VERSION ""

NS_ :

BS_:

BU_: SGW RFHM MPAD IPC GNMM EVCU2 ESL ECM DTCM DMSM BSM BCM AGSM ADCAM

BO_ 1470 BCM_FD_29: 32 BCM
 SG_ MessageCounter_BCM29 : 179|4@0+ (1,0) [0|15] "-"  MPAD
 SG_ DriverSeatRelativePosition : 95|8@0+ (1,-100) [-100|100] "%"  MPAD
 SG_ DriverSeatReclinerButton : 181|2@0+ (1,0) [0|2] "" MPAD
 SG_ DriverSeatHorizontalButton : 183|2@0+ (1,0) [0|2] "" MPAD
 SG_ DriverReclineRelativePosition : 103|8@0+ (1,-100) [-100|100] "%"  MPAD
 SG_ CRC_BCM29 : 191|8@0+ (1,0) [0|255] "-"  MPAD
 SG_ SeatPosHAS : 70|2@0+ (1,0) [0|3] "" MPAD

BO_ 1458 ADAS_FD_HMI_C2: 32 BCM
 SG_ MessageCounter_ADAS_HMI_C2 : 179|4@0+ (1,0) [0|15] "-"  BSM,IPC
 SG_ CRC_ADAS_HMI_C2 : 191|8@0+ (1,0) [0|255] "-"  BSM,IPC
 SG_ ACC_FailSts_C2 : 57|1@0+ (1,0) [0|1] "" BSM
 SG_ SVI_Request_C2_ext : 82|3@0+ (1,0) [0|7] "-"  IPC

BO_ 2564682036 DIAGNOSTIC_ROE_GNMM: 8 GNMM
 SG_ N_PDU : 7|64@0+ (1,0) [0|0] "" SGW

BO_ 2564682292 DIAGNOSTIC_ROE_FD_GNMM: 64 GNMM
 SG_ N_PDU : 7|64@0+ (1,0) [0|0] "" SGW

BO_ 2564682391 DIAGNOSTIC_ROE_FD_DMSM: 64 DMSM
 SG_ N_PDU : 7|64@0+ (1,0) [0|0] "" SGW

BO_ 2564682135 DIAGNOSTIC_ROE_DMSM: 8 DMSM
 SG_ N_PDU : 7|64@0+ (1,0) [0|0] "" SGW

BO_ 2564486416 DIAGNOSTIC_RESPONSE_FOTA_ECM: 64 ECM
 SG_ N_PDU : 7|64@0+ (1,0) [0|0] "" SGW

BO_ 2564486440 DIAGNOSTIC_RESPONSE_FOTA_BSM: 64 BSM
 SG_ N_PDU : 7|64@0+ (1,0) [0|0] "" SGW

BO_ 2564428021 DIAGNOSTIC_REQUEST_FOTA_ECM: 64 SGW
 SG_ N_PDU : 7|64@0+ (1,0) [0|0] "" ECM

BO_ 2564434165 DIAGNOSTIC_REQUEST_FOTA_BSM: 64 SGW
 SG_ N_PDU : 7|64@0+ (1,0) [0|0] "" BSM

BO_ 161 DBSM2_A1: 32 BCM
 SG_ undervoltage_detected : 5|1@0+ (1,0) [0|1] "" MPAD
 SG_ switch_status_OpenClose : 0|1@0+ (1,0) [0|1] "" MPAD
 SG_ RsErr_DBSM2 : 7|1@0+ (1,0) [0|1] "" MPAD
 SG_ overtemp_detected : 2|1@0+ (1,0) [0|1] "" MPAD
 SG_ overcurrent_detected : 4|1@0+ (1,0) [0|1] "" MPAD
 SG_ L2plus_ack : 6|1@0+ (1,0) [0|1] "" MPAD
 SG_ ESS_input_active : 1|1@0+ (1,0) [0|1] "" Vector__XXX
 SG_ DBSM2_internal_error : 3|1@0+ (1,0) [0|1] "" MPAD
 SG_ BATTERY2_voltage : 23|8@0+ (0.05,6) [6|18.7] "" Vector__XXX
 SG_ BATTERY_voltage : 15|8@0+ (0.05,6) [6|18.7] "" Vector__XXX
 SG_ MC_DBSM2_1 : 55|4@0+ (1,0) [0|15] "" MPAD
 SG_ CRC_DBSM2_1 : 63|8@0+ (1,0) [0|0] "" MPAD

BO_ 281 ADAS_FD_INFO_C2: 32 BCM
 SG_ MRM_STATUS_C2 : 52|3@0+ (1,0) [0|6] "" EVCU2,IPC
 SG_ MessageCounter_ADAS_INFO_C2 : 179|4@0+ (1,0) [0|15] "-"  BSM,IPC,EVCU2
 SG_ HAS_Status_C2 : 35|2@0+ (1,0) [0|3] "" BSM,IPC,DTCM
 SG_ CRC_ADAS_INFO_C2 : 191|8@0+ (1,0) [0|255] "-"  BSM,IPC,EVCU2
 SG_ AEB_Type_C2 : 39|4@0+ (1,0) [0|14] "" BSM
 SG_ Intervention_C2 : 3|12@0+ (0.01,-16) [-16|24.95] "m/s2"  BSM
 SG_ HIS_Req_C2 : 19|1@0+ (1,0) [0|1] "" BSM
 SG_ ACC_Systemsts_C2 : 23|4@0+ (1,0) [0|14] "" BSM
 SG_ CADM2_Mode : 33|1@0+ (1,0) [0|1] "" BSM

BO_ 280 ADAS_FD_INFO: 32 ADCAM
 SG_ Object_Dist : 127|8@0+ (1,0) [0|255] "m"  BCM,BSM
 SG_ MessageCounter_ADAS_FD_INFO : 179|4@0+ (1,0) [0|15] "-"  ADCAM,EVCU2,BCM,BSM,IPC
 SG_ CRC_ADAS_FD_INFO : 191|8@0+ (1,0) [0|255] "-"  ADCAM,EVCU2,BCM,BSM,IPC
 SG_ Intervention : 163|12@0+ (0.01,-16) [-16|24.95] "m/s2"  SGW,BCM,BSM
 SG_ HIS_Req : 89|1@0+ (1,0) [0|1] "-"  BCM,BSM
 SG_ GrMax_Rq_ACC : 150|4@0+ (1,0) [0|15] "-"  BCM,BSM
 SG_ CIPV_Fused : 101|1@0+ (1,0) [0|1] "-"  BCM,BSM
 SG_ Brake_Jerk_Req : 100|1@0+ (1,0) [0|1] "-"  BCM,BSM
 SG_ ACC_Engine_Torque_Enabled : 111|1@0+ (1,0) [0|1] "-"  BCM,BSM
 SG_ ACC_Drive_Cmd : 151|1@0+ (1,0) [0|1] "-"  BCM,BSM
 SG_ Prefill_Req : 91|1@0+ (1,0) [0|1] "-"  BCM,BSM
 SG_ PEB_SystemSts : 90|1@0+ (1,0) [0|1] "-"  BCM,BSM,IPC
 SG_ MRM_STATUS : 23|3@0+ (1,0) [0|6] "" EVCU2,SGW,BCM,BSM,IPC
 SG_ LANE_CHANGE_SIDE : 95|2@0+ (1,0) [0|2] "" BCM,BSM,IPC
 SG_ HAS_Status : 106|2@0+ (1,0) [0|3] "" BCM,BSM,IPC,DTCM
 SG_ HAS_OpStat_Prim : 4|3@0+ (1,0) [0|5] "" BCM,BSM
 SG_ HAS_LAT_CTRL_RequestSts : 110|2@0+ (1,0) [0|3] "-"  BCM,BSM
 SG_ ESCALATION_TYPE : 12|3@0+ (1,0) [0|4] "" BCM,BSM
 SG_ DDD_SystemSts : 103|1@0+ (1,0) [0|1] "-"  BCM,BSM
 SG_ DDD_Setting_Avail : 102|1@0+ (1,0) [0|1] "-"  BCM,BSM,IPC
 SG_ CADM_OpStat : 7|3@0+ (1,0) [0|5] "" BCM,BSM
 SG_ AEB_Type : 167|4@0+ (1,0) [0|14] "-"  BCM,BSM
 SG_ AEB_Systemsts : 99|2@0+ (1,0) [0|2] "-"  BCM,BSM,IPC
 SG_ AEB_Sensitivity_Setting : 1|2@0+ (1,0) [0|2] "" BCM,BSM,IPC
 SG_ ACC_Systemsts : 183|4@0+ (1,0) [0|14] "-"  BCM,BSM,IPC
 SG_ ACC_StopStart : 97|2@0+ (1,0) [0|2] "-"  BCM,BSM
 SG_ SteeringVibration_Type : 67|4@0+ (1,0) [0|14] "-"  BCM,BSM
 SG_ SteeringVibration_Rq : 135|1@0+ (1,0) [0|1] "-"  BCM,BSM
 SG_ LKA_LAT_CTRL_RequestSts : 108|2@0+ (1,0) [0|3] "-"  BCM,BSM
 SG_ LANE_CHANGE_STATUS : 71|4@0+ (1,0) [0|14] "" BCM,BSM,IPC
 SG_ SeatVib_Req : 15|3@0+ (1,0) [0|7] "" BCM,BSM
 SG_ LC_Jerk : 104|1@0+ (1,0) [0|1] "-"  BCM,BSM
 SG_ CADM2_EPSSEC_FAIL : 8|1@0+ (1,0) [0|1] "" BCM,BSM
 SG_ BlindSpot_TrailerSts : 20|3@0+ (1,0) [0|6] "-"  BCM,BSM,IPC
 SG_ TorqueOverlaySteeringReq : 130|11@0+ (0.0048828125,-5) [-5|4.995117188] "-"  BCM,BSM
 SG_ MAC_ADAS_FD_INFO : 215|48@0+ (1,0) [0|0] "-"  BCM,BSM
 SG_ Cntr_ADAS_FD_INFO : 199|16@0+ (1,0) [0|65535] "-"  BCM,BSM

BO_ 525 GLOB_NAV_FD: 64 GNMM
 SG_ VerticalAcceleration_GNMM : 35|12@0+ (0.02,-40.96) [-40.96|40.92] "m/s2"  MPAD,BCM
 SG_ RollRate_GNMM : 67|12@0+ (0.08,-163.84) [-163.84|163.68] "deg/s"  MPAD,BCM
 SG_ PitchRate_GNMM : 83|12@0+ (0.08,-163.84) [-163.84|163.68] "deg/s"  MPAD,BCM
 SG_ LongAcceleration_GNMM : 3|12@0+ (0.02,-40.96) [-40.96|40.92] "m/s2"  MPAD,BCM
 SG_ LatAcceleration_GNMM : 19|12@0+ (0.02,-40.96) [-40.96|40.92] "m/s2"  MPAD,BCM
 SG_ GNMM_Health : 7|4@0+ (1,0) [0|6] "" MPAD,BCM
 SG_ YawRate_RMSE : 119|8@0+ (2,0) [0|506] "deg"  MPAD,BCM
 SG_ Roll_RMSE : 151|8@0+ (2,0) [0|506] "deg"  MPAD,BCM
 SG_ Pitch_RMSE : 159|8@0+ (2,0) [0|506] "deg"  MPAD,BCM
 SG_ Longitude_RMSE : 111|8@0+ (2,0) [0|506] "cm"  MPAD,BCM
 SG_ Latitude_RMSE : 103|8@0+ (2,0) [0|506] "cm"  MPAD,BCM
 SG_ Heading_Angle : 127|16@0+ (0.01,0) [0|360] "deg"  MPAD,BCM
 SG_ Altitude_RMSE : 143|8@0+ (2,0) [0|506] "cm"  MPAD,BCM
 SG_ YawRate_GNMM : 166|15@0+ (0.01,-163.83) [-163.83|163.83] "deg/s"  MPAD,BCM
 SG_ VerticalVelocity_GNMM : 197|14@0+ (0.01,-81.92) [-81.92|81.9] "m/s"  MPAD,BCM
 SG_ MessageCounter_GLOB_NAV : 435|4@0+ (1,0) [0|15] "-"  MPAD,BCM
 SG_ LongitudinalVelocity_GNMM : 213|14@0+ (0.01,-81.92) [-81.92|81.9] "m/s"  MPAD,BCM
 SG_ LateralVelocity_GNMM : 181|14@0+ (0.01,-81.92) [-81.92|81.9] "m/s"  MPAD,BCM
 SG_ CRC_GLOB_NAV : 447|8@0+ (1,0) [0|255] "-"  MPAD,BCM
 SG_ Long_GNMM : 327|32@0+ (1E-07,-180) [-180|249.4967294] "deg"  MPAD,BCM
 SG_ Lat_GNMM : 407|32@0+ (5E-08,-90) [-90|124.7483647] "deg"  MPAD,BCM
 SG_ TimeStamp : 231|44@0+ (1,0) [0|17592186044415] "ms"  MPAD
 SG_ StbmTimestampSec_GNMM : 359|32@0+ (1,0) [0|4294967295] "sec"  MPAD
 SG_ StbmTimestampNSec_GNMM : 295|32@0+ (1,0) [0|4294967295] "nsec"  MPAD
 SG_ StbmSyncState_GNMM : 391|8@0+ (1,0) [0|255] "No_Unit"  MPAD
 SG_ StatusReceiver : 21|2@0+ (1,0) [0|3] "No_Unit"  MPAD
 SG_ NumOfSatellites : 267|4@0+ (1,0) [0|15] "No_Unit"  MPAD
 SG_ IMUTemperature : 59|8@0+ (1,-40) [-40|215] "Celsius"  MPAD
 SG_ HDOP : 55|12@0+ (0.01,0) [0|40.95] "No_Unit"  MPAD
 SG_ FixedStatusReceiver : 23|2@0+ (1,0) [0|3] "No_Unit"  MPAD
 SG_ CourseAngle : 279|16@0+ (0.01,0) [0|655.35] "deg"  MPAD
 SG_ Reserved_Func_Safety_GLOBNAV_2 : 439|4@0+ (1,0) [0|0] "" MPAD,BCM
 SG_ Reserved_for_Func_Safety_GLOBNAV : 399|8@0+ (1,0) [0|0] "" MPAD,BCM
 SG_ MAC_GLOB_NAV : 471|48@0+ (1,0) [0|0] "-"  MPAD,BCM
 SG_ Cntr_GLOB_NAV : 455|16@0+ (1,0) [0|0] "-"  MPAD,BCM

BO_ 2564682005 DIAGNOSTIC_ROE_MCPB: 8 EVCU2
 SG_ N_PDU : 7|64@0+ (1,0) [0|0] "" SGW

BO_ 2564682004 DIAGNOSTIC_ROE_MCPA: 8 EVCU2
 SG_ N_PDU : 7|64@0+ (1,0) [0|0] "" SGW

BO_ 2564682261 DIAGNOSTIC_ROE_FD_MCPB: 64 EVCU2
 SG_ N_PDU : 7|64@0+ (1,0) [0|0] "" SGW

BO_ 2564682260 DIAGNOSTIC_ROE_FD_MCPA: 64 EVCU2
 SG_ N_PDU : 7|64@0+ (1,0) [0|0] "" SGW

BO_ 2564485396 DIAGNOSTIC_RESPONSE_MCPA: 8 EVCU2
 SG_ N_PDU : 7|64@0+ (1,0) [0|0] "" SGW

BO_ 2564485653 DIAGNOSTIC_RESPONSE_FD_MCPB: 64 EVCU2
 SG_ N_PDU : 7|64@0+ (1,0) [0|0] "" SGW

BO_ 2564485652 DIAGNOSTIC_RESPONSE_FD_MCPA: 64 EVCU2
 SG_ N_PDU : 7|64@0+ (1,0) [0|0] "" SGW

BO_ 2564429297 DIAGNOSTIC_REQUEST_MCPB: 8 SGW
 SG_ N_PDU : 7|64@0+ (1,0) [0|0] "" EVCU2

BO_ 2564429041 DIAGNOSTIC_REQUEST_MCPA: 8 SGW
 SG_ N_PDU : 7|64@0+ (1,0) [0|0] "" EVCU2

BO_ 2564429298 DIAGNOSTIC_REQUEST_FD_MCPB: 64 SGW
 SG_ N_PDU : 7|64@0+ (1,0) [0|0] "" EVCU2

BO_ 2564429042 DIAGNOSTIC_REQUEST_FD_MCPA: 64 SGW
 SG_ N_PDU : 7|64@0+ (1,0) [0|0] "" EVCU2

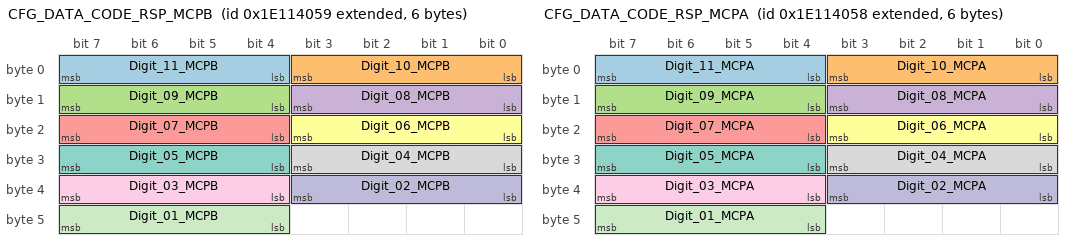
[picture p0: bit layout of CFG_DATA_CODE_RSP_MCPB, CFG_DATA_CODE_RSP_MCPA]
BO_ 2651930713 CFG_DATA_CODE_RSP_MCPB: 6 EVCU2
 SG_ Digit_11_MCPB : 7|4@0+ (1,0) [0|15] "-"  BCM
 SG_ Digit_10_MCPB : 3|4@0+ (1,0) [0|15] "-"  BCM
 SG_ Digit_09_MCPB : 15|4@0+ (1,0) [0|15] "-"  BCM
 SG_ Digit_08_MCPB : 11|4@0+ (1,0) [0|15] "-"  BCM
 SG_ Digit_07_MCPB : 23|4@0+ (1,0) [0|15] "-"  BCM
 SG_ Digit_06_MCPB : 19|4@0+ (1,0) [0|15] "-"  BCM
 SG_ Digit_05_MCPB : 31|4@0+ (1,0) [0|15] "-"  BCM
 SG_ Digit_04_MCPB : 27|4@0+ (1,0) [0|15] "-"  BCM
 SG_ Digit_03_MCPB : 39|4@0+ (1,0) [0|15] "-"  BCM
 SG_ Digit_02_MCPB : 35|4@0+ (1,0) [0|15] "-"  BCM
 SG_ Digit_01_MCPB : 47|4@0+ (1,0) [0|15] "-"  BCM

BO_ 2651930712 CFG_DATA_CODE_RSP_MCPA: 6 EVCU2
 SG_ Digit_11_MCPA : 7|4@0+ (1,0) [0|15] "-"  BCM
 SG_ Digit_10_MCPA : 3|4@0+ (1,0) [0|15] "-"  BCM
 SG_ Digit_09_MCPA : 15|4@0+ (1,0) [0|15] "-"  BCM
 SG_ Digit_08_MCPA : 11|4@0+ (1,0) [0|15] "-"  BCM
 SG_ Digit_07_MCPA : 23|4@0+ (1,0) [0|15] "-"  BCM
 SG_ Digit_06_MCPA : 19|4@0+ (1,0) [0|15] "-"  BCM
 SG_ Digit_05_MCPA : 31|4@0+ (1,0) [0|15] "-"  BCM
 SG_ Digit_04_MCPA : 27|4@0+ (1,0) [0|15] "-"  BCM
 SG_ Digit_03_MCPA : 39|4@0+ (1,0) [0|15] "-"  BCM
 SG_ Digit_02_MCPA : 35|4@0+ (1,0) [0|15] "-"  BCM
 SG_ Digit_01_MCPA : 47|4@0+ (1,0) [0|15] "-"  BCM

BO_ 2564485397 DIAGNOSTIC_RESPONSE_MCPB: 8 EVCU2
 SG_ N_PDU : 7|64@0+ (1,0) [0|0] "" SGW

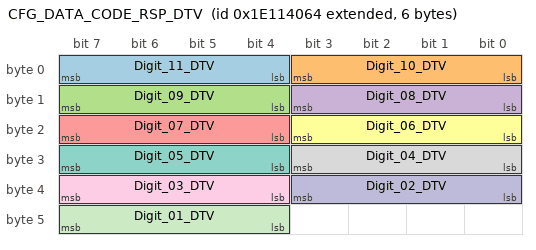
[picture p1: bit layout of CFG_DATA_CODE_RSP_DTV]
BO_ 2651930724 CFG_DATA_CODE_RSP_DTV: 6 SGW
 SG_ Digit_11_DTV : 7|4@0+ (1,0) [0|15] "-"  BCM
 SG_ Digit_10_DTV : 3|4@0+ (1,0) [0|15] "-"  BCM
 SG_ Digit_09_DTV : 15|4@0+ (1,0) [0|15] "-"  BCM
 SG_ Digit_08_DTV : 11|4@0+ (1,0) [0|15] "-"  BCM
 SG_ Digit_07_DTV : 23|4@0+ (1,0) [0|15] "-"  BCM
 SG_ Digit_06_DTV : 19|4@0+ (1,0) [0|15] "-"  BCM
 SG_ Digit_05_DTV : 31|4@0+ (1,0) [0|15] "-"  BCM
 SG_ Digit_04_DTV : 27|4@0+ (1,0) [0|15] "-"  BCM
 SG_ Digit_03_DTV : 39|4@0+ (1,0) [0|15] "-"  BCM
 SG_ Digit_02_DTV : 35|4@0+ (1,0) [0|15] "-"  BCM
 SG_ Digit_01_DTV : 47|4@0+ (1,0) [0|15] "-"  BCM

BO_ 728 VL_Object: 64 ADCAM
 SG_ Road_Illumination : 127|4@0+ (1,0) [0|15] "-"  BCM
 SG_ Obj04_Type : 111|4@0+ (1,0) [0|15] "-"  BCM
 SG_ Obj04_HorDist : 247|8@0+ (2,0) [0|510] "m"  BCM
 SG_ Obj03_Type : 71|4@0+ (1,0) [0|15] "-"  BCM
 SG_ Obj03_HorDist : 175|8@0+ (2,0) [0|510] "m"  BCM
 SG_ Obj02_Type : 55|4@0+ (1,0) [0|15] "-"  BCM
 SG_ Obj02_HorDist : 103|8@0+ (2,0) [0|510] "m"  BCM
 SG_ Obj01_Type : 39|4@0+ (1,0) [0|15] "-"  BCM
 SG_ Obj01_HorDist : 31|8@0+ (2,0) [0|510] "m"  BCM
 SG_ Cam_TrafficStyle : 19|4@0+ (1,0) [0|15] "-"  BCM
 SG_ Cam_Status : 23|4@0+ (1,0) [0|15] "-"  BCM
 SG_ Cam_SelfGlaring : 11|4@0+ (1,0) [0|15] "-"  BCM
 SG_ Cam_ObjNum : 15|4@0+ (1,0) [0|15] "-"  BCM
 SG_ Cam_Env : 3|4@0+ (1,0) [0|15] "-"  BCM
 SG_ Cam_AmbientLight : 7|4@0+ (1,0) [0|15] "-"  BCM
 SG_ Obj04_VerPos : 311|8@0+ (0.1,-12) [-12|13.5] "°"  BCM
 SG_ Obj04_ID : 303|8@0+ (1,0) [0|255] "-"  BCM
 SG_ Obj04_HorSpeed : 283|12@0+ (0.05,-40) [-40|164.75] "°/s"  BCM
 SG_ Obj04_HorPosRight : 267|12@0+ (0.05,-40) [-40|164.75] "°"  BCM
 SG_ Obj04_HorPosLeft : 251|12@0+ (0.05,-40) [-40|164.75] "°"  BCM
 SG_ Obj03_VerPos : 239|8@0+ (0.1,-12) [-12|13.5] "°"  BCM
 SG_ Obj03_ID : 231|8@0+ (1,0) [0|255] "-"  BCM
 SG_ Obj03_HorSpeed : 211|12@0+ (0.05,-40) [-40|164.75] "°/s"  BCM
 SG_ Obj03_HorPosRight : 195|12@0+ (0.05,-40) [-40|164.75] "°"  BCM
 SG_ Obj03_HorPosLeft : 179|12@0+ (0.05,-40) [-40|164.75] "°"  BCM
 SG_ Obj02_VerPos : 167|8@0+ (0.1,-12) [-12|13.5] "°"  BCM
 SG_ Obj02_ID : 159|8@0+ (1,0) [0|255] "-"  BCM
 SG_ Obj02_HorSpeed : 139|12@0+ (0.05,-40) [-40|164.75] "°/s"  BCM
 SG_ Obj02_HorPosRight : 123|12@0+ (0.05,-40) [-40|164.75] "°"  BCM
 SG_ Obj02_HorPosLeft : 107|12@0+ (0.05,-40) [-40|164.75] "°"  BCM
 SG_ Obj01_VerPos : 95|8@0+ (0.1,-12) [-12|13.5] "°"  BCM
 SG_ Obj01_ID : 87|8@0+ (1,0) [0|255] "-"  BCM
 SG_ Obj01_HorSpeed : 67|12@0+ (0.05,-40) [-40|164.75] "°/s"  BCM
 SG_ Obj01_HorPosRight : 51|12@0+ (0.05,-40) [-40|164.75] "°"  BCM
 SG_ Obj01_HorPosLeft : 35|12@0+ (0.05,-40) [-40|164.75] "°"  BCM

BO_TX_BU_ 280 : ADCAM,MPAD;
CM_ SG_ 1470 SeatPosHAS "SeatPosHAS";
CM_ SG_ 1470 MessageCounter_BCM29 "This signal is a counter used for safety checks strategies. This counter is incremented of 1 (one) unit at each frame transmission.";
CM_ SG_ 1470 DriverSeatRelativePosition "Relative position of the driver seat since highway assist was engaged";
CM_ SG_ 1470 DriverSeatReclinerButton "Driver seat recliner button press";
CM_ SG_ 1470 DriverSeatHorizontalButton "Driver seat horizontal button press";
CM_ SG_ 1470 DriverReclineRelativePosition "Relative position of the driver recliner since highway assist was engaged";
CM_ SG_ 1470 CRC_BCM29 "CRC according to SAE J1850 standard at each frame transmission.";
CM_ SG_ 1458 MessageCounter_ADAS_HMI_C2 "This signal is a counter used for safety checks strategies. This counter is incremented of 1 (one) unit at each frame transmission.";
CM_ SG_ 1458 SVI_Request_C2_ext "Cluster Glow";
CM_ SG_ 1458 CRC_ADAS_HMI_C2 "CRC according to SAE J1850 standard at each frame transmission.";
CM_ SG_ 1458 ACC_FailSts_C2 "ACC_FailSts_C2";
CM_ SG_ 2564682036 N_PDU "This signal is used for diagnostic purposes";
CM_ SG_ 2564682292 N_PDU "This signal is used for diagnostic purposes";
CM_ SG_ 2564682391 N_PDU "This signal is used for diagnostic purposes";
CM_ SG_ 2564682135 N_PDU "This signal is used for diagnostic purposes";
CM_ SG_ 2564486416 N_PDU "This signal is used for diagnostic purposes";
CM_ SG_ 2564486440 N_PDU "This signal is used for diagnostic purposes";
CM_ SG_ 2564428021 N_PDU "This signal is used for diagnostic purposes";
CM_ SG_ 2564434165 N_PDU "This signal is used for diagnostic purposes";
CM_ SG_ 161 BATTERY_voltage "input voltage 1 measured by DBSM2";
CM_ SG_ 161 BATTERY2_voltage "input voltage 2 measured by DBSM2";
CM_ SG_ 161 CRC_DBSM2_1 "CRC-checksum byte 1 to 7 according to SAE J1850";
CM_ SG_ 161 DBSM2_internal_error "memory/CPU/sensors (fault flag)";
CM_ SG_ 161 ESS_input_active "ESS input was active (low) during the last 10 seconds";
CM_ SG_ 161 L2plus_ack "DBSM2 confirms L2plus mode";
CM_ SG_ 161 MC_DBSM2_1 "Message counter";
CM_ SG_ 161 overcurrent_detected "over current detected (fault flag)";
CM_ SG_ 161 overtemp_detected "over temperature detected (fault flag)";
CM_ SG_ 161 RsErr_DBSM2 "Response error DBSM2; Error=[1]";
CM_ SG_ 161 switch_status_OpenClose "The switch was activated (open) at least one time during the last 10 seconds";
CM_ SG_ 161 undervoltage_detected "under voltage detected (fault flag)";
CM_ SG_ 281 Intervention_C2 "Intervention_C2";
CM_ SG_ 281 MessageCounter_ADAS_INFO_C2 "This signal is a counter used for safety checks strategies. This counter is incremented of 1 (one) unit at each frame transmission.";
CM_ SG_ 281 MRM_STATUS_C2 "Status of the minimum risk maneuver to handle system faults or driver abuse as understood by secondary controller";
CM_ SG_ 281 HAS_Status_C2 "Highway Assist System Status as reported by the failover controller";
CM_ SG_ 281 HIS_Req_C2 "HIS_Req_C2";
CM_ SG_ 281 CADM2_Mode "Mode CADM2 is currently functioning";
CM_ SG_ 281 CRC_ADAS_INFO_C2 "CRC according to SAE J1850 standard at each frame transmission.";
CM_ SG_ 281 ACC_Systemsts_C2 "ACC_Systemsts_C2";
CM_ SG_ 281 AEB_Type_C2 "AEB_Type_C2";
CM_ SG_ 280 ACC_StopStart "Allows StopStart when ACC is engaged";
CM_ SG_ 280 ACC_Drive_Cmd "ACC Drive Command";
CM_ SG_ 280 ACC_Engine_Torque_Enabled "An enable bit that Torque commands should be followed";
CM_ SG_ 280 ACC_Systemsts "ACC System Status";
CM_ SG_ 280 AEB_Sensitivity_Setting "AEB sensitivity status";
CM_ SG_ 280 AEB_Systemsts "AEB System Status";
CM_ SG_ 280 BlindSpot_TrailerSts "BlindSpot_TrailerSts";
CM_ SG_ 280 AEB_Type "AEB Type";
CM_ SG_ 280 Cntr_ADAS_FD_INFO "Cntr";
CM_ SG_ 280 Brake_Jerk_Req "Request from DASM to perform Jerk Warning";
CM_ SG_ 280 CADM_OpStat "Capability of primary controller to sense and compute a valid trajectory path based on external data dependencies and internal failures";
CM_ SG_ 280 CADM2_EPSSEC_FAIL "CADM2 detection of failure to communicate to EPS";
CM_ SG_ 280 CIPV_Fused "Closest in-path vehicle is fused True = 1";
CM_ SG_ 280 CRC_ADAS_FD_INFO "CRC according to SAE J1850 standard at each frame transmission.";
CM_ SG_ 280 HAS_OpStat_Prim "Capability of the primary controller to perform sensing, computing, and actuation";
CM_ SG_ 280 DDD_Setting_Avail "DDD_Setting Av Status";
CM_ SG_ 280 DDD_SystemSts "DDD System Status";
CM_ SG_ 280 ESCALATION_TYPE "Type of HMI escalation to be provided to driver from primary controller";
CM_ SG_ 280 GrMax_Rq_ACC "Used to request Max Gear from TCM";
CM_ SG_ 280 HAS_LAT_CTRL_RequestSts "HAS_LAT_CTRL_RequestSts";
CM_ SG_ 280 LC_Jerk "Lane Centering request for brake jerk";
CM_ SG_ 280 LKA_LAT_CTRL_RequestSts "LKA_LAT_CTRL_RequestSts";
CM_ SG_ 280 MessageCounter_ADAS_FD_INFO "This signal is a counter used for safety checks strategies. This counter is incremented of 1 (one) unit at each frame transmission.";
CM_ SG_ 280 Object_Dist "It indicates the distance to the recognized object";
CM_ SG_ 280 MRM_STATUS "Status of the minimum risk maneuver to handle system faults or driver abuse as understood by primary controller";
CM_ SG_ 280 HAS_Status "Highway Assist System Status as reported by the main controller";
CM_ SG_ 280 HIS_Req "Used to command Stop during Stop and Go ACC and FSFCW+";
CM_ SG_ 280 Intervention "Request to set target acceleration/deceleration for any feature";
CM_ SG_ 280 LANE_CHANGE_STATUS "Status of assisted lane change maneuver";
CM_ SG_ 280 LANE_CHANGE_SIDE "Direction of the currently in-progress lane change from a vehicle perspective";
CM_ SG_ 280 MAC_ADAS_FD_INFO "MAC";
CM_ SG_ 280 PEB_SystemSts "PEB System Status";
CM_ SG_ 280 Prefill_Req "Prefill command of Brake System by DASM";
CM_ SG_ 280 SeatVib_Req "Seat vibration request";
CM_ SG_ 280 SteeringVibration_Rq "Request to activate Steering Wheel Vibration";
CM_ SG_ 280 SteeringVibration_Type "Type of Steering Wheel Vibration Request";
CM_ SG_ 280 TorqueOverlaySteeringReq "TorqueOverlaySteeringReq";
CM_ SG_ 525 Altitude_RMSE "Altitude_RMSE";
CM_ SG_ 525 Cntr_GLOB_NAV "-";
CM_ SG_ 525 CourseAngle "Actual direction of motion over ground with respect to True North.";
CM_ SG_ 525 CRC_GLOB_NAV "CRC according to SAE J1850 standard at each frame transmission.";
CM_ SG_ 525 FixedStatusReceiver "This signal indicates the FIX status of the GNSS receiver.2D fix = 2-dimensional position can be calculated (horizontal plane)3D fix = 3-dimensional position can be calculated (including altitude)";
CM_ SG_ 525 GNMM_Health "Reported capability of GNMM to provide positioning and acceleration data";
CM_ SG_ 525 HDOP "Relative accuracy of horizontal position (Horizontal Dilution of Precision).";
CM_ SG_ 525 Heading_Angle "Heading Angle";
CM_ SG_ 525 IMUTemperature "Temperature of Yaw Rate secondary IMU sensor.";
CM_ SG_ 525 Lat_GNMM "Latitude decimal degrees, positive North of the equator";
CM_ SG_ 525 LatAcceleration_GNMM "Lateral Acceleration Value from the GNMM";
CM_ SG_ 525 LateralVelocity_GNMM "Lateral Velocity";
CM_ SG_ 525 Latitude_RMSE "RMS error for Latitude";
CM_ SG_ 525 Long_GNMM "Longitude decimal degrees, positive East of the prime meridian";
CM_ SG_ 525 LongAcceleration_GNMM "Longitudinal Acceleration Value from the GNMM";
CM_ SG_ 525 Longitude_RMSE "RMS error for Longitude";
CM_ SG_ 525 LongitudinalVelocity_GNMM "Longitudinal Velocity";
CM_ SG_ 525 MAC_GLOB_NAV "-";
CM_ SG_ 525 MessageCounter_GLOB_NAV "This signal is a counter used for safety checks strategies. This counter is incremented of 1 (one) unit at each frame transmission.";
CM_ SG_ 525 NumOfSatellites "Number of satellites available, if signal >=14 keep value=14.";
CM_ SG_ 525 Pitch_RMSE "Pitch_RMSE";
CM_ SG_ 525 PitchRate_GNMM "Pitch Rate Value from the GNMM";
CM_ SG_ 525 Roll_RMSE "Roll_RMSE";
CM_ SG_ 525 RollRate_GNMM "Roll Rate Value from the GNMM";
CM_ SG_ 525 StatusReceiver "This signal indicates the status of the GNSS receiver.";
CM_ SG_ 525 StbmSyncState_GNMM "Sync status of the GNMM Stbm";
CM_ SG_ 525 StbmTimestampNSec_GNMM "Timestamp in nanoseconds from the GNMM Stbm, [0 - 999999999].";
CM_ SG_ 525 StbmTimestampSec_GNMM "Timestamp in nanoseconds from the GNMM Stbm,  [0 - 4294967294].";
CM_ SG_ 525 TimeStamp "EPOCH UNIX time - time since 00:00:00 UTC, January 1, 1970 (Unix timestamp) in milliseconds.";
CM_ SG_ 525 VerticalAcceleration_GNMM "Vertical Acceleration Value from the GNMM";
CM_ SG_ 525 VerticalVelocity_GNMM "Vertical Velocity";
CM_ SG_ 525 YawRate_GNMM "Yaw Rate Value from the GNMM";
CM_ SG_ 525 YawRate_RMSE "RMS error for YawRate";
CM_ SG_ 2564682005 N_PDU "This signal is used for diagnostic purposes";
CM_ SG_ 2564682004 N_PDU "This signal is used for diagnostic purposes";
CM_ SG_ 2564682261 N_PDU "This signal is used for diagnostic purposes";
CM_ SG_ 2564682260 N_PDU "This signal is used for diagnostic purposes";
CM_ SG_ 2564485396 N_PDU "This signal is used for diagnostic purposes";
CM_ SG_ 2564485653 N_PDU "This signal is used for diagnostic purposes";
CM_ SG_ 2564485652 N_PDU "This signal is used for diagnostic purposes";
CM_ SG_ 2564429297 N_PDU "This signal is used for diagnostic purposes";
CM_ SG_ 2564429041 N_PDU "This signal is used for diagnostic purposes";
CM_ SG_ 2564429298 N_PDU "This signal is used for diagnostic purposes";
CM_ SG_ 2564429042 N_PDU "This signal is used for diagnostic purposes";
CM_ SG_ 2564485397 N_PDU "This signal is used for diagnostic purposes";
CM_ SG_ 728 Obj04_HorPosLeft "Left horizontal angle of each detected GFHB object representing the most left light source in relation to camera center.Camera shall measure the horizontal angle between the center of the camera (FOE) and the left edge of the most left light s(...)";
CM_ SG_ 728 Obj04_HorPosRight "Right horizontal angle of each detected GFHB object representing the most right light source in relation to camera center.Camera shall measure the horizontal angle between the center of the camera (FOE) and the right edge of the most right lig(...)";
CM_ SG_ 728 Obj04_HorDist "Longitudinal distance of each detected GFHB object.This signal is defining the longitudinal distance in meters between the ego vehicle and the releated GFHB object.";
CM_ SG_ 728 Cam_AmbientLight "Cam_AmbientLight";
CM_ SG_ 728 Cam_Env "CAN_Env";
CM_ SG_ 728 Cam_ObjNum "Cam_ObjNum";
CM_ SG_ 728 Cam_SelfGlaring "Cam_SelfGlaring";
CM_ SG_ 728 Cam_Status "Cam_Status";
CM_ SG_ 728 Cam_TrafficStyle "Cam_TrafficStyle";
CM_ SG_ 728 Obj01_HorDist "Longitudinal distance of each detected GFHB object.This signal is defining the longitudinal distance in meters between the ego vehicle and the releated GFHB object.";
CM_ SG_ 728 Obj01_HorPosLeft "Left horizontal angle of each detected GFHB object representing the most left light source in relation to camera center.Camera shall measure the horizontal angle between the center of the camera (FOE) and the left edge of the most left light s(...)";
CM_ SG_ 728 Obj01_HorPosRight "Right horizontal angle of each detected GFHB object representing the most right light source in relation to camera center.Camera shall measure the horizontal angle between the center of the camera (FOE) and the right edge of the most right lig(...)";
CM_ SG_ 728 Obj01_HorSpeed "Horizontal Speed of the center of each detected GFHB object.";
CM_ SG_ 728 Obj01_ID "Unique ID of each detected GFHB object which will stay the same over lifetime of each object even if it changes the message ID due to the sorting by distanceThe ID of a cluster will be always the ID of the closest (=strongest) vehicle in the c(...)";
CM_ SG_ 728 Obj01_Type "This signal is a counter used for safety checks strategies. This counter is incremented of 1 (one) unit at each frame transmission.";
CM_ SG_ 728 Obj01_VerPos "Vertical angle of each detected GFHB object representing the lowest edge of the lowest light source in relation to camera center";
CM_ SG_ 728 Obj02_HorDist "Longitudinal distance of each detected GFHB object.This signal is defining the longitudinal distance in meters between the ego vehicle and the releated GFHB object.";
CM_ SG_ 728 Obj02_HorPosLeft "Left horizontal angle of each detected GFHB object representing the most left light source in relation to camera center.Camera shall measure the horizontal angle between the center of the camera (FOE) and the left edge of the most left light s(...)";
CM_ SG_ 728 Obj02_HorPosRight "Right horizontal angle of each detected GFHB object representing the most right light source in relation to camera center.Camera shall measure the horizontal angle between the center of the camera (FOE) and the right edge of the most right lig(...)";
CM_ SG_ 728 Obj04_VerPos "Vertical angle of each detected GFHB object representing the lowest edge of the lowest light source in relation to camera center";
CM_ SG_ 728 Obj04_Type "This signal is a counter used for safety checks strategies. This counter is incremented of 1 (one) unit at each frame transmission.";
CM_ SG_ 728 Obj04_ID "Unique ID of each detected GFHB object which will stay the same over lifetime of each object even if it changes the message ID due to the sorting by distanceThe ID of a cluster will be always the ID of the closest (=strongest) vehicle in the c(...)";
CM_ SG_ 728 Obj03_ID "Unique ID of each detected GFHB object which will stay the same over lifetime of each object even if it changes the message ID due to the sorting by distanceThe ID of a cluster will be always the ID of the closest (=strongest) vehicle in the c(...)";
CM_ SG_ 728 Obj03_Type "This signal is a counter used for safety checks strategies. This counter is incremented of 1 (one) unit at each frame transmission.";
CM_ SG_ 728 Obj03_VerPos "Vertical angle of each detected GFHB object representing the lowest edge of the lowest light source in relation to camera center";
CM_ SG_ 728 Obj04_HorSpeed "Horizontal Speed of the center of each detected GFHB object.";
CM_ SG_ 728 Obj02_HorSpeed "Horizontal Speed of the center of each detected GFHB object.";
CM_ SG_ 728 Obj02_ID "Unique ID of each detected GFHB object which will stay the same over lifetime of each object even if it changes the message ID due to the sorting by distanceThe ID of a cluster will be always the ID of the closest (=strongest) vehicle in the c(...)";
CM_ SG_ 728 Obj02_Type "This signal is a counter used for safety checks strategies. This counter is incremented of 1 (one) unit at each frame transmission.";
CM_ SG_ 728 Obj02_VerPos "Vertical angle of each detected GFHB object representing the lowest edge of the lowest light source in relation to camera center";
CM_ SG_ 728 Obj03_HorDist "Longitudinal distance of each detected GFHB object.This signal is defining the longitudinal distance in meters between the ego vehicle and the releated GFHB object.";
CM_ SG_ 728 Obj03_HorPosLeft "Left horizontal angle of each detected GFHB object representing the most left light source in relation to camera center.Camera shall measure the horizontal angle between the center of the camera (FOE) and the left edge of the most left light s(...)";
CM_ SG_ 728 Obj03_HorPosRight "Right horizontal angle of each detected GFHB object representing the most right light source in relation to camera center.Camera shall measure the horizontal angle between the center of the camera (FOE) and the right edge of the most right lig(...)";
CM_ SG_ 728 Obj03_HorSpeed "Horizontal Speed of the center of each detected GFHB object.";
CM_ SG_ 728 Road_Illumination "Road_Illumination";
BA_DEF_ BO_ "CANFD_BRS" ENUM "0","1";
BA_DEF_ BO_ "VFrameFormat" ENUM "StandardCAN","ExtendedCAN","reserved","reserved","reserved","reserved","reserved","reserved","reserved","reserved","reserved","reserved","reserved","reserved","StandardCAN_FD","ExtendedCAN_FD";
BA_DEF_ BO_ "DiagConnection" HEX 0 65535;
BA_DEF_ BO_ "DiagState" ENUM "No","Yes";
BA_DEF_ BO_ "NmAsrMessage" ENUM "No","Yes";
BA_DEF_ BO_ "GenMsgDelayTime" INT 0 65535;
BA_DEF_ BO_ "GenMsgCycleTime" INT 0 65535;
BA_DEF_ BO_ "GenMsgCycleTimeFast" INT 0 65535;
BA_DEF_ BO_ "GenMsgStartDelayTime" INT 0 65535;
BA_DEF_ BO_ "GenMsgILSupport" ENUM "No","Yes";
BA_DEF_ BO_ "GenMsgNrOfRepetition" INT 0 255;
BA_DEF_ BO_ "GenMsgSendType" ENUM "Cyclic","NotUsed","NotUsed","NotUsed","NotUsed","NotUsed","NotUsed","NotUsed","NoMsgSendType";
BA_DEF_ BO_ "NmMessage" ENUM "No","Yes";
BA_DEF_ BO_ "DiagResponse" ENUM "No","Yes";
BA_DEF_ BO_ "Type" ENUM "P","C","PE","COC","PE_Cntrl","E","E_Cntrl","OC","S","BAF","DC","EM","MM","ISO-TP","-";
BA_DEF_ BO_ "DiagRequest" ENUM "No","Yes";
BA_DEF_ SG_ "GenSigTimeoutTime_SGW" INT 0 65535;
BA_DEF_ SG_ "GenSigTimeoutTime_RFHM" INT 0 65535;
BA_DEF_ SG_ "GenSigTimeoutTime_MPAD" INT 0 65535;
BA_DEF_ SG_ "GenSigTimeoutTime_IPC" INT 0 65535;
BA_DEF_ SG_ "GenSigTimeoutTime_GNMM" INT 0 65535;
BA_DEF_ SG_ "GenSigTimeoutTime_EVCU2" INT 0 65535;
BA_DEF_ SG_ "GenSigTimeoutTime_ESL" INT 0 65535;
BA_DEF_ SG_ "GenSigTimeoutTime_ECM" INT 0 65535;
BA_DEF_ SG_ "GenSigTimeoutTime_DTCM" INT 0 65535;
BA_DEF_ SG_ "GenSigTimeoutTime_DMSM" INT 0 65535;
BA_DEF_ SG_ "GenSigTimeoutTime_BSM" INT 0 65535;
BA_DEF_ SG_ "GenSigTimeoutTime_BCM" INT 0 65535;
BA_DEF_ SG_ "GenSigTimeoutTime_AGSM" INT 0 65535;
BA_DEF_ SG_ "GenSigTimeoutTime_ADCAM" INT 0 65535;
BA_DEF_ SG_ "SystemSignalLongSymbol" STRING ;
BA_DEF_ SG_ "GenSigSendType" ENUM "NotUsed","OnWrite","OnWriteWithRepetition","OnChange","OnChangeWithRepetition","IfActive","IfActiveWithRepetition","NoSigSendType";
BA_DEF_ SG_ "GenSigInactiveValue" INT 0 2147483647;
BA_DEF_ SG_ "GenSigStartValue" INT 0 2147483647;
BA_DEF_DEF_ "CANFD_BRS" "0";
BA_DEF_DEF_ "VFrameFormat" "StandardCAN_FD";
BA_DEF_DEF_ "DiagConnection" 0;
BA_DEF_DEF_ "DiagState" "No";
BA_DEF_DEF_ "NmAsrMessage" "No";
BA_DEF_DEF_ "GenMsgDelayTime" 0;
BA_DEF_DEF_ "GenMsgCycleTime" 0;
BA_DEF_DEF_ "GenMsgCycleTimeFast" 0;
BA_DEF_DEF_ "GenMsgStartDelayTime" 0;
BA_DEF_DEF_ "GenMsgILSupport" "No";
BA_DEF_DEF_ "GenMsgNrOfRepetition" 0;
BA_DEF_DEF_ "GenMsgSendType" "NoMsgSendType";
BA_DEF_DEF_ "NmMessage" "No";
BA_DEF_DEF_ "DiagResponse" "No";
BA_DEF_DEF_ "Type" "-";
BA_DEF_DEF_ "DiagRequest" "No";
BA_DEF_DEF_ "GenSigTimeoutTime_SGW" 2500;
BA_DEF_DEF_ "GenSigTimeoutTime_RFHM" 2500;
BA_DEF_DEF_ "GenSigTimeoutTime_MPAD" 2500;
BA_DEF_DEF_ "GenSigTimeoutTime_IPC" 2500;
BA_DEF_DEF_ "GenSigTimeoutTime_GNMM" 2500;
BA_DEF_DEF_ "GenSigTimeoutTime_EVCU2" 2500;
BA_DEF_DEF_ "GenSigTimeoutTime_ESL" 2500;
BA_DEF_DEF_ "GenSigTimeoutTime_ECM" 2500;
BA_DEF_DEF_ "GenSigTimeoutTime_DTCM" 2500;
BA_DEF_DEF_ "GenSigTimeoutTime_DMSM" 2500;
BA_DEF_DEF_ "GenSigTimeoutTime_BSM" 2500;
BA_DEF_DEF_ "GenSigTimeoutTime_BCM" 2500;
BA_DEF_DEF_ "GenSigTimeoutTime_AGSM" 2500;
BA_DEF_DEF_ "GenSigTimeoutTime_ADCAM" 2500;
BA_DEF_DEF_ "SystemSignalLongSymbol" "";
BA_DEF_DEF_ "GenSigSendType" "NoSigSendType";
BA_DEF_DEF_ "GenSigInactiveValue" 0;
BA_DEF_DEF_ "GenSigStartValue" 0;
BA_ "CANFD_BRS" BO_ 1470 1;
BA_ "GenMsgCycleTime" BO_ 1470 1000;
BA_ "GenMsgStartDelayTime" BO_ 1470 405;
BA_ "GenMsgILSupport" BO_ 1470 1;
BA_ "GenMsgSendType" BO_ 1470 0;
BA_ "Type" BO_ 1470 3;
BA_ "CANFD_BRS" BO_ 1458 1;
BA_ "GenMsgDelayTime" BO_ 1458 20;
BA_ "GenMsgCycleTime" BO_ 1458 100;
BA_ "GenMsgStartDelayTime" BO_ 1458 45;
BA_ "GenMsgILSupport" BO_ 1458 1;
BA_ "GenMsgSendType" BO_ 1458 0;
BA_ "Type" BO_ 1458 3;
BA_ "VFrameFormat" BO_ 2564682036 1;
BA_ "DiagConnection" BO_ 2564682036 61748;
BA_ "DiagResponse" BO_ 2564682036 1;
BA_ "Type" BO_ 2564682036 8;
BA_ "CANFD_BRS" BO_ 2564682292 1;
BA_ "VFrameFormat" BO_ 2564682292 15;
BA_ "DiagConnection" BO_ 2564682292 62004;
BA_ "DiagResponse" BO_ 2564682292 1;
BA_ "Type" BO_ 2564682292 8;
BA_ "CANFD_BRS" BO_ 2564682391 1;
BA_ "VFrameFormat" BO_ 2564682391 15;
BA_ "DiagConnection" BO_ 2564682391 62103;
BA_ "DiagResponse" BO_ 2564682391 1;
BA_ "Type" BO_ 2564682391 8;
BA_ "VFrameFormat" BO_ 2564682135 1;
BA_ "DiagConnection" BO_ 2564682135 61847;
BA_ "DiagResponse" BO_ 2564682135 1;
BA_ "Type" BO_ 2564682135 8;
BA_ "CANFD_BRS" BO_ 2564486416 1;
BA_ "VFrameFormat" BO_ 2564486416 15;
BA_ "DiagConnection" BO_ 2564486416 62736;
BA_ "DiagResponse" BO_ 2564486416 1;
BA_ "Type" BO_ 2564486416 8;
BA_ "CANFD_BRS" BO_ 2564486440 1;
BA_ "VFrameFormat" BO_ 2564486440 15;
BA_ "DiagConnection" BO_ 2564486440 62760;
BA_ "DiagResponse" BO_ 2564486440 1;
BA_ "Type" BO_ 2564486440 8;
BA_ "CANFD_BRS" BO_ 2564428021 1;
BA_ "VFrameFormat" BO_ 2564428021 15;
BA_ "DiagConnection" BO_ 2564428021 62736;
BA_ "Type" BO_ 2564428021 8;
BA_ "DiagRequest" BO_ 2564428021 1;
BA_ "CANFD_BRS" BO_ 2564434165 1;
BA_ "VFrameFormat" BO_ 2564434165 15;
BA_ "DiagConnection" BO_ 2564434165 62760;
BA_ "Type" BO_ 2564434165 8;
BA_ "DiagRequest" BO_ 2564434165 1;
BA_ "CANFD_BRS" BO_ 161 1;
BA_ "GenMsgILSupport" BO_ 161 1;
BA_ "Type" BO_ 161 8;
BA_ "GenMsgILSupport" BO_ 281 1;
BA_ "GenMsgSendType" BO_ 281 0;
BA_ "Type" BO_ 281 1;
BA_ "CANFD_BRS" BO_ 281 1;
BA_ "GenMsgCycleTime" BO_ 281 10;
BA_ "CANFD_BRS" BO_ 280 1;
BA_ "GenMsgCycleTime" BO_ 280 10;
BA_ "GenMsgILSupport" BO_ 280 1;
BA_ "GenMsgSendType" BO_ 280 0;
BA_ "Type" BO_ 280 1;
BA_ "CANFD_BRS" BO_ 525 1;
BA_ "GenMsgDelayTime" BO_ 525 20;
BA_ "GenMsgCycleTime" BO_ 525 20;
BA_ "GenMsgCycleTimeFast" BO_ 525 20;
BA_ "GenMsgILSupport" BO_ 525 1;
BA_ "GenMsgNrOfRepetition" BO_ 525 2;
BA_ "GenMsgSendType" BO_ 525 0;
BA_ "Type" BO_ 525 1;
BA_ "VFrameFormat" BO_ 2564682005 1;
BA_ "DiagConnection" BO_ 2564682005 61717;
BA_ "DiagResponse" BO_ 2564682005 1;
BA_ "Type" BO_ 2564682005 8;
BA_ "VFrameFormat" BO_ 2564682004 1;
BA_ "DiagConnection" BO_ 2564682004 61716;
BA_ "DiagResponse" BO_ 2564682004 1;
BA_ "Type" BO_ 2564682004 8;
BA_ "CANFD_BRS" BO_ 2564682261 1;
BA_ "VFrameFormat" BO_ 2564682261 15;
BA_ "DiagConnection" BO_ 2564682261 61973;
BA_ "DiagResponse" BO_ 2564682261 1;
BA_ "Type" BO_ 2564682261 8;
BA_ "DiagConnection" BO_ 2564682260 61972;
BA_ "DiagResponse" BO_ 2564682260 1;
BA_ "Type" BO_ 2564682260 8;
BA_ "CANFD_BRS" BO_ 2564682260 1;
BA_ "VFrameFormat" BO_ 2564682260 15;
BA_ "VFrameFormat" BO_ 2564485396 1;
BA_ "DiagConnection" BO_ 2564485396 61716;
BA_ "DiagResponse" BO_ 2564485396 1;
BA_ "Type" BO_ 2564485396 8;
BA_ "CANFD_BRS" BO_ 2564485653 1;
BA_ "VFrameFormat" BO_ 2564485653 15;
BA_ "DiagConnection" BO_ 2564485653 61973;
BA_ "DiagResponse" BO_ 2564485653 1;
BA_ "Type" BO_ 2564485653 8;
BA_ "CANFD_BRS" BO_ 2564485652 1;
BA_ "VFrameFormat" BO_ 2564485652 15;
BA_ "DiagConnection" BO_ 2564485652 61972;
BA_ "DiagResponse" BO_ 2564485652 1;
BA_ "Type" BO_ 2564485652 8;
BA_ "VFrameFormat" BO_ 2564429297 1;
BA_ "DiagConnection" BO_ 2564429297 61717;
BA_ "Type" BO_ 2564429297 8;
BA_ "DiagRequest" BO_ 2564429297 1;
BA_ "VFrameFormat" BO_ 2564429041 1;
BA_ "DiagConnection" BO_ 2564429041 61716;
BA_ "Type" BO_ 2564429041 8;
BA_ "DiagRequest" BO_ 2564429041 1;
BA_ "CANFD_BRS" BO_ 2564429298 1;
BA_ "VFrameFormat" BO_ 2564429298 15;
BA_ "DiagConnection" BO_ 2564429298 61973;
BA_ "Type" BO_ 2564429298 8;
BA_ "DiagRequest" BO_ 2564429298 1;
BA_ "CANFD_BRS" BO_ 2564429042 1;
BA_ "VFrameFormat" BO_ 2564429042 15;
BA_ "DiagConnection" BO_ 2564429042 61972;
BA_ "Type" BO_ 2564429042 8;
BA_ "DiagRequest" BO_ 2564429042 1;
BA_ "CANFD_BRS" BO_ 2651930713 1;
BA_ "VFrameFormat" BO_ 2651930713 15;
BA_ "GenMsgILSupport" BO_ 2651930713 1;
BA_ "Type" BO_ 2651930713 11;
BA_ "CANFD_BRS" BO_ 2651930712 1;
BA_ "VFrameFormat" BO_ 2651930712 15;
BA_ "GenMsgILSupport" BO_ 2651930712 1;
BA_ "Type" BO_ 2651930712 11;
BA_ "VFrameFormat" BO_ 2564485397 1;
BA_ "DiagConnection" BO_ 2564485397 61717;
BA_ "DiagResponse" BO_ 2564485397 1;
BA_ "Type" BO_ 2564485397 8;
BA_ "Type" BO_ 2651930724 11;
BA_ "CANFD_BRS" BO_ 2651930724 1;
BA_ "VFrameFormat" BO_ 2651930724 15;
BA_ "GenMsgILSupport" BO_ 2651930724 1;
BA_ "CANFD_BRS" BO_ 728 1;
BA_ "GenMsgCycleTime" BO_ 728 40;
BA_ "GenMsgILSupport" BO_ 728 1;
BA_ "GenMsgSendType" BO_ 728 0;
BA_ "Type" BO_ 728 1;
BA_ "GenSigTimeoutTime_SGW" SG_ 2564682005 N_PDU 0;
BA_ "GenSigTimeoutTime_RFHM" SG_ 2564682005 N_PDU 0;
BA_ "GenSigTimeoutTime_MPAD" SG_ 2564682005 N_PDU 0;
BA_ "GenSigTimeoutTime_IPC" SG_ 2564682005 N_PDU 0;
BA_ "GenSigTimeoutTime_GNMM" SG_ 2564682005 N_PDU 0;
BA_ "GenSigTimeoutTime_EVCU2" SG_ 2564682005 N_PDU 0;
BA_ "GenSigTimeoutTime_ESL" SG_ 2564682005 N_PDU 0;
BA_ "GenSigTimeoutTime_ECM" SG_ 2564682005 N_PDU 0;
BA_ "GenSigTimeoutTime_DTCM" SG_ 2564682005 N_PDU 0;
BA_ "GenSigTimeoutTime_DMSM" SG_ 2564682005 N_PDU 0;
BA_ "GenSigTimeoutTime_BSM" SG_ 2564682005 N_PDU 0;
BA_ "GenSigTimeoutTime_BCM" SG_ 2564682005 N_PDU 0;
BA_ "GenSigTimeoutTime_AGSM" SG_ 2564682005 N_PDU 0;
BA_ "GenSigTimeoutTime_ADCAM" SG_ 2564682005 N_PDU 0;
BA_ "GenSigTimeoutTime_SGW" SG_ 2564682004 N_PDU 0;
BA_ "GenSigTimeoutTime_RFHM" SG_ 2564682004 N_PDU 0;
BA_ "GenSigTimeoutTime_MPAD" SG_ 2564682004 N_PDU 0;
BA_ "GenSigTimeoutTime_IPC" SG_ 2564682004 N_PDU 0;
BA_ "GenSigTimeoutTime_GNMM" SG_ 2564682004 N_PDU 0;
BA_ "GenSigTimeoutTime_EVCU2" SG_ 2564682004 N_PDU 0;
BA_ "GenSigTimeoutTime_ESL" SG_ 2564682004 N_PDU 0;
BA_ "GenSigTimeoutTime_ECM" SG_ 2564682004 N_PDU 0;
BA_ "GenSigTimeoutTime_DTCM" SG_ 2564682004 N_PDU 0;
BA_ "GenSigTimeoutTime_DMSM" SG_ 2564682004 N_PDU 0;
BA_ "GenSigTimeoutTime_BSM" SG_ 2564682004 N_PDU 0;
BA_ "GenSigTimeoutTime_BCM" SG_ 2564682004 N_PDU 0;
BA_ "GenSigTimeoutTime_AGSM" SG_ 2564682004 N_PDU 0;
BA_ "GenSigTimeoutTime_ADCAM" SG_ 2564682004 N_PDU 0;
BA_ "GenSigTimeoutTime_SGW" SG_ 2564682036 N_PDU 0;
BA_ "GenSigTimeoutTime_RFHM" SG_ 2564682036 N_PDU 0;
BA_ "GenSigTimeoutTime_MPAD" SG_ 2564682036 N_PDU 0;
BA_ "GenSigTimeoutTime_IPC" SG_ 2564682036 N_PDU 0;
BA_ "GenSigTimeoutTime_GNMM" SG_ 2564682036 N_PDU 0;
BA_ "GenSigTimeoutTime_EVCU2" SG_ 2564682036 N_PDU 0;
BA_ "GenSigTimeoutTime_ESL" SG_ 2564682036 N_PDU 0;
BA_ "GenSigTimeoutTime_ECM" SG_ 2564682036 N_PDU 0;
BA_ "GenSigTimeoutTime_DTCM" SG_ 2564682036 N_PDU 0;
BA_ "GenSigTimeoutTime_DMSM" SG_ 2564682036 N_PDU 0;
BA_ "GenSigTimeoutTime_BSM" SG_ 2564682036 N_PDU 0;
BA_ "GenSigTimeoutTime_BCM" SG_ 2564682036 N_PDU 0;
BA_ "GenSigTimeoutTime_AGSM" SG_ 2564682036 N_PDU 0;
BA_ "GenSigTimeoutTime_ADCAM" SG_ 2564682036 N_PDU 0;
BA_ "GenSigTimeoutTime_SGW" SG_ 2564682261 N_PDU 0;
BA_ "GenSigTimeoutTime_RFHM" SG_ 2564682261 N_PDU 0;
BA_ "GenSigTimeoutTime_MPAD" SG_ 2564682261 N_PDU 0;
BA_ "GenSigTimeoutTime_IPC" SG_ 2564682261 N_PDU 0;
BA_ "GenSigTimeoutTime_GNMM" SG_ 2564682261 N_PDU 0;
BA_ "GenSigTimeoutTime_EVCU2" SG_ 2564682261 N_PDU 0;
BA_ "GenSigTimeoutTime_ESL" SG_ 2564682261 N_PDU 0;
BA_ "GenSigTimeoutTime_ECM" SG_ 2564682261 N_PDU 0;
BA_ "GenSigTimeoutTime_DTCM" SG_ 2564682261 N_PDU 0;
BA_ "GenSigTimeoutTime_DMSM" SG_ 2564682261 N_PDU 0;
BA_ "GenSigTimeoutTime_BSM" SG_ 2564682261 N_PDU 0;
BA_ "GenSigTimeoutTime_BCM" SG_ 2564682261 N_PDU 0;
BA_ "GenSigTimeoutTime_AGSM" SG_ 2564682261 N_PDU 0;
BA_ "GenSigTimeoutTime_ADCAM" SG_ 2564682261 N_PDU 0;
BA_ "GenSigTimeoutTime_SGW" SG_ 2564682260 N_PDU 0;
BA_ "GenSigTimeoutTime_RFHM" SG_ 2564682260 N_PDU 0;
BA_ "GenSigTimeoutTime_MPAD" SG_ 2564682260 N_PDU 0;
BA_ "GenSigTimeoutTime_IPC" SG_ 2564682260 N_PDU 0;
BA_ "GenSigTimeoutTime_GNMM" SG_ 2564682260 N_PDU 0;
BA_ "GenSigTimeoutTime_EVCU2" SG_ 2564682260 N_PDU 0;
BA_ "GenSigTimeoutTime_ESL" SG_ 2564682260 N_PDU 0;
BA_ "GenSigTimeoutTime_ECM" SG_ 2564682260 N_PDU 0;
BA_ "GenSigTimeoutTime_DTCM" SG_ 2564682260 N_PDU 0;
BA_ "GenSigTimeoutTime_DMSM" SG_ 2564682260 N_PDU 0;
BA_ "GenSigTimeoutTime_BSM" SG_ 2564682260 N_PDU 0;
BA_ "GenSigTimeoutTime_BCM" SG_ 2564682260 N_PDU 0;
BA_ "GenSigTimeoutTime_AGSM" SG_ 2564682260 N_PDU 0;
BA_ "GenSigTimeoutTime_ADCAM" SG_ 2564682260 N_PDU 0;
BA_ "GenSigTimeoutTime_RFHM" SG_ 2564682292 N_PDU 0;
BA_ "GenSigTimeoutTime_MPAD" SG_ 2564682292 N_PDU 0;
BA_ "GenSigTimeoutTime_IPC" SG_ 2564682292 N_PDU 0;
BA_ "GenSigTimeoutTime_GNMM" SG_ 2564682292 N_PDU 0;
BA_ "GenSigTimeoutTime_EVCU2" SG_ 2564682292 N_PDU 0;
BA_ "GenSigTimeoutTime_ESL" SG_ 2564682292 N_PDU 0;
BA_ "GenSigTimeoutTime_ECM" SG_ 2564682292 N_PDU 0;
BA_ "GenSigTimeoutTime_DTCM" SG_ 2564682292 N_PDU 0;
BA_ "GenSigTimeoutTime_DMSM" SG_ 2564682292 N_PDU 0;
BA_ "GenSigTimeoutTime_BSM" SG_ 2564682292 N_PDU 0;
BA_ "GenSigTimeoutTime_BCM" SG_ 2564682292 N_PDU 0;
BA_ "GenSigTimeoutTime_AGSM" SG_ 2564682292 N_PDU 0;
BA_ "GenSigTimeoutTime_ADCAM" SG_ 2564682292 N_PDU 0;
BA_ "GenSigTimeoutTime_SGW" SG_ 2564682292 N_PDU 0;
BA_ "GenSigTimeoutTime_SGW" SG_ 2564682391 N_PDU 0;
BA_ "GenSigTimeoutTime_RFHM" SG_ 2564682391 N_PDU 0;
BA_ "GenSigTimeoutTime_MPAD" SG_ 2564682391 N_PDU 0;
BA_ "GenSigTimeoutTime_IPC" SG_ 2564682391 N_PDU 0;
BA_ "GenSigTimeoutTime_GNMM" SG_ 2564682391 N_PDU 0;
BA_ "GenSigTimeoutTime_EVCU2" SG_ 2564682391 N_PDU 0;
BA_ "GenSigTimeoutTime_ESL" SG_ 2564682391 N_PDU 0;
BA_ "GenSigTimeoutTime_ECM" SG_ 2564682391 N_PDU 0;
BA_ "GenSigTimeoutTime_DTCM" SG_ 2564682391 N_PDU 0;
BA_ "GenSigTimeoutTime_DMSM" SG_ 2564682391 N_PDU 0;
BA_ "GenSigTimeoutTime_BSM" SG_ 2564682391 N_PDU 0;
BA_ "GenSigTimeoutTime_BCM" SG_ 2564682391 N_PDU 0;
BA_ "GenSigTimeoutTime_AGSM" SG_ 2564682391 N_PDU 0;
BA_ "GenSigTimeoutTime_ADCAM" SG_ 2564682391 N_PDU 0;
BA_ "GenSigTimeoutTime_SGW" SG_ 2564682135 N_PDU 0;
BA_ "GenSigTimeoutTime_RFHM" SG_ 2564682135 N_PDU 0;
BA_ "GenSigTimeoutTime_MPAD" SG_ 2564682135 N_PDU 0;
BA_ "GenSigTimeoutTime_IPC" SG_ 2564682135 N_PDU 0;
BA_ "GenSigTimeoutTime_GNMM" SG_ 2564682135 N_PDU 0;
BA_ "GenSigTimeoutTime_EVCU2" SG_ 2564682135 N_PDU 0;
BA_ "GenSigTimeoutTime_ESL" SG_ 2564682135 N_PDU 0;
BA_ "GenSigTimeoutTime_ECM" SG_ 2564682135 N_PDU 0;
BA_ "GenSigTimeoutTime_DTCM" SG_ 2564682135 N_PDU 0;
BA_ "GenSigTimeoutTime_DMSM" SG_ 2564682135 N_PDU 0;
BA_ "GenSigTimeoutTime_BSM" SG_ 2564682135 N_PDU 0;
BA_ "GenSigTimeoutTime_BCM" SG_ 2564682135 N_PDU 0;
BA_ "GenSigTimeoutTime_AGSM" SG_ 2564682135 N_PDU 0;
BA_ "GenSigTimeoutTime_ADCAM" SG_ 2564682135 N_PDU 0;
BA_ "GenSigTimeoutTime_SGW" SG_ 2564486416 N_PDU 0;
BA_ "GenSigTimeoutTime_RFHM" SG_ 2564486416 N_PDU 0;
BA_ "GenSigTimeoutTime_MPAD" SG_ 2564486416 N_PDU 0;
BA_ "GenSigTimeoutTime_IPC" SG_ 2564486416 N_PDU 0;
BA_ "GenSigTimeoutTime_GNMM" SG_ 2564486416 N_PDU 0;
BA_ "GenSigTimeoutTime_EVCU2" SG_ 2564486416 N_PDU 0;
BA_ "GenSigTimeoutTime_ESL" SG_ 2564486416 N_PDU 0;
BA_ "GenSigTimeoutTime_ECM" SG_ 2564486416 N_PDU 0;
BA_ "GenSigTimeoutTime_DTCM" SG_ 2564486416 N_PDU 0;
BA_ "GenSigTimeoutTime_DMSM" SG_ 2564486416 N_PDU 0;
BA_ "GenSigTimeoutTime_BSM" SG_ 2564486416 N_PDU 0;
BA_ "GenSigTimeoutTime_BCM" SG_ 2564486416 N_PDU 0;
BA_ "GenSigTimeoutTime_AGSM" SG_ 2564486416 N_PDU 0;
BA_ "GenSigTimeoutTime_ADCAM" SG_ 2564486416 N_PDU 0;
BA_ "GenSigTimeoutTime_SGW" SG_ 2564486440 N_PDU 0;
BA_ "GenSigTimeoutTime_RFHM" SG_ 2564486440 N_PDU 0;
BA_ "GenSigTimeoutTime_MPAD" SG_ 2564486440 N_PDU 0;
BA_ "GenSigTimeoutTime_IPC" SG_ 2564486440 N_PDU 0;
BA_ "GenSigTimeoutTime_GNMM" SG_ 2564486440 N_PDU 0;
BA_ "GenSigTimeoutTime_EVCU2" SG_ 2564486440 N_PDU 0;
BA_ "GenSigTimeoutTime_ESL" SG_ 2564486440 N_PDU 0;
BA_ "GenSigTimeoutTime_ECM" SG_ 2564486440 N_PDU 0;
BA_ "GenSigTimeoutTime_DTCM" SG_ 2564486440 N_PDU 0;
BA_ "GenSigTimeoutTime_DMSM" SG_ 2564486440 N_PDU 0;
BA_ "GenSigTimeoutTime_BSM" SG_ 2564486440 N_PDU 0;
BA_ "GenSigTimeoutTime_BCM" SG_ 2564486440 N_PDU 0;
BA_ "GenSigTimeoutTime_AGSM" SG_ 2564486440 N_PDU 0;
BA_ "GenSigTimeoutTime_ADCAM" SG_ 2564486440 N_PDU 0;
BA_ "GenSigTimeoutTime_SGW" SG_ 2564485397 N_PDU 0;
BA_ "GenSigTimeoutTime_RFHM" SG_ 2564485397 N_PDU 0;
BA_ "GenSigTimeoutTime_MPAD" SG_ 2564485397 N_PDU 0;
BA_ "GenSigTimeoutTime_IPC" SG_ 2564485397 N_PDU 0;
BA_ "GenSigTimeoutTime_GNMM" SG_ 2564485397 N_PDU 0;
BA_ "GenSigTimeoutTime_EVCU2" SG_ 2564485397 N_PDU 0;
BA_ "GenSigTimeoutTime_ESL" SG_ 2564485397 N_PDU 0;
BA_ "GenSigTimeoutTime_ECM" SG_ 2564485397 N_PDU 0;
BA_ "GenSigTimeoutTime_DTCM" SG_ 2564485397 N_PDU 0;
BA_ "GenSigTimeoutTime_DMSM" SG_ 2564485397 N_PDU 0;
BA_ "GenSigTimeoutTime_BSM" SG_ 2564485397 N_PDU 0;
BA_ "GenSigTimeoutTime_BCM" SG_ 2564485397 N_PDU 0;
BA_ "GenSigTimeoutTime_AGSM" SG_ 2564485397 N_PDU 0;
BA_ "GenSigTimeoutTime_ADCAM" SG_ 2564485397 N_PDU 0;
BA_ "GenSigTimeoutTime_SGW" SG_ 2564485396 N_PDU 0;
BA_ "GenSigTimeoutTime_RFHM" SG_ 2564485396 N_PDU 0;
BA_ "GenSigTimeoutTime_MPAD" SG_ 2564485396 N_PDU 0;
BA_ "GenSigTimeoutTime_IPC" SG_ 2564485396 N_PDU 0;
BA_ "GenSigTimeoutTime_GNMM" SG_ 2564485396 N_PDU 0;
BA_ "GenSigTimeoutTime_EVCU2" SG_ 2564485396 N_PDU 0;
BA_ "GenSigTimeoutTime_ESL" SG_ 2564485396 N_PDU 0;
BA_ "GenSigTimeoutTime_ECM" SG_ 2564485396 N_PDU 0;
BA_ "GenSigTimeoutTime_DTCM" SG_ 2564485396 N_PDU 0;
BA_ "GenSigTimeoutTime_DMSM" SG_ 2564485396 N_PDU 0;
BA_ "GenSigTimeoutTime_BSM" SG_ 2564485396 N_PDU 0;
BA_ "GenSigTimeoutTime_BCM" SG_ 2564485396 N_PDU 0;
BA_ "GenSigTimeoutTime_AGSM" SG_ 2564485396 N_PDU 0;
BA_ "GenSigTimeoutTime_ADCAM" SG_ 2564485396 N_PDU 0;
BA_ "GenSigTimeoutTime_SGW" SG_ 2564429297 N_PDU 0;
BA_ "GenSigTimeoutTime_RFHM" SG_ 2564429297 N_PDU 0;
BA_ "GenSigTimeoutTime_MPAD" SG_ 2564429297 N_PDU 0;
BA_ "GenSigTimeoutTime_IPC" SG_ 2564429297 N_PDU 0;
BA_ "GenSigTimeoutTime_GNMM" SG_ 2564429297 N_PDU 0;
BA_ "GenSigTimeoutTime_EVCU2" SG_ 2564429297 N_PDU 0;
BA_ "GenSigTimeoutTime_ESL" SG_ 2564429297 N_PDU 0;
BA_ "GenSigTimeoutTime_ECM" SG_ 2564429297 N_PDU 0;
BA_ "GenSigTimeoutTime_DTCM" SG_ 2564429297 N_PDU 0;
BA_ "GenSigTimeoutTime_DMSM" SG_ 2564429297 N_PDU 0;
BA_ "GenSigTimeoutTime_BSM" SG_ 2564429297 N_PDU 0;
BA_ "GenSigTimeoutTime_BCM" SG_ 2564429297 N_PDU 0;
BA_ "GenSigTimeoutTime_AGSM" SG_ 2564429297 N_PDU 0;
BA_ "GenSigTimeoutTime_ADCAM" SG_ 2564429297 N_PDU 0;
BA_ "GenSigTimeoutTime_SGW" SG_ 2564429041 N_PDU 0;
BA_ "GenSigTimeoutTime_RFHM" SG_ 2564429041 N_PDU 0;
BA_ "GenSigTimeoutTime_MPAD" SG_ 2564429041 N_PDU 0;
BA_ "GenSigTimeoutTime_IPC" SG_ 2564429041 N_PDU 0;
BA_ "GenSigTimeoutTime_GNMM" SG_ 2564429041 N_PDU 0;
BA_ "GenSigTimeoutTime_EVCU2" SG_ 2564429041 N_PDU 0;
BA_ "GenSigTimeoutTime_ESL" SG_ 2564429041 N_PDU 0;
BA_ "GenSigTimeoutTime_ECM" SG_ 2564429041 N_PDU 0;
BA_ "GenSigTimeoutTime_DTCM" SG_ 2564429041 N_PDU 0;
BA_ "GenSigTimeoutTime_DMSM" SG_ 2564429041 N_PDU 0;
BA_ "GenSigTimeoutTime_BSM" SG_ 2564429041 N_PDU 0;
BA_ "GenSigTimeoutTime_BCM" SG_ 2564429041 N_PDU 0;
BA_ "GenSigTimeoutTime_AGSM" SG_ 2564429041 N_PDU 0;
BA_ "GenSigTimeoutTime_ADCAM" SG_ 2564429041 N_PDU 0;
BA_ "GenSigTimeoutTime_SGW" SG_ 2564429298 N_PDU 0;
BA_ "GenSigTimeoutTime_RFHM" SG_ 2564429298 N_PDU 0;
BA_ "GenSigTimeoutTime_MPAD" SG_ 2564429298 N_PDU 0;
BA_ "GenSigTimeoutTime_IPC" SG_ 2564429298 N_PDU 0;
BA_ "GenSigTimeoutTime_GNMM" SG_ 2564429298 N_PDU 0;
BA_ "GenSigTimeoutTime_EVCU2" SG_ 2564429298 N_PDU 0;
BA_ "GenSigTimeoutTime_ESL" SG_ 2564429298 N_PDU 0;
BA_ "GenSigTimeoutTime_ECM" SG_ 2564429298 N_PDU 0;
BA_ "GenSigTimeoutTime_DTCM" SG_ 2564429298 N_PDU 0;
BA_ "GenSigTimeoutTime_DMSM" SG_ 2564429298 N_PDU 0;
BA_ "GenSigTimeoutTime_BSM" SG_ 2564429298 N_PDU 0;
BA_ "GenSigTimeoutTime_BCM" SG_ 2564429298 N_PDU 0;
BA_ "GenSigTimeoutTime_AGSM" SG_ 2564429298 N_PDU 0;
BA_ "GenSigTimeoutTime_ADCAM" SG_ 2564429298 N_PDU 0;
BA_ "GenSigTimeoutTime_SGW" SG_ 2564429042 N_PDU 0;
BA_ "GenSigTimeoutTime_RFHM" SG_ 2564429042 N_PDU 0;
BA_ "GenSigTimeoutTime_MPAD" SG_ 2564429042 N_PDU 0;
BA_ "GenSigTimeoutTime_IPC" SG_ 2564429042 N_PDU 0;
BA_ "GenSigTimeoutTime_GNMM" SG_ 2564429042 N_PDU 0;
BA_ "GenSigTimeoutTime_EVCU2" SG_ 2564429042 N_PDU 0;
BA_ "GenSigTimeoutTime_ESL" SG_ 2564429042 N_PDU 0;
BA_ "GenSigTimeoutTime_ECM" SG_ 2564429042 N_PDU 0;
BA_ "GenSigTimeoutTime_DTCM" SG_ 2564429042 N_PDU 0;
BA_ "GenSigTimeoutTime_DMSM" SG_ 2564429042 N_PDU 0;
BA_ "GenSigTimeoutTime_BSM" SG_ 2564429042 N_PDU 0;
BA_ "GenSigTimeoutTime_BCM" SG_ 2564429042 N_PDU 0;
BA_ "GenSigTimeoutTime_AGSM" SG_ 2564429042 N_PDU 0;
BA_ "GenSigTimeoutTime_ADCAM" SG_ 2564429042 N_PDU 0;
BA_ "GenSigTimeoutTime_SGW" SG_ 2564428021 N_PDU 0;
BA_ "GenSigTimeoutTime_RFHM" SG_ 2564428021 N_PDU 0;
BA_ "GenSigTimeoutTime_MPAD" SG_ 2564428021 N_PDU 0;
BA_ "GenSigTimeoutTime_IPC" SG_ 2564428021 N_PDU 0;
BA_ "GenSigTimeoutTime_GNMM" SG_ 2564428021 N_PDU 0;
BA_ "GenSigTimeoutTime_EVCU2" SG_ 2564428021 N_PDU 0;
BA_ "GenSigTimeoutTime_ESL" SG_ 2564428021 N_PDU 0;
BA_ "GenSigTimeoutTime_ECM" SG_ 2564428021 N_PDU 0;
BA_ "GenSigTimeoutTime_DTCM" SG_ 2564428021 N_PDU 0;
BA_ "GenSigTimeoutTime_DMSM" SG_ 2564428021 N_PDU 0;
BA_ "GenSigTimeoutTime_BSM" SG_ 2564428021 N_PDU 0;
BA_ "GenSigTimeoutTime_BCM" SG_ 2564428021 N_PDU 0;
BA_ "GenSigTimeoutTime_AGSM" SG_ 2564428021 N_PDU 0;
BA_ "GenSigTimeoutTime_ADCAM" SG_ 2564428021 N_PDU 0;
BA_ "GenSigTimeoutTime_SGW" SG_ 2564434165 N_PDU 0;
BA_ "GenSigTimeoutTime_RFHM" SG_ 2564434165 N_PDU 0;
BA_ "GenSigTimeoutTime_MPAD" SG_ 2564434165 N_PDU 0;
BA_ "GenSigTimeoutTime_IPC" SG_ 2564434165 N_PDU 0;
BA_ "GenSigTimeoutTime_GNMM" SG_ 2564434165 N_PDU 0;
BA_ "GenSigTimeoutTime_EVCU2" SG_ 2564434165 N_PDU 0;
BA_ "GenSigTimeoutTime_ESL" SG_ 2564434165 N_PDU 0;
BA_ "GenSigTimeoutTime_ECM" SG_ 2564434165 N_PDU 0;
BA_ "GenSigTimeoutTime_DTCM" SG_ 2564434165 N_PDU 0;
BA_ "GenSigTimeoutTime_DMSM" SG_ 2564434165 N_PDU 0;
BA_ "GenSigTimeoutTime_BSM" SG_ 2564434165 N_PDU 0;
BA_ "GenSigTimeoutTime_BCM" SG_ 2564434165 N_PDU 0;
BA_ "GenSigTimeoutTime_AGSM" SG_ 2564434165 N_PDU 0;
BA_ "GenSigTimeoutTime_ADCAM" SG_ 2564434165 N_PDU 0;
BA_ "GenSigTimeoutTime_ECM" SG_ 281 CRC_ADAS_INFO_C2 0;
BA_ "GenSigTimeoutTime_DTCM" SG_ 281 CRC_ADAS_INFO_C2 0;
BA_ "GenSigTimeoutTime_DMSM" SG_ 281 CRC_ADAS_INFO_C2 0;
BA_ "GenSigTimeoutTime_BCM" SG_ 281 CRC_ADAS_INFO_C2 0;
BA_ "GenSigTimeoutTime_AGSM" SG_ 281 CRC_ADAS_INFO_C2 0;
BA_ "GenSigTimeoutTime_ADCAM" SG_ 281 CRC_ADAS_INFO_C2 0;
BA_ "GenSigTimeoutTime_SGW" SG_ 281 AEB_Type_C2 0;
BA_ "GenSigTimeoutTime_RFHM" SG_ 281 AEB_Type_C2 0;
BA_ "GenSigTimeoutTime_MPAD" SG_ 281 AEB_Type_C2 0;
BA_ "GenSigTimeoutTime_IPC" SG_ 281 AEB_Type_C2 0;
BA_ "GenSigTimeoutTime_GNMM" SG_ 281 AEB_Type_C2 0;
BA_ "GenSigTimeoutTime_EVCU2" SG_ 281 AEB_Type_C2 0;
BA_ "GenSigTimeoutTime_ESL" SG_ 281 AEB_Type_C2 0;
BA_ "GenSigTimeoutTime_ECM" SG_ 281 AEB_Type_C2 0;
BA_ "GenSigTimeoutTime_DTCM" SG_ 281 AEB_Type_C2 0;
BA_ "GenSigTimeoutTime_DMSM" SG_ 281 AEB_Type_C2 0;
BA_ "GenSigTimeoutTime_BCM" SG_ 281 AEB_Type_C2 0;
BA_ "GenSigTimeoutTime_AGSM" SG_ 281 AEB_Type_C2 0;
BA_ "GenSigTimeoutTime_ADCAM" SG_ 281 AEB_Type_C2 0;
BA_ "GenSigTimeoutTime_SGW" SG_ 280 Prefill_Req 0;
BA_ "GenSigTimeoutTime_RFHM" SG_ 280 Prefill_Req 0;
BA_ "GenSigTimeoutTime_MPAD" SG_ 280 Prefill_Req 0;
BA_ "GenSigTimeoutTime_IPC" SG_ 280 Prefill_Req 0;
BA_ "GenSigTimeoutTime_GNMM" SG_ 280 Prefill_Req 0;
BA_ "GenSigTimeoutTime_EVCU2" SG_ 280 Prefill_Req 0;
BA_ "GenSigTimeoutTime_ESL" SG_ 280 Prefill_Req 0;
BA_ "GenSigTimeoutTime_ECM" SG_ 280 Prefill_Req 0;
BA_ "GenSigTimeoutTime_DTCM" SG_ 280 Prefill_Req 0;
BA_ "GenSigTimeoutTime_DMSM" SG_ 280 Prefill_Req 0;
BA_ "GenSigTimeoutTime_AGSM" SG_ 280 Prefill_Req 0;
BA_ "GenSigTimeoutTime_ADCAM" SG_ 280 Prefill_Req 0;
BA_ "GenSigTimeoutTime_SGW" SG_ 281 HAS_Status_C2 0;
BA_ "GenSigTimeoutTime_RFHM" SG_ 281 HAS_Status_C2 0;
BA_ "GenSigTimeoutTime_MPAD" SG_ 281 HAS_Status_C2 0;
BA_ "GenSigTimeoutTime_GNMM" SG_ 281 HAS_Status_C2 0;
BA_ "GenSigTimeoutTime_EVCU2" SG_ 281 HAS_Status_C2 0;
BA_ "GenSigTimeoutTime_ESL" SG_ 281 HAS_Status_C2 0;
BA_ "GenSigTimeoutTime_ECM" SG_ 281 HAS_Status_C2 0;
BA_ "GenSigTimeoutTime_DMSM" SG_ 281 HAS_Status_C2 0;
BA_ "GenSigTimeoutTime_BCM" SG_ 281 HAS_Status_C2 0;
BA_ "GenSigTimeoutTime_AGSM" SG_ 281 HAS_Status_C2 0;
BA_ "GenSigTimeoutTime_ADCAM" SG_ 281 HAS_Status_C2 0;
BA_ "GenSigTimeoutTime_ECM" SG_ 280 PEB_SystemSts 0;
BA_ "GenSigTimeoutTime_DTCM" SG_ 280 PEB_SystemSts 0;
BA_ "GenSigTimeoutTime_DMSM" SG_ 280 PEB_SystemSts 0;
BA_ "GenSigTimeoutTime_AGSM" SG_ 280 PEB_SystemSts 0;
BA_ "GenSigTimeoutTime_ADCAM" SG_ 280 PEB_SystemSts 0;
BA_ "GenSigTimeoutTime_SGW" SG_ 280 PEB_SystemSts 0;
BA_ "GenSigTimeoutTime_RFHM" SG_ 280 PEB_SystemSts 0;
BA_ "GenSigTimeoutTime_MPAD" SG_ 280 PEB_SystemSts 0;
BA_ "GenSigTimeoutTime_GNMM" SG_ 280 PEB_SystemSts 0;
BA_ "GenSigTimeoutTime_EVCU2" SG_ 280 PEB_SystemSts 0;
BA_ "GenSigTimeoutTime_ESL" SG_ 280 PEB_SystemSts 0;
BA_ "GenSigTimeoutTime_RFHM" SG_ 280 MRM_STATUS 0;
BA_ "GenSigTimeoutTime_MPAD" SG_ 280 MRM_STATUS 0;
BA_ "GenSigTimeoutTime_GNMM" SG_ 280 MRM_STATUS 0;
BA_ "GenSigTimeoutTime_ESL" SG_ 280 MRM_STATUS 0;
BA_ "GenSigTimeoutTime_ECM" SG_ 280 MRM_STATUS 0;
BA_ "GenSigTimeoutTime_DTCM" SG_ 280 MRM_STATUS 0;
BA_ "GenSigTimeoutTime_DMSM" SG_ 280 MRM_STATUS 0;
BA_ "GenSigTimeoutTime_AGSM" SG_ 280 MRM_STATUS 0;
BA_ "GenSigTimeoutTime_ADCAM" SG_ 280 MRM_STATUS 0;
BA_ "GenSigTimeoutTime_SGW" SG_ 280 SteeringVibration_Type 0;
BA_ "GenSigTimeoutTime_RFHM" SG_ 280 SteeringVibration_Type 0;
BA_ "GenSigTimeoutTime_MPAD" SG_ 280 SteeringVibration_Type 0;
BA_ "GenSigTimeoutTime_IPC" SG_ 280 SteeringVibration_Type 0;
BA_ "GenSigTimeoutTime_GNMM" SG_ 280 SteeringVibration_Type 0;
BA_ "GenSigTimeoutTime_EVCU2" SG_ 280 SteeringVibration_Type 0;
BA_ "GenSigTimeoutTime_ESL" SG_ 280 SteeringVibration_Type 0;
BA_ "GenSigTimeoutTime_ECM" SG_ 280 SteeringVibration_Type 0;
BA_ "GenSigTimeoutTime_DTCM" SG_ 280 SteeringVibration_Type 0;
BA_ "GenSigTimeoutTime_DMSM" SG_ 280 SteeringVibration_Type 0;
BA_ "GenSigTimeoutTime_AGSM" SG_ 280 SteeringVibration_Type 0;
BA_ "GenSigTimeoutTime_ADCAM" SG_ 280 SteeringVibration_Type 0;
BA_ "GenSigTimeoutTime_SGW" SG_ 280 SteeringVibration_Rq 0;
BA_ "GenSigTimeoutTime_RFHM" SG_ 280 SteeringVibration_Rq 0;
BA_ "GenSigTimeoutTime_MPAD" SG_ 280 SteeringVibration_Rq 0;
BA_ "GenSigTimeoutTime_IPC" SG_ 280 SteeringVibration_Rq 0;
BA_ "GenSigTimeoutTime_GNMM" SG_ 280 SteeringVibration_Rq 0;
BA_ "GenSigTimeoutTime_EVCU2" SG_ 280 SteeringVibration_Rq 0;
BA_ "GenSigTimeoutTime_ESL" SG_ 280 SteeringVibration_Rq 0;
BA_ "GenSigTimeoutTime_ECM" SG_ 280 SteeringVibration_Rq 0;
BA_ "GenSigTimeoutTime_DTCM" SG_ 280 SteeringVibration_Rq 0;
BA_ "GenSigTimeoutTime_DMSM" SG_ 280 SteeringVibration_Rq 0;
BA_ "GenSigTimeoutTime_AGSM" SG_ 280 SteeringVibration_Rq 0;
BA_ "GenSigTimeoutTime_ADCAM" SG_ 280 SteeringVibration_Rq 0;
BA_ "GenSigTimeoutTime_SGW" SG_ 280 TorqueOverlaySteeringReq 0;
BA_ "GenSigTimeoutTime_RFHM" SG_ 280 TorqueOverlaySteeringReq 0;
BA_ "GenSigTimeoutTime_MPAD" SG_ 280 TorqueOverlaySteeringReq 0;
BA_ "GenSigTimeoutTime_IPC" SG_ 280 TorqueOverlaySteeringReq 0;
BA_ "GenSigTimeoutTime_GNMM" SG_ 280 TorqueOverlaySteeringReq 0;
BA_ "GenSigTimeoutTime_EVCU2" SG_ 280 TorqueOverlaySteeringReq 0;
BA_ "GenSigTimeoutTime_ESL" SG_ 280 TorqueOverlaySteeringReq 0;
BA_ "GenSigTimeoutTime_ECM" SG_ 280 TorqueOverlaySteeringReq 0;
BA_ "GenSigTimeoutTime_DTCM" SG_ 280 TorqueOverlaySteeringReq 0;
BA_ "GenSigTimeoutTime_DMSM" SG_ 280 TorqueOverlaySteeringReq 0;
BA_ "GenSigTimeoutTime_AGSM" SG_ 280 TorqueOverlaySteeringReq 0;
BA_ "GenSigTimeoutTime_ADCAM" SG_ 280 TorqueOverlaySteeringReq 0;
BA_ "GenSigStartValue" SG_ 280 TorqueOverlaySteeringReq 1024;
BA_ "GenSigTimeoutTime_SGW" SG_ 281 CADM2_Mode 0;
BA_ "GenSigTimeoutTime_RFHM" SG_ 281 CADM2_Mode 0;
BA_ "GenSigTimeoutTime_MPAD" SG_ 281 CADM2_Mode 0;
BA_ "GenSigTimeoutTime_IPC" SG_ 281 CADM2_Mode 0;
BA_ "GenSigTimeoutTime_GNMM" SG_ 281 CADM2_Mode 0;
BA_ "GenSigTimeoutTime_EVCU2" SG_ 281 CADM2_Mode 0;
BA_ "GenSigTimeoutTime_ESL" SG_ 281 CADM2_Mode 0;
BA_ "GenSigTimeoutTime_ECM" SG_ 281 CADM2_Mode 0;
BA_ "GenSigTimeoutTime_DTCM" SG_ 281 CADM2_Mode 0;
BA_ "GenSigTimeoutTime_DMSM" SG_ 281 CADM2_Mode 0;
BA_ "GenSigTimeoutTime_BCM" SG_ 281 CADM2_Mode 0;
BA_ "GenSigTimeoutTime_AGSM" SG_ 281 CADM2_Mode 0;
BA_ "GenSigTimeoutTime_ADCAM" SG_ 281 CADM2_Mode 0;
BA_ "GenSigTimeoutTime_SGW" SG_ 281 Intervention_C2 0;
BA_ "GenSigTimeoutTime_RFHM" SG_ 281 Intervention_C2 0;
BA_ "GenSigTimeoutTime_MPAD" SG_ 281 Intervention_C2 0;
BA_ "GenSigTimeoutTime_IPC" SG_ 281 Intervention_C2 0;
BA_ "GenSigTimeoutTime_GNMM" SG_ 281 Intervention_C2 0;
BA_ "GenSigTimeoutTime_EVCU2" SG_ 281 Intervention_C2 0;
BA_ "GenSigTimeoutTime_ESL" SG_ 281 Intervention_C2 0;
BA_ "GenSigTimeoutTime_ECM" SG_ 281 Intervention_C2 0;
BA_ "GenSigTimeoutTime_DTCM" SG_ 281 Intervention_C2 0;
BA_ "GenSigTimeoutTime_DMSM" SG_ 281 Intervention_C2 0;
BA_ "GenSigTimeoutTime_BCM" SG_ 281 Intervention_C2 0;
BA_ "GenSigTimeoutTime_AGSM" SG_ 281 Intervention_C2 0;
BA_ "GenSigTimeoutTime_ADCAM" SG_ 281 Intervention_C2 0;
BA_ "GenSigStartValue" SG_ 281 Intervention_C2 4095;
BA_ "GenSigTimeoutTime_SGW" SG_ 281 HIS_Req_C2 0;
BA_ "GenSigTimeoutTime_RFHM" SG_ 281 HIS_Req_C2 0;
BA_ "GenSigTimeoutTime_MPAD" SG_ 281 HIS_Req_C2 0;
BA_ "GenSigTimeoutTime_IPC" SG_ 281 HIS_Req_C2 0;
BA_ "GenSigTimeoutTime_GNMM" SG_ 281 HIS_Req_C2 0;
BA_ "GenSigTimeoutTime_EVCU2" SG_ 281 HIS_Req_C2 0;
BA_ "GenSigTimeoutTime_ESL" SG_ 281 HIS_Req_C2 0;
BA_ "GenSigTimeoutTime_ECM" SG_ 281 HIS_Req_C2 0;
BA_ "GenSigTimeoutTime_DTCM" SG_ 281 HIS_Req_C2 0;
BA_ "GenSigTimeoutTime_DMSM" SG_ 281 HIS_Req_C2 0;
BA_ "GenSigTimeoutTime_BCM" SG_ 281 HIS_Req_C2 0;
BA_ "GenSigTimeoutTime_AGSM" SG_ 281 HIS_Req_C2 0;
BA_ "GenSigTimeoutTime_ADCAM" SG_ 281 HIS_Req_C2 0;
BA_ "GenSigTimeoutTime_SGW" SG_ 281 ACC_Systemsts_C2 0;
BA_ "GenSigTimeoutTime_RFHM" SG_ 281 ACC_Systemsts_C2 0;
BA_ "GenSigTimeoutTime_MPAD" SG_ 281 ACC_Systemsts_C2 0;
BA_ "GenSigTimeoutTime_IPC" SG_ 281 ACC_Systemsts_C2 0;
BA_ "GenSigTimeoutTime_GNMM" SG_ 281 ACC_Systemsts_C2 0;
BA_ "GenSigTimeoutTime_EVCU2" SG_ 281 ACC_Systemsts_C2 0;
BA_ "GenSigTimeoutTime_ESL" SG_ 281 ACC_Systemsts_C2 0;
BA_ "GenSigTimeoutTime_ECM" SG_ 281 ACC_Systemsts_C2 0;
BA_ "GenSigTimeoutTime_DTCM" SG_ 281 ACC_Systemsts_C2 0;
BA_ "GenSigTimeoutTime_DMSM" SG_ 281 ACC_Systemsts_C2 0;
BA_ "GenSigTimeoutTime_BCM" SG_ 281 ACC_Systemsts_C2 0;
BA_ "GenSigTimeoutTime_AGSM" SG_ 281 ACC_Systemsts_C2 0;
BA_ "GenSigTimeoutTime_ADCAM" SG_ 281 ACC_Systemsts_C2 0;
BA_ "GenSigTimeoutTime_SGW" SG_ 280 SeatVib_Req 0;
BA_ "GenSigTimeoutTime_RFHM" SG_ 280 SeatVib_Req 0;
BA_ "GenSigTimeoutTime_MPAD" SG_ 280 SeatVib_Req 0;
BA_ "GenSigTimeoutTime_IPC" SG_ 280 SeatVib_Req 0;
BA_ "GenSigTimeoutTime_GNMM" SG_ 280 SeatVib_Req 0;
BA_ "GenSigTimeoutTime_EVCU2" SG_ 280 SeatVib_Req 0;
BA_ "GenSigTimeoutTime_ESL" SG_ 280 SeatVib_Req 0;
BA_ "GenSigTimeoutTime_ECM" SG_ 280 SeatVib_Req 0;
BA_ "GenSigTimeoutTime_DTCM" SG_ 280 SeatVib_Req 0;
BA_ "GenSigTimeoutTime_DMSM" SG_ 280 SeatVib_Req 0;
BA_ "GenSigTimeoutTime_AGSM" SG_ 280 SeatVib_Req 0;
BA_ "GenSigTimeoutTime_ADCAM" SG_ 280 SeatVib_Req 0;
BA_ "GenSigTimeoutTime_SGW" SG_ 280 LC_Jerk 0;
BA_ "GenSigTimeoutTime_RFHM" SG_ 280 LC_Jerk 0;
BA_ "GenSigTimeoutTime_MPAD" SG_ 280 LC_Jerk 0;
BA_ "GenSigTimeoutTime_IPC" SG_ 280 LC_Jerk 0;
BA_ "GenSigTimeoutTime_GNMM" SG_ 280 LC_Jerk 0;
BA_ "GenSigTimeoutTime_EVCU2" SG_ 280 LC_Jerk 0;
BA_ "GenSigTimeoutTime_ESL" SG_ 280 LC_Jerk 0;
BA_ "GenSigTimeoutTime_ECM" SG_ 280 LC_Jerk 0;
BA_ "GenSigTimeoutTime_DTCM" SG_ 280 LC_Jerk 0;
BA_ "GenSigTimeoutTime_DMSM" SG_ 280 LC_Jerk 0;
BA_ "GenSigTimeoutTime_AGSM" SG_ 280 LC_Jerk 0;
BA_ "GenSigTimeoutTime_ADCAM" SG_ 280 LC_Jerk 0;
BA_ "GenSigTimeoutTime_IPC" SG_ 280 CADM2_EPSSEC_FAIL 0;
BA_ "GenSigTimeoutTime_GNMM" SG_ 280 CADM2_EPSSEC_FAIL 0;
BA_ "GenSigTimeoutTime_EVCU2" SG_ 280 CADM2_EPSSEC_FAIL 0;
BA_ "GenSigTimeoutTime_ESL" SG_ 280 CADM2_EPSSEC_FAIL 0;
BA_ "GenSigTimeoutTime_ECM" SG_ 280 CADM2_EPSSEC_FAIL 0;
BA_ "GenSigTimeoutTime_DTCM" SG_ 280 CADM2_EPSSEC_FAIL 0;
BA_ "GenSigTimeoutTime_DMSM" SG_ 280 CADM2_EPSSEC_FAIL 0;
BA_ "GenSigTimeoutTime_AGSM" SG_ 280 CADM2_EPSSEC_FAIL 0;
BA_ "GenSigTimeoutTime_ADCAM" SG_ 280 CADM2_EPSSEC_FAIL 0;
BA_ "GenSigTimeoutTime_SGW" SG_ 280 CADM2_EPSSEC_FAIL 0;
BA_ "GenSigTimeoutTime_RFHM" SG_ 280 CADM2_EPSSEC_FAIL 0;
BA_ "GenSigTimeoutTime_MPAD" SG_ 280 CADM2_EPSSEC_FAIL 0;
BA_ "GenSigTimeoutTime_SGW" SG_ 280 LKA_LAT_CTRL_RequestSts 0;
BA_ "GenSigTimeoutTime_RFHM" SG_ 280 LKA_LAT_CTRL_RequestSts 0;
BA_ "GenSigTimeoutTime_MPAD" SG_ 280 LKA_LAT_CTRL_RequestSts 0;
BA_ "GenSigTimeoutTime_IPC" SG_ 280 LKA_LAT_CTRL_RequestSts 0;
BA_ "GenSigTimeoutTime_GNMM" SG_ 280 LKA_LAT_CTRL_RequestSts 0;
BA_ "GenSigTimeoutTime_EVCU2" SG_ 280 LKA_LAT_CTRL_RequestSts 0;
BA_ "GenSigTimeoutTime_ESL" SG_ 280 LKA_LAT_CTRL_RequestSts 0;
BA_ "GenSigTimeoutTime_ECM" SG_ 280 LKA_LAT_CTRL_RequestSts 0;
BA_ "GenSigTimeoutTime_DTCM" SG_ 280 LKA_LAT_CTRL_RequestSts 0;
BA_ "GenSigTimeoutTime_DMSM" SG_ 280 LKA_LAT_CTRL_RequestSts 0;
BA_ "GenSigTimeoutTime_AGSM" SG_ 280 LKA_LAT_CTRL_RequestSts 0;
BA_ "GenSigTimeoutTime_ADCAM" SG_ 280 LKA_LAT_CTRL_RequestSts 0;
BA_ "GenSigTimeoutTime_SGW" SG_ 280 LANE_CHANGE_STATUS 0;
BA_ "GenSigTimeoutTime_RFHM" SG_ 280 LANE_CHANGE_STATUS 0;
BA_ "GenSigTimeoutTime_MPAD" SG_ 280 LANE_CHANGE_STATUS 0;
BA_ "GenSigTimeoutTime_GNMM" SG_ 280 LANE_CHANGE_STATUS 0;
BA_ "GenSigTimeoutTime_EVCU2" SG_ 280 LANE_CHANGE_STATUS 0;
BA_ "GenSigTimeoutTime_ESL" SG_ 280 LANE_CHANGE_STATUS 0;
BA_ "GenSigTimeoutTime_ECM" SG_ 280 LANE_CHANGE_STATUS 0;
BA_ "GenSigTimeoutTime_DTCM" SG_ 280 LANE_CHANGE_STATUS 0;
BA_ "GenSigTimeoutTime_DMSM" SG_ 280 LANE_CHANGE_STATUS 0;
BA_ "GenSigTimeoutTime_AGSM" SG_ 280 LANE_CHANGE_STATUS 0;
BA_ "GenSigTimeoutTime_ADCAM" SG_ 280 LANE_CHANGE_STATUS 0;
BA_ "GenSigTimeoutTime_SGW" SG_ 280 LANE_CHANGE_SIDE 0;
BA_ "GenSigTimeoutTime_RFHM" SG_ 280 LANE_CHANGE_SIDE 0;
BA_ "GenSigTimeoutTime_MPAD" SG_ 280 LANE_CHANGE_SIDE 0;
BA_ "GenSigTimeoutTime_GNMM" SG_ 280 LANE_CHANGE_SIDE 0;
BA_ "GenSigTimeoutTime_EVCU2" SG_ 280 LANE_CHANGE_SIDE 0;
BA_ "GenSigTimeoutTime_ESL" SG_ 280 LANE_CHANGE_SIDE 0;
BA_ "GenSigTimeoutTime_ECM" SG_ 280 LANE_CHANGE_SIDE 0;
BA_ "GenSigTimeoutTime_DTCM" SG_ 280 LANE_CHANGE_SIDE 0;
BA_ "GenSigTimeoutTime_DMSM" SG_ 280 LANE_CHANGE_SIDE 0;
BA_ "GenSigTimeoutTime_AGSM" SG_ 280 LANE_CHANGE_SIDE 0;
BA_ "GenSigTimeoutTime_ADCAM" SG_ 280 LANE_CHANGE_SIDE 0;
BA_ "GenSigTimeoutTime_SGW" SG_ 280 HAS_OpStat_Prim 0;
BA_ "GenSigTimeoutTime_RFHM" SG_ 280 HAS_OpStat_Prim 0;
BA_ "GenSigTimeoutTime_MPAD" SG_ 280 HAS_OpStat_Prim 0;
BA_ "GenSigTimeoutTime_IPC" SG_ 280 HAS_OpStat_Prim 0;
BA_ "GenSigTimeoutTime_GNMM" SG_ 280 HAS_OpStat_Prim 0;
BA_ "GenSigTimeoutTime_EVCU2" SG_ 280 HAS_OpStat_Prim 0;
BA_ "GenSigTimeoutTime_ESL" SG_ 280 HAS_OpStat_Prim 0;
BA_ "GenSigTimeoutTime_ECM" SG_ 280 HAS_OpStat_Prim 0;
BA_ "GenSigTimeoutTime_DTCM" SG_ 280 HAS_OpStat_Prim 0;
BA_ "GenSigTimeoutTime_DMSM" SG_ 280 HAS_OpStat_Prim 0;
BA_ "GenSigTimeoutTime_AGSM" SG_ 280 HAS_OpStat_Prim 0;
BA_ "GenSigTimeoutTime_ADCAM" SG_ 280 HAS_OpStat_Prim 0;
BA_ "GenSigTimeoutTime_SGW" SG_ 280 HAS_LAT_CTRL_RequestSts 0;
BA_ "GenSigTimeoutTime_RFHM" SG_ 280 HAS_LAT_CTRL_RequestSts 0;
BA_ "GenSigTimeoutTime_MPAD" SG_ 280 HAS_LAT_CTRL_RequestSts 0;
BA_ "GenSigTimeoutTime_IPC" SG_ 280 HAS_LAT_CTRL_RequestSts 0;
BA_ "GenSigTimeoutTime_GNMM" SG_ 280 HAS_LAT_CTRL_RequestSts 0;
BA_ "GenSigTimeoutTime_EVCU2" SG_ 280 HAS_LAT_CTRL_RequestSts 0;
BA_ "GenSigTimeoutTime_ESL" SG_ 280 HAS_LAT_CTRL_RequestSts 0;
BA_ "GenSigTimeoutTime_ECM" SG_ 280 HAS_LAT_CTRL_RequestSts 0;
BA_ "GenSigTimeoutTime_DTCM" SG_ 280 HAS_LAT_CTRL_RequestSts 0;
BA_ "GenSigTimeoutTime_DMSM" SG_ 280 HAS_LAT_CTRL_RequestSts 0;
BA_ "GenSigTimeoutTime_AGSM" SG_ 280 HAS_LAT_CTRL_RequestSts 0;
BA_ "GenSigTimeoutTime_ADCAM" SG_ 280 HAS_LAT_CTRL_RequestSts 0;
BA_ "GenSigTimeoutTime_SGW" SG_ 280 ESCALATION_TYPE 0;
BA_ "GenSigTimeoutTime_RFHM" SG_ 280 ESCALATION_TYPE 0;
BA_ "GenSigTimeoutTime_MPAD" SG_ 280 ESCALATION_TYPE 0;
BA_ "GenSigTimeoutTime_IPC" SG_ 280 ESCALATION_TYPE 0;
BA_ "GenSigTimeoutTime_GNMM" SG_ 280 ESCALATION_TYPE 0;
BA_ "GenSigTimeoutTime_EVCU2" SG_ 280 ESCALATION_TYPE 0;
BA_ "GenSigTimeoutTime_ESL" SG_ 280 ESCALATION_TYPE 0;
BA_ "GenSigTimeoutTime_ECM" SG_ 280 ESCALATION_TYPE 0;
BA_ "GenSigTimeoutTime_DTCM" SG_ 280 ESCALATION_TYPE 0;
BA_ "GenSigTimeoutTime_DMSM" SG_ 280 ESCALATION_TYPE 0;
BA_ "GenSigTimeoutTime_AGSM" SG_ 280 ESCALATION_TYPE 0;
BA_ "GenSigTimeoutTime_ADCAM" SG_ 280 ESCALATION_TYPE 0;
BA_ "GenSigTimeoutTime_SGW" SG_ 280 DDD_SystemSts 0;
BA_ "GenSigTimeoutTime_RFHM" SG_ 280 DDD_SystemSts 0;
BA_ "GenSigTimeoutTime_MPAD" SG_ 280 DDD_SystemSts 0;
BA_ "GenSigTimeoutTime_IPC" SG_ 280 DDD_SystemSts 0;
BA_ "GenSigTimeoutTime_GNMM" SG_ 280 DDD_SystemSts 0;
BA_ "GenSigTimeoutTime_EVCU2" SG_ 280 DDD_SystemSts 0;
BA_ "GenSigTimeoutTime_ESL" SG_ 280 DDD_SystemSts 0;
BA_ "GenSigTimeoutTime_ECM" SG_ 280 DDD_SystemSts 0;
BA_ "GenSigTimeoutTime_DTCM" SG_ 280 DDD_SystemSts 0;
BA_ "GenSigTimeoutTime_DMSM" SG_ 280 DDD_SystemSts 0;
BA_ "GenSigTimeoutTime_AGSM" SG_ 280 DDD_SystemSts 0;
BA_ "GenSigTimeoutTime_ADCAM" SG_ 280 DDD_SystemSts 0;
BA_ "GenSigTimeoutTime_SGW" SG_ 280 HAS_Status 0;
BA_ "GenSigTimeoutTime_RFHM" SG_ 280 HAS_Status 0;
BA_ "GenSigTimeoutTime_MPAD" SG_ 280 HAS_Status 0;
BA_ "GenSigTimeoutTime_GNMM" SG_ 280 HAS_Status 0;
BA_ "GenSigTimeoutTime_EVCU2" SG_ 280 HAS_Status 0;
BA_ "GenSigTimeoutTime_ESL" SG_ 280 HAS_Status 0;
BA_ "GenSigTimeoutTime_ECM" SG_ 280 HAS_Status 0;
BA_ "GenSigTimeoutTime_DMSM" SG_ 280 HAS_Status 0;
BA_ "GenSigTimeoutTime_AGSM" SG_ 280 HAS_Status 0;
BA_ "GenSigTimeoutTime_ADCAM" SG_ 280 HAS_Status 0;
BA_ "GenSigTimeoutTime_SGW" SG_ 280 DDD_Setting_Avail 0;
BA_ "GenSigTimeoutTime_RFHM" SG_ 280 DDD_Setting_Avail 0;
BA_ "GenSigTimeoutTime_MPAD" SG_ 280 DDD_Setting_Avail 0;
BA_ "GenSigTimeoutTime_GNMM" SG_ 280 DDD_Setting_Avail 0;
BA_ "GenSigTimeoutTime_EVCU2" SG_ 280 DDD_Setting_Avail 0;
BA_ "GenSigTimeoutTime_ESL" SG_ 280 DDD_Setting_Avail 0;
BA_ "GenSigTimeoutTime_ECM" SG_ 280 DDD_Setting_Avail 0;
BA_ "GenSigTimeoutTime_DTCM" SG_ 280 DDD_Setting_Avail 0;
BA_ "GenSigTimeoutTime_DMSM" SG_ 280 DDD_Setting_Avail 0;
BA_ "GenSigTimeoutTime_AGSM" SG_ 280 DDD_Setting_Avail 0;
BA_ "GenSigTimeoutTime_ADCAM" SG_ 280 DDD_Setting_Avail 0;
BA_ "GenSigTimeoutTime_SGW" SG_ 280 CADM_OpStat 0;
BA_ "GenSigTimeoutTime_RFHM" SG_ 280 CADM_OpStat 0;
BA_ "GenSigTimeoutTime_MPAD" SG_ 280 CADM_OpStat 0;
BA_ "GenSigTimeoutTime_IPC" SG_ 280 CADM_OpStat 0;
BA_ "GenSigTimeoutTime_GNMM" SG_ 280 CADM_OpStat 0;
BA_ "GenSigTimeoutTime_EVCU2" SG_ 280 CADM_OpStat 0;
BA_ "GenSigTimeoutTime_ESL" SG_ 280 CADM_OpStat 0;
BA_ "GenSigTimeoutTime_ECM" SG_ 280 CADM_OpStat 0;
BA_ "GenSigTimeoutTime_DTCM" SG_ 280 CADM_OpStat 0;
BA_ "GenSigTimeoutTime_DMSM" SG_ 280 CADM_OpStat 0;
BA_ "GenSigTimeoutTime_AGSM" SG_ 280 CADM_OpStat 0;
BA_ "GenSigTimeoutTime_ADCAM" SG_ 280 CADM_OpStat 0;
BA_ "GenSigTimeoutTime_RFHM" SG_ 280 Intervention 0;
BA_ "GenSigTimeoutTime_MPAD" SG_ 280 Intervention 0;
BA_ "GenSigTimeoutTime_IPC" SG_ 280 Intervention 0;
BA_ "GenSigTimeoutTime_GNMM" SG_ 280 Intervention 0;
BA_ "GenSigTimeoutTime_EVCU2" SG_ 280 Intervention 0;
BA_ "GenSigTimeoutTime_ESL" SG_ 280 Intervention 0;
BA_ "GenSigTimeoutTime_ECM" SG_ 280 Intervention 0;
BA_ "GenSigTimeoutTime_DTCM" SG_ 280 Intervention 0;
BA_ "GenSigTimeoutTime_DMSM" SG_ 280 Intervention 0;
BA_ "GenSigTimeoutTime_AGSM" SG_ 280 Intervention 0;
BA_ "GenSigTimeoutTime_ADCAM" SG_ 280 Intervention 0;
BA_ "GenSigStartValue" SG_ 280 Intervention 4095;
BA_ "GenSigTimeoutTime_SGW" SG_ 280 HIS_Req 0;
BA_ "GenSigTimeoutTime_RFHM" SG_ 280 HIS_Req 0;
BA_ "GenSigTimeoutTime_MPAD" SG_ 280 HIS_Req 0;
BA_ "GenSigTimeoutTime_IPC" SG_ 280 HIS_Req 0;
BA_ "GenSigTimeoutTime_GNMM" SG_ 280 HIS_Req 0;
BA_ "GenSigTimeoutTime_EVCU2" SG_ 280 HIS_Req 0;
BA_ "GenSigTimeoutTime_ESL" SG_ 280 HIS_Req 0;
BA_ "GenSigTimeoutTime_ECM" SG_ 280 HIS_Req 0;
BA_ "GenSigTimeoutTime_DTCM" SG_ 280 HIS_Req 0;
BA_ "GenSigTimeoutTime_DMSM" SG_ 280 HIS_Req 0;
BA_ "GenSigTimeoutTime_AGSM" SG_ 280 HIS_Req 0;
BA_ "GenSigTimeoutTime_ADCAM" SG_ 280 HIS_Req 0;
BA_ "GenSigTimeoutTime_SGW" SG_ 280 GrMax_Rq_ACC 0;
BA_ "GenSigTimeoutTime_RFHM" SG_ 280 GrMax_Rq_ACC 0;
BA_ "GenSigTimeoutTime_MPAD" SG_ 280 GrMax_Rq_ACC 0;
BA_ "GenSigTimeoutTime_IPC" SG_ 280 GrMax_Rq_ACC 0;
BA_ "GenSigTimeoutTime_GNMM" SG_ 280 GrMax_Rq_ACC 0;
BA_ "GenSigTimeoutTime_EVCU2" SG_ 280 GrMax_Rq_ACC 0;
BA_ "GenSigTimeoutTime_ESL" SG_ 280 GrMax_Rq_ACC 0;
BA_ "GenSigTimeoutTime_ECM" SG_ 280 GrMax_Rq_ACC 0;
BA_ "GenSigTimeoutTime_DTCM" SG_ 280 GrMax_Rq_ACC 0;
BA_ "GenSigTimeoutTime_DMSM" SG_ 280 GrMax_Rq_ACC 0;
BA_ "GenSigTimeoutTime_AGSM" SG_ 280 GrMax_Rq_ACC 0;
BA_ "GenSigTimeoutTime_ADCAM" SG_ 280 GrMax_Rq_ACC 0;
BA_ "GenSigTimeoutTime_SGW" SG_ 280 CIPV_Fused 0;
BA_ "GenSigTimeoutTime_RFHM" SG_ 280 CIPV_Fused 0;
BA_ "GenSigTimeoutTime_MPAD" SG_ 280 CIPV_Fused 0;
BA_ "GenSigTimeoutTime_IPC" SG_ 280 CIPV_Fused 0;
BA_ "GenSigTimeoutTime_GNMM" SG_ 280 CIPV_Fused 0;
BA_ "GenSigTimeoutTime_EVCU2" SG_ 280 CIPV_Fused 0;
BA_ "GenSigTimeoutTime_ESL" SG_ 280 CIPV_Fused 0;
BA_ "GenSigTimeoutTime_ECM" SG_ 280 CIPV_Fused 0;
BA_ "GenSigTimeoutTime_DTCM" SG_ 280 CIPV_Fused 0;
BA_ "GenSigTimeoutTime_DMSM" SG_ 280 CIPV_Fused 0;
BA_ "GenSigTimeoutTime_AGSM" SG_ 280 CIPV_Fused 0;
BA_ "GenSigTimeoutTime_ADCAM" SG_ 280 CIPV_Fused 0;
BA_ "GenSigTimeoutTime_SGW" SG_ 280 Brake_Jerk_Req 0;
BA_ "GenSigTimeoutTime_RFHM" SG_ 280 Brake_Jerk_Req 0;
BA_ "GenSigTimeoutTime_MPAD" SG_ 280 Brake_Jerk_Req 0;
BA_ "GenSigTimeoutTime_IPC" SG_ 280 Brake_Jerk_Req 0;
BA_ "GenSigTimeoutTime_GNMM" SG_ 280 Brake_Jerk_Req 0;
BA_ "GenSigTimeoutTime_EVCU2" SG_ 280 Brake_Jerk_Req 0;
BA_ "GenSigTimeoutTime_ESL" SG_ 280 Brake_Jerk_Req 0;
BA_ "GenSigTimeoutTime_ECM" SG_ 280 Brake_Jerk_Req 0;
BA_ "GenSigTimeoutTime_DTCM" SG_ 280 Brake_Jerk_Req 0;
BA_ "GenSigTimeoutTime_DMSM" SG_ 280 Brake_Jerk_Req 0;
BA_ "GenSigTimeoutTime_AGSM" SG_ 280 Brake_Jerk_Req 0;
BA_ "GenSigTimeoutTime_ADCAM" SG_ 280 Brake_Jerk_Req 0;
BA_ "GenSigTimeoutTime_SGW" SG_ 280 MAC_ADAS_FD_INFO 0;
BA_ "GenSigTimeoutTime_RFHM" SG_ 280 MAC_ADAS_FD_INFO 0;
BA_ "GenSigTimeoutTime_MPAD" SG_ 280 MAC_ADAS_FD_INFO 0;
BA_ "GenSigTimeoutTime_IPC" SG_ 280 MAC_ADAS_FD_INFO 0;
BA_ "GenSigTimeoutTime_GNMM" SG_ 280 MAC_ADAS_FD_INFO 0;
BA_ "GenSigTimeoutTime_EVCU2" SG_ 280 MAC_ADAS_FD_INFO 0;
BA_ "GenSigTimeoutTime_ESL" SG_ 280 MAC_ADAS_FD_INFO 0;
BA_ "GenSigTimeoutTime_ECM" SG_ 280 MAC_ADAS_FD_INFO 0;
BA_ "GenSigTimeoutTime_DTCM" SG_ 280 MAC_ADAS_FD_INFO 0;
BA_ "GenSigTimeoutTime_DMSM" SG_ 280 MAC_ADAS_FD_INFO 0;
BA_ "GenSigTimeoutTime_AGSM" SG_ 280 MAC_ADAS_FD_INFO 0;
BA_ "GenSigTimeoutTime_ADCAM" SG_ 280 MAC_ADAS_FD_INFO 0;
BA_ "GenSigTimeoutTime_SGW" SG_ 280 Cntr_ADAS_FD_INFO 0;
BA_ "GenSigTimeoutTime_RFHM" SG_ 280 Cntr_ADAS_FD_INFO 0;
BA_ "GenSigTimeoutTime_MPAD" SG_ 280 Cntr_ADAS_FD_INFO 0;
BA_ "GenSigTimeoutTime_IPC" SG_ 280 Cntr_ADAS_FD_INFO 0;
BA_ "GenSigTimeoutTime_GNMM" SG_ 280 Cntr_ADAS_FD_INFO 0;
BA_ "GenSigTimeoutTime_EVCU2" SG_ 280 Cntr_ADAS_FD_INFO 0;
BA_ "GenSigTimeoutTime_ESL" SG_ 280 Cntr_ADAS_FD_INFO 0;
BA_ "GenSigTimeoutTime_ECM" SG_ 280 Cntr_ADAS_FD_INFO 0;
BA_ "GenSigTimeoutTime_DTCM" SG_ 280 Cntr_ADAS_FD_INFO 0;
BA_ "GenSigTimeoutTime_DMSM" SG_ 280 Cntr_ADAS_FD_INFO 0;
BA_ "GenSigTimeoutTime_AGSM" SG_ 280 Cntr_ADAS_FD_INFO 0;
BA_ "GenSigTimeoutTime_ADCAM" SG_ 280 Cntr_ADAS_FD_INFO 0;
BA_ "GenSigTimeoutTime_SGW" SG_ 1458 SVI_Request_C2_ext 0;
BA_ "GenSigTimeoutTime_RFHM" SG_ 1458 SVI_Request_C2_ext 0;
BA_ "GenSigTimeoutTime_MPAD" SG_ 1458 SVI_Request_C2_ext 0;
BA_ "GenSigTimeoutTime_GNMM" SG_ 1458 SVI_Request_C2_ext 0;
BA_ "GenSigTimeoutTime_EVCU2" SG_ 1458 SVI_Request_C2_ext 0;
BA_ "GenSigTimeoutTime_ESL" SG_ 1458 SVI_Request_C2_ext 0;
BA_ "GenSigTimeoutTime_ECM" SG_ 1458 SVI_Request_C2_ext 0;
BA_ "GenSigTimeoutTime_DTCM" SG_ 1458 SVI_Request_C2_ext 0;
BA_ "GenSigTimeoutTime_DMSM" SG_ 1458 SVI_Request_C2_ext 0;
BA_ "GenSigTimeoutTime_BSM" SG_ 1458 SVI_Request_C2_ext 0;
BA_ "GenSigTimeoutTime_BCM" SG_ 1458 SVI_Request_C2_ext 0;
BA_ "GenSigTimeoutTime_AGSM" SG_ 1458 SVI_Request_C2_ext 0;
BA_ "GenSigTimeoutTime_ADCAM" SG_ 1458 SVI_Request_C2_ext 0;
BA_ "GenSigSendType" SG_ 1458 SVI_Request_C2_ext 3;
BA_ "GenSigTimeoutTime_SGW" SG_ 280 ACC_Engine_Torque_Enabled 0;
BA_ "GenSigTimeoutTime_RFHM" SG_ 280 ACC_Engine_Torque_Enabled 0;
BA_ "GenSigTimeoutTime_MPAD" SG_ 280 ACC_Engine_Torque_Enabled 0;
BA_ "GenSigTimeoutTime_IPC" SG_ 280 ACC_Engine_Torque_Enabled 0;
BA_ "GenSigTimeoutTime_GNMM" SG_ 280 ACC_Engine_Torque_Enabled 0;
BA_ "GenSigTimeoutTime_EVCU2" SG_ 280 ACC_Engine_Torque_Enabled 0;
BA_ "GenSigTimeoutTime_ESL" SG_ 280 ACC_Engine_Torque_Enabled 0;
BA_ "GenSigTimeoutTime_ECM" SG_ 280 ACC_Engine_Torque_Enabled 0;
BA_ "GenSigTimeoutTime_DTCM" SG_ 280 ACC_Engine_Torque_Enabled 0;
BA_ "GenSigTimeoutTime_DMSM" SG_ 280 ACC_Engine_Torque_Enabled 0;
BA_ "GenSigTimeoutTime_AGSM" SG_ 280 ACC_Engine_Torque_Enabled 0;
BA_ "GenSigTimeoutTime_ADCAM" SG_ 280 ACC_Engine_Torque_Enabled 0;
BA_ "GenSigTimeoutTime_SGW" SG_ 280 ACC_Drive_Cmd 0;
BA_ "GenSigTimeoutTime_RFHM" SG_ 280 ACC_Drive_Cmd 0;
BA_ "GenSigTimeoutTime_MPAD" SG_ 280 ACC_Drive_Cmd 0;
BA_ "GenSigTimeoutTime_IPC" SG_ 280 ACC_Drive_Cmd 0;
BA_ "GenSigTimeoutTime_GNMM" SG_ 280 ACC_Drive_Cmd 0;
BA_ "GenSigTimeoutTime_EVCU2" SG_ 280 ACC_Drive_Cmd 0;
BA_ "GenSigTimeoutTime_ESL" SG_ 280 ACC_Drive_Cmd 0;
BA_ "GenSigTimeoutTime_ECM" SG_ 280 ACC_Drive_Cmd 0;
BA_ "GenSigTimeoutTime_DTCM" SG_ 280 ACC_Drive_Cmd 0;
BA_ "GenSigTimeoutTime_DMSM" SG_ 280 ACC_Drive_Cmd 0;
BA_ "GenSigTimeoutTime_AGSM" SG_ 280 ACC_Drive_Cmd 0;
BA_ "GenSigTimeoutTime_ADCAM" SG_ 280 ACC_Drive_Cmd 0;
BA_ "GenSigTimeoutTime_SGW" SG_ 280 AEB_Type 0;
BA_ "GenSigTimeoutTime_RFHM" SG_ 280 AEB_Type 0;
BA_ "GenSigTimeoutTime_MPAD" SG_ 280 AEB_Type 0;
BA_ "GenSigTimeoutTime_IPC" SG_ 280 AEB_Type 0;
BA_ "GenSigTimeoutTime_GNMM" SG_ 280 AEB_Type 0;
BA_ "GenSigTimeoutTime_EVCU2" SG_ 280 AEB_Type 0;
BA_ "GenSigTimeoutTime_ESL" SG_ 280 AEB_Type 0;
BA_ "GenSigTimeoutTime_ECM" SG_ 280 AEB_Type 0;
BA_ "GenSigTimeoutTime_DTCM" SG_ 280 AEB_Type 0;
BA_ "GenSigTimeoutTime_DMSM" SG_ 280 AEB_Type 0;
BA_ "GenSigTimeoutTime_AGSM" SG_ 280 AEB_Type 0;
BA_ "GenSigTimeoutTime_ADCAM" SG_ 280 AEB_Type 0;
BA_ "GenSigTimeoutTime_SGW" SG_ 280 AEB_Systemsts 0;
BA_ "GenSigTimeoutTime_RFHM" SG_ 280 AEB_Systemsts 0;
BA_ "GenSigTimeoutTime_MPAD" SG_ 280 AEB_Systemsts 0;
BA_ "GenSigTimeoutTime_GNMM" SG_ 280 AEB_Systemsts 0;
BA_ "GenSigTimeoutTime_EVCU2" SG_ 280 AEB_Systemsts 0;
BA_ "GenSigTimeoutTime_ESL" SG_ 280 AEB_Systemsts 0;
BA_ "GenSigTimeoutTime_ECM" SG_ 280 AEB_Systemsts 0;
BA_ "GenSigTimeoutTime_DTCM" SG_ 280 AEB_Systemsts 0;
BA_ "GenSigTimeoutTime_DMSM" SG_ 280 AEB_Systemsts 0;
BA_ "GenSigTimeoutTime_AGSM" SG_ 280 AEB_Systemsts 0;
BA_ "GenSigTimeoutTime_ADCAM" SG_ 280 AEB_Systemsts 0;
BA_ "GenSigTimeoutTime_SGW" SG_ 280 AEB_Sensitivity_Setting 0;
BA_ "GenSigTimeoutTime_RFHM" SG_ 280 AEB_Sensitivity_Setting 0;
BA_ "GenSigTimeoutTime_MPAD" SG_ 280 AEB_Sensitivity_Setting 0;
BA_ "GenSigTimeoutTime_GNMM" SG_ 280 AEB_Sensitivity_Setting 0;
BA_ "GenSigTimeoutTime_EVCU2" SG_ 280 AEB_Sensitivity_Setting 0;
BA_ "GenSigTimeoutTime_ESL" SG_ 280 AEB_Sensitivity_Setting 0;
BA_ "GenSigTimeoutTime_ECM" SG_ 280 AEB_Sensitivity_Setting 0;
BA_ "GenSigTimeoutTime_DTCM" SG_ 280 AEB_Sensitivity_Setting 0;
BA_ "GenSigTimeoutTime_DMSM" SG_ 280 AEB_Sensitivity_Setting 0;
BA_ "GenSigTimeoutTime_AGSM" SG_ 280 AEB_Sensitivity_Setting 0;
BA_ "GenSigTimeoutTime_ADCAM" SG_ 280 AEB_Sensitivity_Setting 0;
BA_ "GenSigTimeoutTime_SGW" SG_ 280 ACC_StopStart 0;
BA_ "GenSigTimeoutTime_RFHM" SG_ 280 ACC_StopStart 0;
BA_ "GenSigTimeoutTime_MPAD" SG_ 280 ACC_StopStart 0;
BA_ "GenSigTimeoutTime_IPC" SG_ 280 ACC_StopStart 0;
BA_ "GenSigTimeoutTime_GNMM" SG_ 280 ACC_StopStart 0;
BA_ "GenSigTimeoutTime_EVCU2" SG_ 280 ACC_StopStart 0;
BA_ "GenSigTimeoutTime_ESL" SG_ 280 ACC_StopStart 0;
BA_ "GenSigTimeoutTime_ECM" SG_ 280 ACC_StopStart 0;
BA_ "GenSigTimeoutTime_DTCM" SG_ 280 ACC_StopStart 0;
BA_ "GenSigTimeoutTime_DMSM" SG_ 280 ACC_StopStart 0;
BA_ "GenSigTimeoutTime_AGSM" SG_ 280 ACC_StopStart 0;
BA_ "GenSigTimeoutTime_ADCAM" SG_ 280 ACC_StopStart 0;
BA_ "GenSigTimeoutTime_SGW" SG_ 1458 MessageCounter_ADAS_HMI_C2 0;
BA_ "GenSigTimeoutTime_RFHM" SG_ 1458 MessageCounter_ADAS_HMI_C2 0;
BA_ "GenSigTimeoutTime_MPAD" SG_ 1458 MessageCounter_ADAS_HMI_C2 0;
BA_ "GenSigTimeoutTime_GNMM" SG_ 1458 MessageCounter_ADAS_HMI_C2 0;
BA_ "GenSigTimeoutTime_EVCU2" SG_ 1458 MessageCounter_ADAS_HMI_C2 0;
BA_ "GenSigTimeoutTime_ESL" SG_ 1458 MessageCounter_ADAS_HMI_C2 0;
BA_ "GenSigTimeoutTime_ECM" SG_ 1458 MessageCounter_ADAS_HMI_C2 0;
BA_ "GenSigTimeoutTime_DTCM" SG_ 1458 MessageCounter_ADAS_HMI_C2 0;
BA_ "GenSigTimeoutTime_DMSM" SG_ 1458 MessageCounter_ADAS_HMI_C2 0;
BA_ "GenSigTimeoutTime_BCM" SG_ 1458 MessageCounter_ADAS_HMI_C2 0;
BA_ "GenSigTimeoutTime_AGSM" SG_ 1458 MessageCounter_ADAS_HMI_C2 0;
BA_ "GenSigTimeoutTime_ADCAM" SG_ 1458 MessageCounter_ADAS_HMI_C2 0;
BA_ "GenSigTimeoutTime_SGW" SG_ 1458 CRC_ADAS_HMI_C2 0;
BA_ "GenSigTimeoutTime_RFHM" SG_ 1458 CRC_ADAS_HMI_C2 0;
BA_ "GenSigTimeoutTime_MPAD" SG_ 1458 CRC_ADAS_HMI_C2 0;
BA_ "GenSigTimeoutTime_GNMM" SG_ 1458 CRC_ADAS_HMI_C2 0;
BA_ "GenSigTimeoutTime_EVCU2" SG_ 1458 CRC_ADAS_HMI_C2 0;
BA_ "GenSigTimeoutTime_ESL" SG_ 1458 CRC_ADAS_HMI_C2 0;
BA_ "GenSigTimeoutTime_ECM" SG_ 1458 CRC_ADAS_HMI_C2 0;
BA_ "GenSigTimeoutTime_DTCM" SG_ 1458 CRC_ADAS_HMI_C2 0;
BA_ "GenSigTimeoutTime_DMSM" SG_ 1458 CRC_ADAS_HMI_C2 0;
BA_ "GenSigTimeoutTime_BCM" SG_ 1458 CRC_ADAS_HMI_C2 0;
BA_ "GenSigTimeoutTime_AGSM" SG_ 1458 CRC_ADAS_HMI_C2 0;
BA_ "GenSigTimeoutTime_ADCAM" SG_ 1458 CRC_ADAS_HMI_C2 0;
BA_ "GenSigTimeoutTime_SGW" SG_ 280 ACC_Systemsts 0;
BA_ "GenSigTimeoutTime_RFHM" SG_ 280 ACC_Systemsts 0;
BA_ "GenSigTimeoutTime_MPAD" SG_ 280 ACC_Systemsts 0;
BA_ "GenSigTimeoutTime_GNMM" SG_ 280 ACC_Systemsts 0;
BA_ "GenSigTimeoutTime_EVCU2" SG_ 280 ACC_Systemsts 0;
BA_ "GenSigTimeoutTime_ESL" SG_ 280 ACC_Systemsts 0;
BA_ "GenSigTimeoutTime_ECM" SG_ 280 ACC_Systemsts 0;
BA_ "GenSigTimeoutTime_DTCM" SG_ 280 ACC_Systemsts 0;
BA_ "GenSigTimeoutTime_DMSM" SG_ 280 ACC_Systemsts 0;
BA_ "GenSigTimeoutTime_AGSM" SG_ 280 ACC_Systemsts 0;
BA_ "GenSigTimeoutTime_ADCAM" SG_ 280 ACC_Systemsts 0;
BA_ "GenSigTimeoutTime_BCM" SG_ 1458 ACC_FailSts_C2 0;
BA_ "GenSigTimeoutTime_AGSM" SG_ 1458 ACC_FailSts_C2 0;
BA_ "GenSigTimeoutTime_ADCAM" SG_ 1458 ACC_FailSts_C2 0;
BA_ "GenSigSendType" SG_ 1458 ACC_FailSts_C2 3;
BA_ "GenSigTimeoutTime_SGW" SG_ 1458 ACC_FailSts_C2 0;
BA_ "GenSigTimeoutTime_RFHM" SG_ 1458 ACC_FailSts_C2 0;
BA_ "GenSigTimeoutTime_MPAD" SG_ 1458 ACC_FailSts_C2 0;
BA_ "GenSigTimeoutTime_IPC" SG_ 1458 ACC_FailSts_C2 0;
BA_ "GenSigTimeoutTime_GNMM" SG_ 1458 ACC_FailSts_C2 0;
BA_ "GenSigTimeoutTime_EVCU2" SG_ 1458 ACC_FailSts_C2 0;
BA_ "GenSigTimeoutTime_ESL" SG_ 1458 ACC_FailSts_C2 0;
BA_ "GenSigTimeoutTime_ECM" SG_ 1458 ACC_FailSts_C2 0;
BA_ "GenSigTimeoutTime_DTCM" SG_ 1458 ACC_FailSts_C2 0;
BA_ "GenSigTimeoutTime_DMSM" SG_ 1458 ACC_FailSts_C2 0;
BA_ "GenSigTimeoutTime_SGW" SG_ 280 BlindSpot_TrailerSts 0;
BA_ "GenSigTimeoutTime_RFHM" SG_ 280 BlindSpot_TrailerSts 0;
BA_ "GenSigTimeoutTime_MPAD" SG_ 280 BlindSpot_TrailerSts 0;
BA_ "GenSigTimeoutTime_GNMM" SG_ 280 BlindSpot_TrailerSts 0;
BA_ "GenSigTimeoutTime_EVCU2" SG_ 280 BlindSpot_TrailerSts 0;
BA_ "GenSigTimeoutTime_ESL" SG_ 280 BlindSpot_TrailerSts 0;
BA_ "GenSigTimeoutTime_ECM" SG_ 280 BlindSpot_TrailerSts 0;
BA_ "GenSigTimeoutTime_DTCM" SG_ 280 BlindSpot_TrailerSts 0;
BA_ "GenSigTimeoutTime_DMSM" SG_ 280 BlindSpot_TrailerSts 0;
BA_ "GenSigTimeoutTime_AGSM" SG_ 280 BlindSpot_TrailerSts 0;
BA_ "GenSigTimeoutTime_ADCAM" SG_ 280 BlindSpot_TrailerSts 0;
BA_ "GenSigSendType" SG_ 280 BlindSpot_TrailerSts 3;
BA_ "GenSigTimeoutTime_BSM" SG_ 728 Obj01_ID 0;
BA_ "GenSigTimeoutTime_SGW" SG_ 728 Obj01_HorDist 0;
BA_ "GenSigTimeoutTime_RFHM" SG_ 728 Obj01_HorDist 0;
BA_ "GenSigTimeoutTime_MPAD" SG_ 728 Obj01_HorDist 0;
BA_ "GenSigTimeoutTime_IPC" SG_ 728 Obj01_HorDist 0;
BA_ "GenSigTimeoutTime_GNMM" SG_ 728 Obj01_HorDist 0;
BA_ "GenSigTimeoutTime_EVCU2" SG_ 728 Obj01_HorDist 0;
BA_ "GenSigTimeoutTime_ESL" SG_ 728 Obj01_HorDist 0;
BA_ "GenSigTimeoutTime_ECM" SG_ 728 Obj01_HorDist 0;
BA_ "GenSigTimeoutTime_DTCM" SG_ 728 Obj01_HorDist 0;
BA_ "GenSigTimeoutTime_DMSM" SG_ 728 Obj01_HorDist 0;
BA_ "GenSigTimeoutTime_BSM" SG_ 728 Obj01_HorDist 0;
BA_ "GenSigTimeoutTime_AGSM" SG_ 728 Obj01_HorDist 0;
BA_ "GenSigTimeoutTime_ADCAM" SG_ 728 Obj01_HorDist 0;
BA_ "GenSigStartValue" SG_ 728 Obj01_HorDist 254;
BA_ "GenSigTimeoutTime_SGW" SG_ 728 Cam_TrafficStyle 0;
BA_ "GenSigTimeoutTime_RFHM" SG_ 728 Cam_TrafficStyle 0;
BA_ "GenSigTimeoutTime_MPAD" SG_ 728 Cam_TrafficStyle 0;
BA_ "GenSigTimeoutTime_IPC" SG_ 728 Cam_TrafficStyle 0;
BA_ "GenSigTimeoutTime_GNMM" SG_ 728 Cam_TrafficStyle 0;
BA_ "GenSigTimeoutTime_EVCU2" SG_ 728 Cam_TrafficStyle 0;
BA_ "GenSigTimeoutTime_ESL" SG_ 728 Cam_TrafficStyle 0;
BA_ "GenSigTimeoutTime_ECM" SG_ 728 Cam_TrafficStyle 0;
BA_ "GenSigTimeoutTime_DTCM" SG_ 728 Cam_TrafficStyle 0;
BA_ "GenSigTimeoutTime_DMSM" SG_ 728 Cam_TrafficStyle 0;
BA_ "GenSigTimeoutTime_BSM" SG_ 728 Cam_TrafficStyle 0;
BA_ "GenSigTimeoutTime_AGSM" SG_ 728 Cam_TrafficStyle 0;
BA_ "GenSigTimeoutTime_ADCAM" SG_ 728 Cam_TrafficStyle 0;
BA_ "GenSigStartValue" SG_ 728 Cam_TrafficStyle 14;
BA_ "GenSigTimeoutTime_SGW" SG_ 728 Cam_Status 0;
BA_ "GenSigTimeoutTime_RFHM" SG_ 728 Cam_Status 0;
BA_ "GenSigTimeoutTime_MPAD" SG_ 728 Cam_Status 0;
BA_ "GenSigTimeoutTime_IPC" SG_ 728 Cam_Status 0;
BA_ "GenSigTimeoutTime_GNMM" SG_ 728 Cam_Status 0;
BA_ "GenSigTimeoutTime_EVCU2" SG_ 728 Cam_Status 0;
BA_ "GenSigTimeoutTime_ESL" SG_ 728 Cam_Status 0;
BA_ "GenSigTimeoutTime_ECM" SG_ 728 Cam_Status 0;
BA_ "GenSigTimeoutTime_DTCM" SG_ 728 Cam_Status 0;
BA_ "GenSigTimeoutTime_DMSM" SG_ 728 Cam_Status 0;
BA_ "GenSigTimeoutTime_BSM" SG_ 728 Cam_Status 0;
BA_ "GenSigTimeoutTime_AGSM" SG_ 728 Cam_Status 0;
BA_ "GenSigTimeoutTime_ADCAM" SG_ 728 Cam_Status 0;
BA_ "GenSigStartValue" SG_ 728 Cam_Status 14;
BA_ "GenSigTimeoutTime_SGW" SG_ 728 Cam_SelfGlaring 0;
BA_ "GenSigTimeoutTime_RFHM" SG_ 728 Cam_SelfGlaring 0;
BA_ "GenSigTimeoutTime_MPAD" SG_ 728 Cam_SelfGlaring 0;
BA_ "GenSigTimeoutTime_IPC" SG_ 728 Cam_SelfGlaring 0;
BA_ "GenSigTimeoutTime_GNMM" SG_ 728 Cam_SelfGlaring 0;
BA_ "GenSigTimeoutTime_EVCU2" SG_ 728 Cam_SelfGlaring 0;
BA_ "GenSigTimeoutTime_ESL" SG_ 728 Cam_SelfGlaring 0;
BA_ "GenSigTimeoutTime_ECM" SG_ 728 Cam_SelfGlaring 0;
BA_ "GenSigTimeoutTime_DTCM" SG_ 728 Cam_SelfGlaring 0;
BA_ "GenSigTimeoutTime_DMSM" SG_ 728 Cam_SelfGlaring 0;
BA_ "GenSigTimeoutTime_BSM" SG_ 728 Cam_SelfGlaring 0;
BA_ "GenSigTimeoutTime_AGSM" SG_ 728 Cam_SelfGlaring 0;
BA_ "GenSigTimeoutTime_ADCAM" SG_ 728 Cam_SelfGlaring 0;
BA_ "GenSigStartValue" SG_ 728 Cam_SelfGlaring 14;
BA_ "GenSigTimeoutTime_SGW" SG_ 728 Cam_ObjNum 0;
BA_ "GenSigTimeoutTime_RFHM" SG_ 728 Cam_ObjNum 0;
BA_ "GenSigTimeoutTime_MPAD" SG_ 728 Cam_ObjNum 0;
BA_ "GenSigTimeoutTime_IPC" SG_ 728 Cam_ObjNum 0;
BA_ "GenSigTimeoutTime_GNMM" SG_ 728 Cam_ObjNum 0;
BA_ "GenSigTimeoutTime_EVCU2" SG_ 728 Cam_ObjNum 0;
BA_ "GenSigTimeoutTime_ESL" SG_ 728 Cam_ObjNum 0;
BA_ "GenSigTimeoutTime_ECM" SG_ 728 Cam_ObjNum 0;
BA_ "GenSigTimeoutTime_DTCM" SG_ 728 Cam_ObjNum 0;
BA_ "GenSigTimeoutTime_DMSM" SG_ 728 Cam_ObjNum 0;
BA_ "GenSigTimeoutTime_BSM" SG_ 728 Cam_ObjNum 0;
BA_ "GenSigTimeoutTime_AGSM" SG_ 728 Cam_ObjNum 0;
BA_ "GenSigTimeoutTime_ADCAM" SG_ 728 Cam_ObjNum 0;
BA_ "GenSigStartValue" SG_ 728 Cam_ObjNum 14;
BA_ "GenSigTimeoutTime_SGW" SG_ 728 Cam_Env 0;
BA_ "GenSigTimeoutTime_RFHM" SG_ 728 Cam_Env 0;
BA_ "GenSigTimeoutTime_MPAD" SG_ 728 Cam_Env 0;
BA_ "GenSigTimeoutTime_IPC" SG_ 728 Cam_Env 0;
BA_ "GenSigTimeoutTime_GNMM" SG_ 728 Cam_Env 0;
BA_ "GenSigTimeoutTime_EVCU2" SG_ 728 Cam_Env 0;
BA_ "GenSigTimeoutTime_ESL" SG_ 728 Cam_Env 0;
BA_ "GenSigTimeoutTime_ECM" SG_ 728 Cam_Env 0;
BA_ "GenSigTimeoutTime_DTCM" SG_ 728 Cam_Env 0;
BA_ "GenSigTimeoutTime_DMSM" SG_ 728 Cam_Env 0;
BA_ "GenSigTimeoutTime_BSM" SG_ 728 Cam_Env 0;
BA_ "GenSigTimeoutTime_AGSM" SG_ 728 Cam_Env 0;
BA_ "GenSigTimeoutTime_ADCAM" SG_ 728 Cam_Env 0;
BA_ "GenSigTimeoutTime_SGW" SG_ 728 Cam_AmbientLight 0;
BA_ "GenSigTimeoutTime_RFHM" SG_ 728 Cam_AmbientLight 0;
BA_ "GenSigTimeoutTime_MPAD" SG_ 728 Cam_AmbientLight 0;
BA_ "GenSigTimeoutTime_IPC" SG_ 728 Cam_AmbientLight 0;
BA_ "GenSigTimeoutTime_GNMM" SG_ 728 Cam_AmbientLight 0;
BA_ "GenSigTimeoutTime_EVCU2" SG_ 728 Cam_AmbientLight 0;
BA_ "GenSigTimeoutTime_ESL" SG_ 728 Cam_AmbientLight 0;
BA_ "GenSigTimeoutTime_ECM" SG_ 728 Cam_AmbientLight 0;
BA_ "GenSigTimeoutTime_DTCM" SG_ 728 Cam_AmbientLight 0;
BA_ "GenSigTimeoutTime_DMSM" SG_ 728 Cam_AmbientLight 0;
BA_ "GenSigTimeoutTime_BSM" SG_ 728 Cam_AmbientLight 0;
BA_ "GenSigTimeoutTime_AGSM" SG_ 728 Cam_AmbientLight 0;
BA_ "GenSigTimeoutTime_ADCAM" SG_ 728 Cam_AmbientLight 0;
BA_ "GenSigStartValue" SG_ 728 Cam_AmbientLight 14;
BA_ "GenSigTimeoutTime_AGSM" SG_ 728 Obj01_ID 0;
BA_ "GenSigTimeoutTime_ADCAM" SG_ 728 Obj01_ID 0;
BA_ "GenSigTimeoutTime_SGW" SG_ 2564485652 N_PDU 0;
BA_ "GenSigTimeoutTime_RFHM" SG_ 2564485652 N_PDU 0;
BA_ "GenSigTimeoutTime_MPAD" SG_ 2564485652 N_PDU 0;
BA_ "GenSigTimeoutTime_IPC" SG_ 2564485652 N_PDU 0;
BA_ "GenSigTimeoutTime_GNMM" SG_ 2564485652 N_PDU 0;
BA_ "GenSigTimeoutTime_EVCU2" SG_ 2564485652 N_PDU 0;
BA_ "GenSigTimeoutTime_ESL" SG_ 2564485652 N_PDU 0;
BA_ "GenSigTimeoutTime_ECM" SG_ 2564485652 N_PDU 0;
BA_ "GenSigTimeoutTime_DTCM" SG_ 2564485652 N_PDU 0;
BA_ "GenSigTimeoutTime_DMSM" SG_ 2564485652 N_PDU 0;
BA_ "GenSigTimeoutTime_BSM" SG_ 2564485652 N_PDU 0;
BA_ "GenSigTimeoutTime_BCM" SG_ 2564485652 N_PDU 0;
BA_ "GenSigTimeoutTime_AGSM" SG_ 2564485652 N_PDU 0;
BA_ "GenSigTimeoutTime_ADCAM" SG_ 2564485652 N_PDU 0;
BA_ "GenSigTimeoutTime_SGW" SG_ 2564485653 N_PDU 0;
BA_ "GenSigTimeoutTime_RFHM" SG_ 2564485653 N_PDU 0;
BA_ "GenSigTimeoutTime_MPAD" SG_ 2564485653 N_PDU 0;
BA_ "GenSigTimeoutTime_IPC" SG_ 2564485653 N_PDU 0;
BA_ "GenSigTimeoutTime_GNMM" SG_ 2564485653 N_PDU 0;
BA_ "GenSigTimeoutTime_EVCU2" SG_ 2564485653 N_PDU 0;
BA_ "GenSigTimeoutTime_ESL" SG_ 2564485653 N_PDU 0;
BA_ "GenSigTimeoutTime_ECM" SG_ 2564485653 N_PDU 0;
BA_ "GenSigTimeoutTime_DTCM" SG_ 2564485653 N_PDU 0;
BA_ "GenSigTimeoutTime_DMSM" SG_ 2564485653 N_PDU 0;
BA_ "GenSigTimeoutTime_BSM" SG_ 2564485653 N_PDU 0;
BA_ "GenSigTimeoutTime_BCM" SG_ 2564485653 N_PDU 0;
BA_ "GenSigTimeoutTime_AGSM" SG_ 2564485653 N_PDU 0;
BA_ "GenSigTimeoutTime_ADCAM" SG_ 2564485653 N_PDU 0;
BA_ "GenSigTimeoutTime_BSM" SG_ 161 undervoltage_detected 0;
BA_ "GenSigTimeoutTime_BCM" SG_ 161 undervoltage_detected 0;
BA_ "GenSigTimeoutTime_AGSM" SG_ 161 undervoltage_detected 0;
BA_ "GenSigTimeoutTime_ADCAM" SG_ 161 undervoltage_detected 0;
BA_ "GenSigTimeoutTime_SGW" SG_ 161 undervoltage_detected 0;
BA_ "GenSigTimeoutTime_RFHM" SG_ 161 undervoltage_detected 0;
BA_ "GenSigTimeoutTime_IPC" SG_ 161 undervoltage_detected 0;
BA_ "GenSigTimeoutTime_GNMM" SG_ 161 undervoltage_detected 0;
BA_ "GenSigTimeoutTime_EVCU2" SG_ 161 undervoltage_detected 0;
BA_ "GenSigTimeoutTime_ESL" SG_ 161 undervoltage_detected 0;
BA_ "GenSigTimeoutTime_ECM" SG_ 161 undervoltage_detected 0;
BA_ "GenSigTimeoutTime_DTCM" SG_ 161 undervoltage_detected 0;
BA_ "GenSigTimeoutTime_DMSM" SG_ 161 undervoltage_detected 0;
BA_ "GenSigTimeoutTime_SGW" SG_ 161 switch_status_OpenClose 0;
BA_ "GenSigTimeoutTime_RFHM" SG_ 161 switch_status_OpenClose 0;
BA_ "GenSigTimeoutTime_IPC" SG_ 161 switch_status_OpenClose 0;
BA_ "GenSigTimeoutTime_GNMM" SG_ 161 switch_status_OpenClose 0;
BA_ "GenSigTimeoutTime_EVCU2" SG_ 161 switch_status_OpenClose 0;
BA_ "GenSigTimeoutTime_ESL" SG_ 161 switch_status_OpenClose 0;
BA_ "GenSigTimeoutTime_ECM" SG_ 161 switch_status_OpenClose 0;
BA_ "GenSigTimeoutTime_DTCM" SG_ 161 switch_status_OpenClose 0;
BA_ "GenSigTimeoutTime_DMSM" SG_ 161 switch_status_OpenClose 0;
BA_ "GenSigTimeoutTime_BSM" SG_ 161 switch_status_OpenClose 0;
BA_ "GenSigTimeoutTime_BCM" SG_ 161 switch_status_OpenClose 0;
BA_ "GenSigTimeoutTime_AGSM" SG_ 161 switch_status_OpenClose 0;
BA_ "GenSigTimeoutTime_ADCAM" SG_ 161 switch_status_OpenClose 0;
BA_ "GenSigTimeoutTime_SGW" SG_ 161 RsErr_DBSM2 0;
BA_ "GenSigTimeoutTime_RFHM" SG_ 161 RsErr_DBSM2 0;
BA_ "GenSigTimeoutTime_IPC" SG_ 161 RsErr_DBSM2 0;
BA_ "GenSigTimeoutTime_GNMM" SG_ 161 RsErr_DBSM2 0;
BA_ "GenSigTimeoutTime_EVCU2" SG_ 161 RsErr_DBSM2 0;
BA_ "GenSigTimeoutTime_ESL" SG_ 161 RsErr_DBSM2 0;
BA_ "GenSigTimeoutTime_ECM" SG_ 161 RsErr_DBSM2 0;
BA_ "GenSigTimeoutTime_DTCM" SG_ 161 RsErr_DBSM2 0;
BA_ "GenSigTimeoutTime_DMSM" SG_ 161 RsErr_DBSM2 0;
BA_ "GenSigTimeoutTime_BSM" SG_ 161 RsErr_DBSM2 0;
BA_ "GenSigTimeoutTime_BCM" SG_ 161 RsErr_DBSM2 0;
BA_ "GenSigTimeoutTime_AGSM" SG_ 161 RsErr_DBSM2 0;
BA_ "GenSigTimeoutTime_ADCAM" SG_ 161 RsErr_DBSM2 0;
BA_ "GenSigTimeoutTime_SGW" SG_ 161 overtemp_detected 0;
BA_ "GenSigTimeoutTime_RFHM" SG_ 161 overtemp_detected 0;
BA_ "GenSigTimeoutTime_IPC" SG_ 161 overtemp_detected 0;
BA_ "GenSigTimeoutTime_GNMM" SG_ 161 overtemp_detected 0;
BA_ "GenSigTimeoutTime_EVCU2" SG_ 161 overtemp_detected 0;
BA_ "GenSigTimeoutTime_ESL" SG_ 161 overtemp_detected 0;
BA_ "GenSigTimeoutTime_ECM" SG_ 161 overtemp_detected 0;
BA_ "GenSigTimeoutTime_DTCM" SG_ 161 overtemp_detected 0;
BA_ "GenSigTimeoutTime_DMSM" SG_ 161 overtemp_detected 0;
BA_ "GenSigTimeoutTime_BSM" SG_ 161 overtemp_detected 0;
BA_ "GenSigTimeoutTime_BCM" SG_ 161 overtemp_detected 0;
BA_ "GenSigTimeoutTime_AGSM" SG_ 161 overtemp_detected 0;
BA_ "GenSigTimeoutTime_ADCAM" SG_ 161 overtemp_detected 0;
BA_ "GenSigTimeoutTime_SGW" SG_ 161 overcurrent_detected 0;
BA_ "GenSigTimeoutTime_RFHM" SG_ 161 overcurrent_detected 0;
BA_ "GenSigTimeoutTime_IPC" SG_ 161 overcurrent_detected 0;
BA_ "GenSigTimeoutTime_GNMM" SG_ 161 overcurrent_detected 0;
BA_ "GenSigTimeoutTime_EVCU2" SG_ 161 overcurrent_detected 0;
BA_ "GenSigTimeoutTime_ESL" SG_ 161 overcurrent_detected 0;
BA_ "GenSigTimeoutTime_ECM" SG_ 161 overcurrent_detected 0;
BA_ "GenSigTimeoutTime_DTCM" SG_ 161 overcurrent_detected 0;
BA_ "GenSigTimeoutTime_DMSM" SG_ 161 overcurrent_detected 0;
BA_ "GenSigTimeoutTime_BSM" SG_ 161 overcurrent_detected 0;
BA_ "GenSigTimeoutTime_BCM" SG_ 161 overcurrent_detected 0;
BA_ "GenSigTimeoutTime_AGSM" SG_ 161 overcurrent_detected 0;
BA_ "GenSigTimeoutTime_ADCAM" SG_ 161 overcurrent_detected 0;
BA_ "GenSigTimeoutTime_SGW" SG_ 161 L2plus_ack 0;
BA_ "GenSigTimeoutTime_RFHM" SG_ 161 L2plus_ack 0;
BA_ "GenSigTimeoutTime_IPC" SG_ 161 L2plus_ack 0;
BA_ "GenSigTimeoutTime_GNMM" SG_ 161 L2plus_ack 0;
BA_ "GenSigTimeoutTime_EVCU2" SG_ 161 L2plus_ack 0;
BA_ "GenSigTimeoutTime_ESL" SG_ 161 L2plus_ack 0;
BA_ "GenSigTimeoutTime_ECM" SG_ 161 L2plus_ack 0;
BA_ "GenSigTimeoutTime_DTCM" SG_ 161 L2plus_ack 0;
BA_ "GenSigTimeoutTime_DMSM" SG_ 161 L2plus_ack 0;
BA_ "GenSigTimeoutTime_BSM" SG_ 161 L2plus_ack 0;
BA_ "GenSigTimeoutTime_BCM" SG_ 161 L2plus_ack 0;
BA_ "GenSigTimeoutTime_AGSM" SG_ 161 L2plus_ack 0;
BA_ "GenSigTimeoutTime_ADCAM" SG_ 161 L2plus_ack 0;
BA_ "GenSigTimeoutTime_SGW" SG_ 161 ESS_input_active 0;
BA_ "GenSigTimeoutTime_RFHM" SG_ 161 ESS_input_active 0;
BA_ "GenSigTimeoutTime_MPAD" SG_ 161 ESS_input_active 0;
BA_ "GenSigTimeoutTime_IPC" SG_ 161 ESS_input_active 0;
BA_ "GenSigTimeoutTime_GNMM" SG_ 161 ESS_input_active 0;
BA_ "GenSigTimeoutTime_EVCU2" SG_ 161 ESS_input_active 0;
BA_ "GenSigTimeoutTime_ESL" SG_ 161 ESS_input_active 0;
BA_ "GenSigTimeoutTime_ECM" SG_ 161 ESS_input_active 0;
BA_ "GenSigTimeoutTime_DTCM" SG_ 161 ESS_input_active 0;
BA_ "GenSigTimeoutTime_DMSM" SG_ 161 ESS_input_active 0;
BA_ "GenSigTimeoutTime_BSM" SG_ 161 ESS_input_active 0;
BA_ "GenSigTimeoutTime_BCM" SG_ 161 ESS_input_active 0;
BA_ "GenSigTimeoutTime_AGSM" SG_ 161 ESS_input_active 0;
BA_ "GenSigTimeoutTime_ADCAM" SG_ 161 ESS_input_active 0;
BA_ "GenSigTimeoutTime_SGW" SG_ 161 DBSM2_internal_error 0;
BA_ "GenSigTimeoutTime_RFHM" SG_ 161 DBSM2_internal_error 0;
BA_ "GenSigTimeoutTime_IPC" SG_ 161 DBSM2_internal_error 0;
BA_ "GenSigTimeoutTime_GNMM" SG_ 161 DBSM2_internal_error 0;
BA_ "GenSigTimeoutTime_EVCU2" SG_ 161 DBSM2_internal_error 0;
BA_ "GenSigTimeoutTime_ESL" SG_ 161 DBSM2_internal_error 0;
BA_ "GenSigTimeoutTime_ECM" SG_ 161 DBSM2_internal_error 0;
BA_ "GenSigTimeoutTime_DTCM" SG_ 161 DBSM2_internal_error 0;
BA_ "GenSigTimeoutTime_DMSM" SG_ 161 DBSM2_internal_error 0;
BA_ "GenSigTimeoutTime_BSM" SG_ 161 DBSM2_internal_error 0;
BA_ "GenSigTimeoutTime_BCM" SG_ 161 DBSM2_internal_error 0;
BA_ "GenSigTimeoutTime_AGSM" SG_ 161 DBSM2_internal_error 0;
BA_ "GenSigTimeoutTime_ADCAM" SG_ 161 DBSM2_internal_error 0;
BA_ "GenSigTimeoutTime_SGW" SG_ 161 BATTERY_voltage 0;
BA_ "GenSigTimeoutTime_RFHM" SG_ 161 BATTERY_voltage 0;
BA_ "GenSigTimeoutTime_MPAD" SG_ 161 BATTERY_voltage 0;
BA_ "GenSigTimeoutTime_IPC" SG_ 161 BATTERY_voltage 0;
BA_ "GenSigTimeoutTime_GNMM" SG_ 161 BATTERY_voltage 0;
BA_ "GenSigTimeoutTime_EVCU2" SG_ 161 BATTERY_voltage 0;
BA_ "GenSigTimeoutTime_ESL" SG_ 161 BATTERY_voltage 0;
BA_ "GenSigTimeoutTime_ECM" SG_ 161 BATTERY_voltage 0;
BA_ "GenSigTimeoutTime_DTCM" SG_ 161 BATTERY_voltage 0;
BA_ "GenSigTimeoutTime_DMSM" SG_ 161 BATTERY_voltage 0;
BA_ "GenSigTimeoutTime_BSM" SG_ 161 BATTERY_voltage 0;
BA_ "GenSigTimeoutTime_BCM" SG_ 161 BATTERY_voltage 0;
BA_ "GenSigTimeoutTime_AGSM" SG_ 161 BATTERY_voltage 0;
BA_ "GenSigTimeoutTime_ADCAM" SG_ 161 BATTERY_voltage 0;
BA_ "GenSigStartValue" SG_ 161 BATTERY_voltage 255;
BA_ "GenSigTimeoutTime_SGW" SG_ 161 BATTERY2_voltage 0;
BA_ "GenSigTimeoutTime_RFHM" SG_ 161 BATTERY2_voltage 0;
BA_ "GenSigTimeoutTime_MPAD" SG_ 161 BATTERY2_voltage 0;
BA_ "GenSigTimeoutTime_IPC" SG_ 161 BATTERY2_voltage 0;
BA_ "GenSigTimeoutTime_GNMM" SG_ 161 BATTERY2_voltage 0;
BA_ "GenSigTimeoutTime_EVCU2" SG_ 161 BATTERY2_voltage 0;
BA_ "GenSigTimeoutTime_ESL" SG_ 161 BATTERY2_voltage 0;
BA_ "GenSigTimeoutTime_ECM" SG_ 161 BATTERY2_voltage 0;
BA_ "GenSigTimeoutTime_DTCM" SG_ 161 BATTERY2_voltage 0;
BA_ "GenSigTimeoutTime_DMSM" SG_ 161 BATTERY2_voltage 0;
BA_ "GenSigTimeoutTime_BSM" SG_ 161 BATTERY2_voltage 0;
BA_ "GenSigTimeoutTime_BCM" SG_ 161 BATTERY2_voltage 0;
BA_ "GenSigTimeoutTime_AGSM" SG_ 161 BATTERY2_voltage 0;
BA_ "GenSigTimeoutTime_ADCAM" SG_ 161 BATTERY2_voltage 0;
BA_ "GenSigStartValue" SG_ 161 BATTERY2_voltage 255;
BA_ "GenSigTimeoutTime_SGW" SG_ 161 MC_DBSM2_1 0;
BA_ "GenSigTimeoutTime_RFHM" SG_ 161 MC_DBSM2_1 0;
BA_ "GenSigTimeoutTime_IPC" SG_ 161 MC_DBSM2_1 0;
BA_ "GenSigTimeoutTime_GNMM" SG_ 161 MC_DBSM2_1 0;
BA_ "GenSigTimeoutTime_EVCU2" SG_ 161 MC_DBSM2_1 0;
BA_ "GenSigTimeoutTime_ESL" SG_ 161 MC_DBSM2_1 0;
BA_ "GenSigTimeoutTime_ECM" SG_ 161 MC_DBSM2_1 0;
BA_ "GenSigTimeoutTime_DTCM" SG_ 161 MC_DBSM2_1 0;
BA_ "GenSigTimeoutTime_DMSM" SG_ 161 MC_DBSM2_1 0;
BA_ "GenSigTimeoutTime_BSM" SG_ 161 MC_DBSM2_1 0;
BA_ "GenSigTimeoutTime_BCM" SG_ 161 MC_DBSM2_1 0;
BA_ "GenSigTimeoutTime_AGSM" SG_ 161 MC_DBSM2_1 0;
BA_ "GenSigTimeoutTime_ADCAM" SG_ 161 MC_DBSM2_1 0;
BA_ "GenSigTimeoutTime_SGW" SG_ 161 CRC_DBSM2_1 0;
BA_ "GenSigTimeoutTime_RFHM" SG_ 161 CRC_DBSM2_1 0;
BA_ "GenSigTimeoutTime_IPC" SG_ 161 CRC_DBSM2_1 0;
BA_ "GenSigTimeoutTime_GNMM" SG_ 161 CRC_DBSM2_1 0;
BA_ "GenSigTimeoutTime_EVCU2" SG_ 161 CRC_DBSM2_1 0;
BA_ "GenSigTimeoutTime_ESL" SG_ 161 CRC_DBSM2_1 0;
BA_ "GenSigTimeoutTime_ECM" SG_ 161 CRC_DBSM2_1 0;
BA_ "GenSigTimeoutTime_DTCM" SG_ 161 CRC_DBSM2_1 0;
BA_ "GenSigTimeoutTime_DMSM" SG_ 161 CRC_DBSM2_1 0;
BA_ "GenSigTimeoutTime_BSM" SG_ 161 CRC_DBSM2_1 0;
BA_ "GenSigTimeoutTime_BCM" SG_ 161 CRC_DBSM2_1 0;
BA_ "GenSigTimeoutTime_AGSM" SG_ 161 CRC_DBSM2_1 0;
BA_ "GenSigTimeoutTime_ADCAM" SG_ 161 CRC_DBSM2_1 0;
BA_ "GenSigSendType" SG_ 161 CRC_DBSM2_1 1;
BA_ "GenSigStartValue" SG_ 161 CRC_DBSM2_1 255;
BA_ "GenSigTimeoutTime_MPAD" SG_ 728 Obj04_HorPosLeft 0;
BA_ "GenSigTimeoutTime_SGW" SG_ 1470 SeatPosHAS 0;
BA_ "GenSigTimeoutTime_RFHM" SG_ 1470 SeatPosHAS 0;
BA_ "GenSigTimeoutTime_IPC" SG_ 1470 SeatPosHAS 0;
BA_ "GenSigTimeoutTime_GNMM" SG_ 1470 SeatPosHAS 0;
BA_ "GenSigTimeoutTime_EVCU2" SG_ 1470 SeatPosHAS 0;
BA_ "GenSigTimeoutTime_ESL" SG_ 1470 SeatPosHAS 0;
BA_ "GenSigTimeoutTime_ECM" SG_ 1470 SeatPosHAS 0;
BA_ "GenSigTimeoutTime_DTCM" SG_ 1470 SeatPosHAS 0;
BA_ "GenSigTimeoutTime_DMSM" SG_ 1470 SeatPosHAS 0;
BA_ "GenSigTimeoutTime_BSM" SG_ 1470 SeatPosHAS 0;
BA_ "GenSigTimeoutTime_BCM" SG_ 1470 SeatPosHAS 0;
BA_ "GenSigTimeoutTime_AGSM" SG_ 1470 SeatPosHAS 0;
BA_ "GenSigTimeoutTime_ADCAM" SG_ 1470 SeatPosHAS 0;
BA_ "GenSigSendType" SG_ 1470 SeatPosHAS 3;
BA_ "GenSigTimeoutTime_GNMM" SG_ 1470 DriverSeatRelativePosition 0;
BA_ "GenSigTimeoutTime_EVCU2" SG_ 1470 DriverSeatRelativePosition 0;
BA_ "GenSigTimeoutTime_ESL" SG_ 1470 DriverSeatRelativePosition 0;
BA_ "GenSigTimeoutTime_ECM" SG_ 1470 DriverSeatRelativePosition 0;
BA_ "GenSigTimeoutTime_DTCM" SG_ 1470 DriverSeatRelativePosition 0;
BA_ "GenSigTimeoutTime_DMSM" SG_ 1470 DriverSeatRelativePosition 0;
BA_ "GenSigTimeoutTime_BSM" SG_ 1470 DriverSeatRelativePosition 0;
BA_ "GenSigTimeoutTime_BCM" SG_ 1470 DriverSeatRelativePosition 0;
BA_ "GenSigTimeoutTime_AGSM" SG_ 1470 DriverSeatRelativePosition 0;
BA_ "GenSigTimeoutTime_ADCAM" SG_ 1470 DriverSeatRelativePosition 0;
BA_ "GenSigSendType" SG_ 1470 DriverSeatRelativePosition 3;
BA_ "GenSigTimeoutTime_SGW" SG_ 1470 DriverSeatRelativePosition 0;
BA_ "GenSigTimeoutTime_RFHM" SG_ 1470 DriverSeatRelativePosition 0;
BA_ "GenSigTimeoutTime_IPC" SG_ 1470 DriverSeatRelativePosition 0;
BA_ "GenSigTimeoutTime_SGW" SG_ 1470 MessageCounter_BCM29 0;
BA_ "GenSigTimeoutTime_RFHM" SG_ 1470 MessageCounter_BCM29 0;
BA_ "GenSigTimeoutTime_IPC" SG_ 1470 MessageCounter_BCM29 0;
BA_ "GenSigTimeoutTime_GNMM" SG_ 1470 MessageCounter_BCM29 0;
BA_ "GenSigTimeoutTime_EVCU2" SG_ 1470 MessageCounter_BCM29 0;
BA_ "GenSigTimeoutTime_ESL" SG_ 1470 MessageCounter_BCM29 0;
BA_ "GenSigTimeoutTime_ECM" SG_ 1470 MessageCounter_BCM29 0;
BA_ "GenSigTimeoutTime_DTCM" SG_ 1470 MessageCounter_BCM29 0;
BA_ "GenSigTimeoutTime_DMSM" SG_ 1470 MessageCounter_BCM29 0;
BA_ "GenSigTimeoutTime_BSM" SG_ 1470 MessageCounter_BCM29 0;
BA_ "GenSigTimeoutTime_BCM" SG_ 1470 MessageCounter_BCM29 0;
BA_ "GenSigTimeoutTime_AGSM" SG_ 1470 MessageCounter_BCM29 0;
BA_ "GenSigTimeoutTime_ADCAM" SG_ 1470 MessageCounter_BCM29 0;
BA_ "GenSigTimeoutTime_SGW" SG_ 1470 DriverSeatHorizontalButton 0;
BA_ "GenSigTimeoutTime_RFHM" SG_ 1470 DriverSeatHorizontalButton 0;
BA_ "GenSigTimeoutTime_IPC" SG_ 1470 DriverSeatHorizontalButton 0;
BA_ "GenSigTimeoutTime_GNMM" SG_ 1470 DriverSeatHorizontalButton 0;
BA_ "GenSigTimeoutTime_EVCU2" SG_ 1470 DriverSeatHorizontalButton 0;
BA_ "GenSigTimeoutTime_ESL" SG_ 1470 DriverSeatHorizontalButton 0;
BA_ "GenSigTimeoutTime_ECM" SG_ 1470 DriverSeatHorizontalButton 0;
BA_ "GenSigTimeoutTime_DTCM" SG_ 1470 DriverSeatHorizontalButton 0;
BA_ "GenSigTimeoutTime_DMSM" SG_ 1470 DriverSeatHorizontalButton 0;
BA_ "GenSigTimeoutTime_BSM" SG_ 1470 DriverSeatHorizontalButton 0;
BA_ "GenSigTimeoutTime_BCM" SG_ 1470 DriverSeatHorizontalButton 0;
BA_ "GenSigTimeoutTime_SGW" SG_ 1470 DriverSeatReclinerButton 0;
BA_ "GenSigTimeoutTime_RFHM" SG_ 1470 DriverSeatReclinerButton 0;
BA_ "GenSigTimeoutTime_IPC" SG_ 1470 DriverSeatReclinerButton 0;
BA_ "GenSigTimeoutTime_GNMM" SG_ 1470 DriverSeatReclinerButton 0;
BA_ "GenSigTimeoutTime_EVCU2" SG_ 1470 DriverSeatReclinerButton 0;
BA_ "GenSigTimeoutTime_ESL" SG_ 1470 DriverSeatReclinerButton 0;
BA_ "GenSigTimeoutTime_ECM" SG_ 1470 DriverSeatReclinerButton 0;
BA_ "GenSigTimeoutTime_DTCM" SG_ 1470 DriverSeatReclinerButton 0;
BA_ "GenSigTimeoutTime_DMSM" SG_ 1470 DriverSeatReclinerButton 0;
BA_ "GenSigTimeoutTime_BSM" SG_ 1470 DriverSeatReclinerButton 0;
BA_ "GenSigTimeoutTime_BCM" SG_ 1470 DriverSeatReclinerButton 0;
BA_ "GenSigTimeoutTime_AGSM" SG_ 1470 DriverSeatReclinerButton 0;
BA_ "GenSigTimeoutTime_ADCAM" SG_ 1470 DriverSeatReclinerButton 0;
BA_ "GenSigSendType" SG_ 1470 DriverSeatReclinerButton 3;
BA_ "GenSigTimeoutTime_SGW" SG_ 2651930713 Digit_08_MCPB 0;
BA_ "GenSigTimeoutTime_RFHM" SG_ 2651930713 Digit_08_MCPB 0;
BA_ "GenSigTimeoutTime_MPAD" SG_ 2651930713 Digit_08_MCPB 0;
BA_ "GenSigTimeoutTime_IPC" SG_ 2651930713 Digit_08_MCPB 0;
BA_ "GenSigTimeoutTime_SGW" SG_ 2651930713 Digit_09_MCPB 0;
BA_ "GenSigTimeoutTime_RFHM" SG_ 2651930713 Digit_09_MCPB 0;
BA_ "GenSigTimeoutTime_MPAD" SG_ 2651930713 Digit_09_MCPB 0;
BA_ "GenSigTimeoutTime_IPC" SG_ 2651930713 Digit_09_MCPB 0;
BA_ "GenSigTimeoutTime_GNMM" SG_ 2651930713 Digit_09_MCPB 0;
BA_ "GenSigTimeoutTime_EVCU2" SG_ 2651930713 Digit_09_MCPB 0;
BA_ "GenSigTimeoutTime_ESL" SG_ 2651930713 Digit_09_MCPB 0;
BA_ "GenSigTimeoutTime_ECM" SG_ 2651930713 Digit_09_MCPB 0;
BA_ "GenSigTimeoutTime_DTCM" SG_ 2651930713 Digit_09_MCPB 0;
BA_ "GenSigTimeoutTime_DMSM" SG_ 2651930713 Digit_09_MCPB 0;
BA_ "GenSigTimeoutTime_BSM" SG_ 2651930713 Digit_09_MCPB 0;
BA_ "GenSigTimeoutTime_AGSM" SG_ 2651930713 Digit_09_MCPB 0;
BA_ "GenSigTimeoutTime_ADCAM" SG_ 2651930713 Digit_09_MCPB 0;
BA_ "GenSigTimeoutTime_SGW" SG_ 2651930713 Digit_10_MCPB 0;
BA_ "GenSigTimeoutTime_RFHM" SG_ 2651930713 Digit_10_MCPB 0;
BA_ "GenSigTimeoutTime_MPAD" SG_ 2651930713 Digit_10_MCPB 0;
BA_ "GenSigTimeoutTime_IPC" SG_ 2651930713 Digit_10_MCPB 0;
BA_ "GenSigTimeoutTime_GNMM" SG_ 2651930713 Digit_10_MCPB 0;
BA_ "GenSigTimeoutTime_EVCU2" SG_ 2651930713 Digit_10_MCPB 0;
BA_ "GenSigTimeoutTime_ESL" SG_ 2651930713 Digit_10_MCPB 0;
BA_ "GenSigTimeoutTime_ECM" SG_ 2651930713 Digit_10_MCPB 0;
BA_ "GenSigTimeoutTime_DTCM" SG_ 2651930713 Digit_10_MCPB 0;
BA_ "GenSigTimeoutTime_DMSM" SG_ 2651930713 Digit_10_MCPB 0;
BA_ "GenSigTimeoutTime_BSM" SG_ 2651930713 Digit_10_MCPB 0;
BA_ "GenSigTimeoutTime_AGSM" SG_ 2651930713 Digit_10_MCPB 0;
BA_ "GenSigTimeoutTime_ADCAM" SG_ 2651930713 Digit_10_MCPB 0;
BA_ "GenSigTimeoutTime_ADCAM" SG_ 2651930713 Digit_11_MCPB 0;
BA_ "GenSigTimeoutTime_SGW" SG_ 2651930713 Digit_11_MCPB 0;
BA_ "GenSigTimeoutTime_RFHM" SG_ 2651930713 Digit_11_MCPB 0;
BA_ "GenSigTimeoutTime_MPAD" SG_ 2651930713 Digit_11_MCPB 0;
BA_ "GenSigTimeoutTime_IPC" SG_ 2651930713 Digit_11_MCPB 0;
BA_ "GenSigTimeoutTime_GNMM" SG_ 2651930713 Digit_11_MCPB 0;
BA_ "GenSigTimeoutTime_EVCU2" SG_ 2651930713 Digit_11_MCPB 0;
BA_ "GenSigTimeoutTime_ESL" SG_ 2651930713 Digit_11_MCPB 0;
BA_ "GenSigTimeoutTime_ECM" SG_ 2651930713 Digit_11_MCPB 0;
BA_ "GenSigTimeoutTime_DTCM" SG_ 2651930713 Digit_11_MCPB 0;
BA_ "GenSigTimeoutTime_DMSM" SG_ 2651930713 Digit_11_MCPB 0;
BA_ "GenSigTimeoutTime_BSM" SG_ 2651930713 Digit_11_MCPB 0;
BA_ "GenSigTimeoutTime_AGSM" SG_ 2651930713 Digit_11_MCPB 0;
BA_ "GenSigTimeoutTime_GNMM" SG_ 2651930713 Digit_08_MCPB 0;
BA_ "GenSigTimeoutTime_EVCU2" SG_ 2651930713 Digit_08_MCPB 0;
BA_ "GenSigTimeoutTime_ESL" SG_ 2651930713 Digit_08_MCPB 0;
BA_ "GenSigTimeoutTime_ECM" SG_ 2651930713 Digit_08_MCPB 0;
BA_ "GenSigTimeoutTime_DTCM" SG_ 2651930713 Digit_08_MCPB 0;
BA_ "GenSigTimeoutTime_DMSM" SG_ 2651930713 Digit_08_MCPB 0;
BA_ "GenSigTimeoutTime_BSM" SG_ 2651930713 Digit_08_MCPB 0;
BA_ "GenSigTimeoutTime_AGSM" SG_ 2651930713 Digit_08_MCPB 0;
BA_ "GenSigTimeoutTime_ADCAM" SG_ 2651930713 Digit_08_MCPB 0;
BA_ "GenSigTimeoutTime_SGW" SG_ 2651930713 Digit_07_MCPB 0;
BA_ "GenSigTimeoutTime_RFHM" SG_ 2651930713 Digit_07_MCPB 0;
BA_ "GenSigTimeoutTime_MPAD" SG_ 2651930713 Digit_07_MCPB 0;
BA_ "GenSigTimeoutTime_IPC" SG_ 2651930713 Digit_07_MCPB 0;
BA_ "GenSigTimeoutTime_GNMM" SG_ 2651930713 Digit_07_MCPB 0;
BA_ "GenSigTimeoutTime_EVCU2" SG_ 2651930713 Digit_07_MCPB 0;
BA_ "GenSigTimeoutTime_ESL" SG_ 2651930713 Digit_07_MCPB 0;
BA_ "GenSigTimeoutTime_ECM" SG_ 2651930713 Digit_07_MCPB 0;
BA_ "GenSigTimeoutTime_DTCM" SG_ 2651930713 Digit_07_MCPB 0;
BA_ "GenSigTimeoutTime_DMSM" SG_ 2651930713 Digit_07_MCPB 0;
BA_ "GenSigTimeoutTime_BSM" SG_ 2651930713 Digit_07_MCPB 0;
BA_ "GenSigTimeoutTime_AGSM" SG_ 2651930713 Digit_07_MCPB 0;
BA_ "GenSigTimeoutTime_ADCAM" SG_ 2651930713 Digit_07_MCPB 0;
BA_ "GenSigTimeoutTime_SGW" SG_ 2651930713 Digit_05_MCPB 0;
BA_ "GenSigTimeoutTime_RFHM" SG_ 2651930713 Digit_05_MCPB 0;
BA_ "GenSigTimeoutTime_MPAD" SG_ 2651930713 Digit_05_MCPB 0;
BA_ "GenSigTimeoutTime_IPC" SG_ 2651930713 Digit_05_MCPB 0;
BA_ "GenSigTimeoutTime_GNMM" SG_ 2651930713 Digit_05_MCPB 0;
BA_ "GenSigTimeoutTime_EVCU2" SG_ 2651930713 Digit_05_MCPB 0;
BA_ "GenSigTimeoutTime_ESL" SG_ 2651930713 Digit_05_MCPB 0;
BA_ "GenSigTimeoutTime_ECM" SG_ 2651930713 Digit_05_MCPB 0;
BA_ "GenSigTimeoutTime_DTCM" SG_ 2651930713 Digit_05_MCPB 0;
BA_ "GenSigTimeoutTime_DMSM" SG_ 2651930713 Digit_05_MCPB 0;
BA_ "GenSigTimeoutTime_BSM" SG_ 2651930713 Digit_05_MCPB 0;
BA_ "GenSigTimeoutTime_AGSM" SG_ 2651930713 Digit_05_MCPB 0;
BA_ "GenSigTimeoutTime_ADCAM" SG_ 2651930713 Digit_05_MCPB 0;
BA_ "GenSigTimeoutTime_SGW" SG_ 2651930713 Digit_06_MCPB 0;
BA_ "GenSigTimeoutTime_RFHM" SG_ 2651930713 Digit_06_MCPB 0;
BA_ "GenSigTimeoutTime_MPAD" SG_ 2651930713 Digit_06_MCPB 0;
BA_ "GenSigTimeoutTime_IPC" SG_ 2651930713 Digit_06_MCPB 0;
BA_ "GenSigTimeoutTime_GNMM" SG_ 2651930713 Digit_06_MCPB 0;
BA_ "GenSigTimeoutTime_EVCU2" SG_ 2651930713 Digit_06_MCPB 0;
BA_ "GenSigTimeoutTime_ESL" SG_ 2651930713 Digit_06_MCPB 0;
BA_ "GenSigTimeoutTime_ECM" SG_ 2651930713 Digit_06_MCPB 0;
BA_ "GenSigTimeoutTime_DTCM" SG_ 2651930713 Digit_06_MCPB 0;
BA_ "GenSigTimeoutTime_DMSM" SG_ 2651930713 Digit_06_MCPB 0;
BA_ "GenSigTimeoutTime_BSM" SG_ 2651930713 Digit_06_MCPB 0;
BA_ "GenSigTimeoutTime_AGSM" SG_ 2651930713 Digit_06_MCPB 0;
BA_ "GenSigTimeoutTime_ADCAM" SG_ 2651930713 Digit_06_MCPB 0;
BA_ "GenSigTimeoutTime_SGW" SG_ 2651930712 Digit_08_MCPA 0;
BA_ "GenSigTimeoutTime_RFHM" SG_ 2651930712 Digit_08_MCPA 0;
BA_ "GenSigTimeoutTime_MPAD" SG_ 2651930712 Digit_08_MCPA 0;
BA_ "GenSigTimeoutTime_IPC" SG_ 2651930712 Digit_08_MCPA 0;
BA_ "GenSigTimeoutTime_GNMM" SG_ 2651930712 Digit_08_MCPA 0;
BA_ "GenSigTimeoutTime_EVCU2" SG_ 2651930712 Digit_08_MCPA 0;
BA_ "GenSigTimeoutTime_ESL" SG_ 2651930712 Digit_08_MCPA 0;
BA_ "GenSigTimeoutTime_ECM" SG_ 2651930712 Digit_08_MCPA 0;
BA_ "GenSigTimeoutTime_DTCM" SG_ 2651930712 Digit_08_MCPA 0;
BA_ "GenSigTimeoutTime_DMSM" SG_ 2651930712 Digit_08_MCPA 0;
BA_ "GenSigTimeoutTime_BSM" SG_ 2651930712 Digit_08_MCPA 0;
BA_ "GenSigTimeoutTime_AGSM" SG_ 2651930712 Digit_08_MCPA 0;
BA_ "GenSigTimeoutTime_ADCAM" SG_ 2651930712 Digit_08_MCPA 0;
BA_ "GenSigTimeoutTime_SGW" SG_ 2651930712 Digit_09_MCPA 0;
BA_ "GenSigTimeoutTime_RFHM" SG_ 2651930712 Digit_09_MCPA 0;
BA_ "GenSigTimeoutTime_MPAD" SG_ 2651930712 Digit_09_MCPA 0;
BA_ "GenSigTimeoutTime_IPC" SG_ 2651930712 Digit_09_MCPA 0;
BA_ "GenSigTimeoutTime_GNMM" SG_ 2651930712 Digit_09_MCPA 0;
BA_ "GenSigTimeoutTime_EVCU2" SG_ 2651930712 Digit_09_MCPA 0;
BA_ "GenSigTimeoutTime_ESL" SG_ 2651930712 Digit_09_MCPA 0;
BA_ "GenSigTimeoutTime_ECM" SG_ 2651930712 Digit_09_MCPA 0;
BA_ "GenSigTimeoutTime_DTCM" SG_ 2651930712 Digit_09_MCPA 0;
BA_ "GenSigTimeoutTime_DMSM" SG_ 2651930712 Digit_09_MCPA 0;
BA_ "GenSigTimeoutTime_BSM" SG_ 2651930712 Digit_09_MCPA 0;
BA_ "GenSigTimeoutTime_AGSM" SG_ 2651930712 Digit_09_MCPA 0;
BA_ "GenSigTimeoutTime_ADCAM" SG_ 2651930712 Digit_09_MCPA 0;
BA_ "GenSigTimeoutTime_SGW" SG_ 2651930712 Digit_10_MCPA 0;
BA_ "GenSigTimeoutTime_RFHM" SG_ 2651930712 Digit_10_MCPA 0;
BA_ "GenSigTimeoutTime_MPAD" SG_ 2651930712 Digit_10_MCPA 0;
BA_ "GenSigTimeoutTime_IPC" SG_ 2651930712 Digit_10_MCPA 0;
BA_ "GenSigTimeoutTime_GNMM" SG_ 2651930712 Digit_10_MCPA 0;
BA_ "GenSigTimeoutTime_EVCU2" SG_ 2651930712 Digit_10_MCPA 0;
BA_ "GenSigTimeoutTime_ESL" SG_ 2651930712 Digit_10_MCPA 0;
BA_ "GenSigTimeoutTime_ECM" SG_ 2651930712 Digit_10_MCPA 0;
BA_ "GenSigTimeoutTime_DTCM" SG_ 2651930712 Digit_10_MCPA 0;
BA_ "GenSigTimeoutTime_DMSM" SG_ 2651930712 Digit_10_MCPA 0;
BA_ "GenSigTimeoutTime_BSM" SG_ 2651930712 Digit_10_MCPA 0;
BA_ "GenSigTimeoutTime_AGSM" SG_ 2651930712 Digit_10_MCPA 0;
BA_ "GenSigTimeoutTime_ADCAM" SG_ 2651930712 Digit_10_MCPA 0;
BA_ "GenSigTimeoutTime_SGW" SG_ 2651930712 Digit_11_MCPA 0;
BA_ "GenSigTimeoutTime_RFHM" SG_ 2651930712 Digit_11_MCPA 0;
BA_ "GenSigTimeoutTime_MPAD" SG_ 2651930712 Digit_11_MCPA 0;
BA_ "GenSigTimeoutTime_IPC" SG_ 2651930712 Digit_11_MCPA 0;
BA_ "GenSigTimeoutTime_GNMM" SG_ 2651930712 Digit_11_MCPA 0;
BA_ "GenSigTimeoutTime_EVCU2" SG_ 2651930712 Digit_11_MCPA 0;
BA_ "GenSigTimeoutTime_ESL" SG_ 2651930712 Digit_11_MCPA 0;
BA_ "GenSigTimeoutTime_ECM" SG_ 2651930712 Digit_11_MCPA 0;
BA_ "GenSigTimeoutTime_DTCM" SG_ 2651930712 Digit_11_MCPA 0;
BA_ "GenSigTimeoutTime_DMSM" SG_ 2651930712 Digit_11_MCPA 0;
BA_ "GenSigTimeoutTime_BSM" SG_ 2651930712 Digit_11_MCPA 0;
BA_ "GenSigTimeoutTime_AGSM" SG_ 2651930712 Digit_11_MCPA 0;
BA_ "GenSigTimeoutTime_ADCAM" SG_ 2651930712 Digit_11_MCPA 0;
BA_ "GenSigTimeoutTime_SGW" SG_ 2651930713 Digit_01_MCPB 0;
BA_ "GenSigTimeoutTime_RFHM" SG_ 2651930713 Digit_01_MCPB 0;
BA_ "GenSigTimeoutTime_MPAD" SG_ 2651930713 Digit_01_MCPB 0;
BA_ "GenSigTimeoutTime_IPC" SG_ 2651930713 Digit_01_MCPB 0;
BA_ "GenSigTimeoutTime_GNMM" SG_ 2651930713 Digit_01_MCPB 0;
BA_ "GenSigTimeoutTime_EVCU2" SG_ 2651930713 Digit_01_MCPB 0;
BA_ "GenSigTimeoutTime_ESL" SG_ 2651930713 Digit_01_MCPB 0;
BA_ "GenSigTimeoutTime_ECM" SG_ 2651930713 Digit_01_MCPB 0;
BA_ "GenSigTimeoutTime_DTCM" SG_ 2651930713 Digit_01_MCPB 0;
BA_ "GenSigTimeoutTime_DMSM" SG_ 2651930713 Digit_01_MCPB 0;
BA_ "GenSigTimeoutTime_BSM" SG_ 2651930713 Digit_01_MCPB 0;
BA_ "GenSigTimeoutTime_AGSM" SG_ 2651930713 Digit_01_MCPB 0;
BA_ "GenSigTimeoutTime_ADCAM" SG_ 2651930713 Digit_01_MCPB 0;
BA_ "GenSigSendType" SG_ 2651930713 Digit_01_MCPB 1;
BA_ "GenSigTimeoutTime_SGW" SG_ 2651930713 Digit_02_MCPB 0;
BA_ "GenSigTimeoutTime_RFHM" SG_ 2651930713 Digit_02_MCPB 0;
BA_ "GenSigTimeoutTime_MPAD" SG_ 2651930713 Digit_02_MCPB 0;
BA_ "GenSigTimeoutTime_IPC" SG_ 2651930713 Digit_02_MCPB 0;
BA_ "GenSigTimeoutTime_GNMM" SG_ 2651930713 Digit_02_MCPB 0;
BA_ "GenSigTimeoutTime_EVCU2" SG_ 2651930713 Digit_02_MCPB 0;
BA_ "GenSigTimeoutTime_ESL" SG_ 2651930713 Digit_02_MCPB 0;
BA_ "GenSigTimeoutTime_ECM" SG_ 2651930713 Digit_02_MCPB 0;
BA_ "GenSigTimeoutTime_DTCM" SG_ 2651930713 Digit_02_MCPB 0;
BA_ "GenSigTimeoutTime_DMSM" SG_ 2651930713 Digit_02_MCPB 0;
BA_ "GenSigTimeoutTime_BSM" SG_ 2651930713 Digit_02_MCPB 0;
BA_ "GenSigTimeoutTime_AGSM" SG_ 2651930713 Digit_02_MCPB 0;
BA_ "GenSigTimeoutTime_ADCAM" SG_ 2651930713 Digit_02_MCPB 0;
BA_ "GenSigTimeoutTime_SGW" SG_ 2651930713 Digit_03_MCPB 0;
BA_ "GenSigTimeoutTime_RFHM" SG_ 2651930713 Digit_03_MCPB 0;
BA_ "GenSigTimeoutTime_MPAD" SG_ 2651930713 Digit_03_MCPB 0;
BA_ "GenSigTimeoutTime_IPC" SG_ 2651930713 Digit_03_MCPB 0;
BA_ "GenSigTimeoutTime_GNMM" SG_ 2651930713 Digit_03_MCPB 0;
BA_ "GenSigTimeoutTime_EVCU2" SG_ 2651930713 Digit_03_MCPB 0;
BA_ "GenSigTimeoutTime_ESL" SG_ 2651930713 Digit_03_MCPB 0;
BA_ "GenSigTimeoutTime_ECM" SG_ 2651930713 Digit_03_MCPB 0;
BA_ "GenSigTimeoutTime_DTCM" SG_ 2651930713 Digit_03_MCPB 0;
BA_ "GenSigTimeoutTime_DMSM" SG_ 2651930713 Digit_03_MCPB 0;
BA_ "GenSigTimeoutTime_BSM" SG_ 2651930713 Digit_03_MCPB 0;
BA_ "GenSigTimeoutTime_AGSM" SG_ 2651930713 Digit_03_MCPB 0;
BA_ "GenSigTimeoutTime_ADCAM" SG_ 2651930713 Digit_03_MCPB 0;
BA_ "GenSigTimeoutTime_SGW" SG_ 2651930713 Digit_04_MCPB 0;
BA_ "GenSigTimeoutTime_RFHM" SG_ 2651930713 Digit_04_MCPB 0;
BA_ "GenSigTimeoutTime_MPAD" SG_ 2651930713 Digit_04_MCPB 0;
BA_ "GenSigTimeoutTime_IPC" SG_ 2651930713 Digit_04_MCPB 0;
BA_ "GenSigTimeoutTime_GNMM" SG_ 2651930713 Digit_04_MCPB 0;
BA_ "GenSigTimeoutTime_EVCU2" SG_ 2651930713 Digit_04_MCPB 0;
BA_ "GenSigTimeoutTime_ESL" SG_ 2651930713 Digit_04_MCPB 0;
BA_ "GenSigTimeoutTime_ECM" SG_ 2651930713 Digit_04_MCPB 0;
BA_ "GenSigTimeoutTime_DTCM" SG_ 2651930713 Digit_04_MCPB 0;
BA_ "GenSigTimeoutTime_DMSM" SG_ 2651930713 Digit_04_MCPB 0;
BA_ "GenSigTimeoutTime_BSM" SG_ 2651930713 Digit_04_MCPB 0;
BA_ "GenSigTimeoutTime_AGSM" SG_ 2651930713 Digit_04_MCPB 0;
BA_ "GenSigTimeoutTime_ADCAM" SG_ 2651930713 Digit_04_MCPB 0;
BA_ "GenSigTimeoutTime_SGW" SG_ 2651930712 Digit_01_MCPA 0;
BA_ "GenSigTimeoutTime_RFHM" SG_ 2651930712 Digit_01_MCPA 0;
BA_ "GenSigTimeoutTime_MPAD" SG_ 2651930712 Digit_01_MCPA 0;
BA_ "GenSigTimeoutTime_IPC" SG_ 2651930712 Digit_01_MCPA 0;
BA_ "GenSigTimeoutTime_GNMM" SG_ 2651930712 Digit_01_MCPA 0;
BA_ "GenSigTimeoutTime_EVCU2" SG_ 2651930712 Digit_01_MCPA 0;
BA_ "GenSigTimeoutTime_ESL" SG_ 2651930712 Digit_01_MCPA 0;
BA_ "GenSigTimeoutTime_ECM" SG_ 2651930712 Digit_01_MCPA 0;
BA_ "GenSigTimeoutTime_DTCM" SG_ 2651930712 Digit_01_MCPA 0;
BA_ "GenSigTimeoutTime_DMSM" SG_ 2651930712 Digit_01_MCPA 0;
BA_ "GenSigTimeoutTime_BSM" SG_ 2651930712 Digit_01_MCPA 0;
BA_ "GenSigTimeoutTime_AGSM" SG_ 2651930712 Digit_01_MCPA 0;
BA_ "GenSigTimeoutTime_SGW" SG_ 2651930712 Digit_02_MCPA 0;
BA_ "GenSigTimeoutTime_RFHM" SG_ 2651930712 Digit_02_MCPA 0;
BA_ "GenSigTimeoutTime_MPAD" SG_ 2651930712 Digit_02_MCPA 0;
BA_ "GenSigTimeoutTime_IPC" SG_ 2651930712 Digit_02_MCPA 0;
BA_ "GenSigTimeoutTime_GNMM" SG_ 2651930712 Digit_02_MCPA 0;
BA_ "GenSigTimeoutTime_EVCU2" SG_ 2651930712 Digit_02_MCPA 0;
BA_ "GenSigTimeoutTime_ESL" SG_ 2651930712 Digit_02_MCPA 0;
BA_ "GenSigTimeoutTime_ECM" SG_ 2651930712 Digit_02_MCPA 0;
BA_ "GenSigTimeoutTime_DTCM" SG_ 2651930712 Digit_02_MCPA 0;
BA_ "GenSigTimeoutTime_DMSM" SG_ 2651930712 Digit_02_MCPA 0;
BA_ "GenSigTimeoutTime_BSM" SG_ 2651930712 Digit_02_MCPA 0;
BA_ "GenSigTimeoutTime_AGSM" SG_ 2651930712 Digit_02_MCPA 0;
BA_ "GenSigTimeoutTime_ADCAM" SG_ 2651930712 Digit_02_MCPA 0;
BA_ "GenSigTimeoutTime_GNMM" SG_ 2651930712 Digit_03_MCPA 0;
BA_ "GenSigTimeoutTime_EVCU2" SG_ 2651930712 Digit_03_MCPA 0;
BA_ "GenSigTimeoutTime_ESL" SG_ 2651930712 Digit_03_MCPA 0;
BA_ "GenSigTimeoutTime_ECM" SG_ 2651930712 Digit_03_MCPA 0;
BA_ "GenSigTimeoutTime_DTCM" SG_ 2651930712 Digit_03_MCPA 0;
BA_ "GenSigTimeoutTime_DMSM" SG_ 2651930712 Digit_03_MCPA 0;
BA_ "GenSigTimeoutTime_BSM" SG_ 2651930712 Digit_03_MCPA 0;
BA_ "GenSigTimeoutTime_AGSM" SG_ 2651930712 Digit_03_MCPA 0;
BA_ "GenSigTimeoutTime_ADCAM" SG_ 2651930712 Digit_03_MCPA 0;
BA_ "GenSigTimeoutTime_SGW" SG_ 2651930712 Digit_03_MCPA 0;
BA_ "GenSigTimeoutTime_RFHM" SG_ 2651930712 Digit_03_MCPA 0;
BA_ "GenSigTimeoutTime_MPAD" SG_ 2651930712 Digit_03_MCPA 0;
BA_ "GenSigTimeoutTime_IPC" SG_ 2651930712 Digit_03_MCPA 0;
BA_ "GenSigTimeoutTime_SGW" SG_ 2651930712 Digit_04_MCPA 0;
BA_ "GenSigTimeoutTime_RFHM" SG_ 2651930712 Digit_04_MCPA 0;
BA_ "GenSigTimeoutTime_MPAD" SG_ 2651930712 Digit_04_MCPA 0;
BA_ "GenSigTimeoutTime_IPC" SG_ 2651930712 Digit_04_MCPA 0;
BA_ "GenSigTimeoutTime_GNMM" SG_ 2651930712 Digit_04_MCPA 0;
BA_ "GenSigTimeoutTime_EVCU2" SG_ 2651930712 Digit_04_MCPA 0;
BA_ "GenSigTimeoutTime_ESL" SG_ 2651930712 Digit_04_MCPA 0;
BA_ "GenSigTimeoutTime_ECM" SG_ 2651930712 Digit_04_MCPA 0;
BA_ "GenSigTimeoutTime_DTCM" SG_ 2651930712 Digit_04_MCPA 0;
BA_ "GenSigTimeoutTime_DMSM" SG_ 2651930712 Digit_04_MCPA 0;
BA_ "GenSigTimeoutTime_BSM" SG_ 2651930712 Digit_04_MCPA 0;
BA_ "GenSigTimeoutTime_AGSM" SG_ 2651930712 Digit_04_MCPA 0;
BA_ "GenSigTimeoutTime_ADCAM" SG_ 2651930712 Digit_04_MCPA 0;
BA_ "GenSigTimeoutTime_SGW" SG_ 2651930712 Digit_05_MCPA 0;
BA_ "GenSigTimeoutTime_RFHM" SG_ 2651930712 Digit_05_MCPA 0;
BA_ "GenSigTimeoutTime_MPAD" SG_ 2651930712 Digit_05_MCPA 0;
BA_ "GenSigTimeoutTime_IPC" SG_ 2651930712 Digit_05_MCPA 0;
BA_ "GenSigTimeoutTime_GNMM" SG_ 2651930712 Digit_05_MCPA 0;
BA_ "GenSigTimeoutTime_EVCU2" SG_ 2651930712 Digit_05_MCPA 0;
BA_ "GenSigTimeoutTime_ESL" SG_ 2651930712 Digit_05_MCPA 0;
BA_ "GenSigTimeoutTime_ECM" SG_ 2651930712 Digit_05_MCPA 0;
BA_ "GenSigTimeoutTime_DTCM" SG_ 2651930712 Digit_05_MCPA 0;
BA_ "GenSigTimeoutTime_DMSM" SG_ 2651930712 Digit_05_MCPA 0;
BA_ "GenSigTimeoutTime_BSM" SG_ 2651930712 Digit_05_MCPA 0;
BA_ "GenSigTimeoutTime_AGSM" SG_ 2651930712 Digit_05_MCPA 0;
BA_ "GenSigTimeoutTime_ADCAM" SG_ 2651930712 Digit_05_MCPA 0;
BA_ "GenSigTimeoutTime_SGW" SG_ 2651930712 Digit_06_MCPA 0;
BA_ "GenSigTimeoutTime_RFHM" SG_ 2651930712 Digit_06_MCPA 0;
BA_ "GenSigTimeoutTime_MPAD" SG_ 2651930712 Digit_06_MCPA 0;
BA_ "GenSigTimeoutTime_IPC" SG_ 2651930712 Digit_06_MCPA 0;
BA_ "GenSigTimeoutTime_GNMM" SG_ 2651930712 Digit_06_MCPA 0;
BA_ "GenSigTimeoutTime_EVCU2" SG_ 2651930712 Digit_06_MCPA 0;
BA_ "GenSigTimeoutTime_ESL" SG_ 2651930712 Digit_06_MCPA 0;
BA_ "GenSigTimeoutTime_ECM" SG_ 2651930712 Digit_06_MCPA 0;
BA_ "GenSigTimeoutTime_DTCM" SG_ 2651930712 Digit_06_MCPA 0;
BA_ "GenSigTimeoutTime_DMSM" SG_ 2651930712 Digit_06_MCPA 0;
BA_ "GenSigTimeoutTime_BSM" SG_ 2651930712 Digit_06_MCPA 0;
BA_ "GenSigTimeoutTime_AGSM" SG_ 2651930712 Digit_06_MCPA 0;
BA_ "GenSigTimeoutTime_ADCAM" SG_ 2651930712 Digit_06_MCPA 0;
BA_ "GenSigTimeoutTime_SGW" SG_ 2651930712 Digit_07_MCPA 0;
BA_ "GenSigTimeoutTime_RFHM" SG_ 2651930712 Digit_07_MCPA 0;
BA_ "GenSigTimeoutTime_MPAD" SG_ 2651930712 Digit_07_MCPA 0;
BA_ "GenSigTimeoutTime_IPC" SG_ 2651930712 Digit_07_MCPA 0;
BA_ "GenSigTimeoutTime_GNMM" SG_ 2651930712 Digit_07_MCPA 0;
BA_ "GenSigTimeoutTime_EVCU2" SG_ 2651930712 Digit_07_MCPA 0;
BA_ "GenSigTimeoutTime_ESL" SG_ 2651930712 Digit_07_MCPA 0;
BA_ "GenSigTimeoutTime_ECM" SG_ 2651930712 Digit_07_MCPA 0;
BA_ "GenSigTimeoutTime_DTCM" SG_ 2651930712 Digit_07_MCPA 0;
BA_ "GenSigTimeoutTime_DMSM" SG_ 2651930712 Digit_07_MCPA 0;
BA_ "GenSigTimeoutTime_BSM" SG_ 2651930712 Digit_07_MCPA 0;
BA_ "GenSigTimeoutTime_AGSM" SG_ 2651930712 Digit_07_MCPA 0;
BA_ "GenSigTimeoutTime_ADCAM" SG_ 2651930712 Digit_07_MCPA 0;
BA_ "GenSigTimeoutTime_ADCAM" SG_ 2651930712 Digit_01_MCPA 0;
BA_ "GenSigSendType" SG_ 2651930712 Digit_01_MCPA 1;
BA_ "GenSigTimeoutTime_SGW" SG_ 728 Obj04_ID 0;
BA_ "GenSigTimeoutTime_RFHM" SG_ 728 Obj04_ID 0;
BA_ "GenSigTimeoutTime_MPAD" SG_ 728 Obj04_ID 0;
BA_ "GenSigTimeoutTime_IPC" SG_ 728 Obj04_ID 0;
BA_ "GenSigTimeoutTime_GNMM" SG_ 728 Obj04_ID 0;
BA_ "GenSigTimeoutTime_EVCU2" SG_ 728 Obj04_ID 0;
BA_ "GenSigTimeoutTime_ESL" SG_ 728 Obj04_ID 0;
BA_ "GenSigTimeoutTime_ECM" SG_ 728 Obj04_ID 0;
BA_ "GenSigTimeoutTime_DTCM" SG_ 728 Obj04_ID 0;
BA_ "GenSigTimeoutTime_SGW" SG_ 728 Obj04_VerPos 0;
BA_ "GenSigTimeoutTime_RFHM" SG_ 728 Obj04_VerPos 0;
BA_ "GenSigTimeoutTime_MPAD" SG_ 728 Obj04_VerPos 0;
BA_ "GenSigTimeoutTime_IPC" SG_ 728 Obj04_VerPos 0;
BA_ "GenSigTimeoutTime_GNMM" SG_ 728 Obj04_VerPos 0;
BA_ "GenSigTimeoutTime_EVCU2" SG_ 728 Obj04_VerPos 0;
BA_ "GenSigTimeoutTime_ESL" SG_ 728 Obj04_VerPos 0;
BA_ "GenSigTimeoutTime_ECM" SG_ 728 Obj04_VerPos 0;
BA_ "GenSigTimeoutTime_DTCM" SG_ 728 Obj04_VerPos 0;
BA_ "GenSigTimeoutTime_DMSM" SG_ 728 Obj04_VerPos 0;
BA_ "GenSigTimeoutTime_BSM" SG_ 728 Obj04_VerPos 0;
BA_ "GenSigTimeoutTime_AGSM" SG_ 728 Obj04_VerPos 0;
BA_ "GenSigTimeoutTime_ADCAM" SG_ 728 Obj04_VerPos 0;
BA_ "GenSigStartValue" SG_ 728 Obj04_VerPos 251;
BA_ "GenSigTimeoutTime_SGW" SG_ 728 Obj04_Type 0;
BA_ "GenSigTimeoutTime_RFHM" SG_ 728 Obj04_Type 0;
BA_ "GenSigTimeoutTime_MPAD" SG_ 728 Obj04_Type 0;
BA_ "GenSigTimeoutTime_IPC" SG_ 728 Obj04_Type 0;
BA_ "GenSigTimeoutTime_GNMM" SG_ 728 Obj04_Type 0;
BA_ "GenSigTimeoutTime_EVCU2" SG_ 728 Obj04_Type 0;
BA_ "GenSigTimeoutTime_ESL" SG_ 728 Obj04_Type 0;
BA_ "GenSigTimeoutTime_ECM" SG_ 728 Obj04_Type 0;
BA_ "GenSigTimeoutTime_DTCM" SG_ 728 Obj04_Type 0;
BA_ "GenSigTimeoutTime_DMSM" SG_ 728 Obj04_Type 0;
BA_ "GenSigTimeoutTime_BSM" SG_ 728 Obj04_Type 0;
BA_ "GenSigTimeoutTime_AGSM" SG_ 728 Obj04_Type 0;
BA_ "GenSigTimeoutTime_ADCAM" SG_ 728 Obj04_Type 0;
BA_ "GenSigStartValue" SG_ 728 Obj04_Type 14;
BA_ "GenSigTimeoutTime_SGW" SG_ 728 Road_Illumination 0;
BA_ "GenSigTimeoutTime_RFHM" SG_ 728 Road_Illumination 0;
BA_ "GenSigTimeoutTime_MPAD" SG_ 728 Road_Illumination 0;
BA_ "GenSigTimeoutTime_IPC" SG_ 728 Road_Illumination 0;
BA_ "GenSigTimeoutTime_GNMM" SG_ 728 Road_Illumination 0;
BA_ "GenSigTimeoutTime_EVCU2" SG_ 728 Road_Illumination 0;
BA_ "GenSigTimeoutTime_ESL" SG_ 728 Road_Illumination 0;
BA_ "GenSigTimeoutTime_ECM" SG_ 728 Road_Illumination 0;
BA_ "GenSigTimeoutTime_DTCM" SG_ 728 Road_Illumination 0;
BA_ "GenSigTimeoutTime_DMSM" SG_ 728 Road_Illumination 0;
BA_ "GenSigTimeoutTime_BSM" SG_ 728 Road_Illumination 0;
BA_ "GenSigTimeoutTime_AGSM" SG_ 728 Road_Illumination 0;
BA_ "GenSigTimeoutTime_ADCAM" SG_ 728 Road_Illumination 0;
BA_ "GenSigStartValue" SG_ 728 Road_Illumination 14;
BA_ "GenSigTimeoutTime_DMSM" SG_ 728 Obj04_ID 0;
BA_ "GenSigTimeoutTime_BSM" SG_ 728 Obj04_ID 0;
BA_ "GenSigTimeoutTime_AGSM" SG_ 728 Obj04_ID 0;
BA_ "GenSigTimeoutTime_ADCAM" SG_ 728 Obj04_ID 0;
BA_ "GenSigStartValue" SG_ 728 Obj04_ID 254;
BA_ "GenSigTimeoutTime_SGW" SG_ 728 Obj04_HorSpeed 0;
BA_ "GenSigTimeoutTime_RFHM" SG_ 728 Obj04_HorSpeed 0;
BA_ "GenSigTimeoutTime_MPAD" SG_ 728 Obj04_HorSpeed 0;
BA_ "GenSigTimeoutTime_IPC" SG_ 728 Obj04_HorSpeed 0;
BA_ "GenSigTimeoutTime_GNMM" SG_ 728 Obj04_HorSpeed 0;
BA_ "GenSigTimeoutTime_EVCU2" SG_ 728 Obj04_HorSpeed 0;
BA_ "GenSigTimeoutTime_ESL" SG_ 728 Obj04_HorSpeed 0;
BA_ "GenSigTimeoutTime_ECM" SG_ 728 Obj04_HorSpeed 0;
BA_ "GenSigTimeoutTime_DTCM" SG_ 728 Obj04_HorSpeed 0;
BA_ "GenSigTimeoutTime_DMSM" SG_ 728 Obj04_HorSpeed 0;
BA_ "GenSigTimeoutTime_BSM" SG_ 728 Obj04_HorSpeed 0;
BA_ "GenSigTimeoutTime_AGSM" SG_ 728 Obj04_HorSpeed 0;
BA_ "GenSigTimeoutTime_ADCAM" SG_ 728 Obj04_HorSpeed 0;
BA_ "GenSigStartValue" SG_ 728 Obj04_HorSpeed 4092;
BA_ "GenSigTimeoutTime_SGW" SG_ 728 Obj04_HorPosRight 0;
BA_ "GenSigTimeoutTime_RFHM" SG_ 728 Obj04_HorPosRight 0;
BA_ "GenSigTimeoutTime_MPAD" SG_ 728 Obj04_HorPosRight 0;
BA_ "GenSigTimeoutTime_IPC" SG_ 728 Obj04_HorPosRight 0;
BA_ "GenSigTimeoutTime_GNMM" SG_ 728 Obj04_HorPosRight 0;
BA_ "GenSigTimeoutTime_EVCU2" SG_ 728 Obj04_HorPosRight 0;
BA_ "GenSigTimeoutTime_ESL" SG_ 728 Obj04_HorPosRight 0;
BA_ "GenSigTimeoutTime_ECM" SG_ 728 Obj04_HorPosRight 0;
BA_ "GenSigTimeoutTime_DTCM" SG_ 728 Obj04_HorPosRight 0;
BA_ "GenSigTimeoutTime_DMSM" SG_ 728 Obj04_HorPosRight 0;
BA_ "GenSigTimeoutTime_BSM" SG_ 728 Obj04_HorPosRight 0;
BA_ "GenSigTimeoutTime_AGSM" SG_ 728 Obj04_HorPosRight 0;
BA_ "GenSigTimeoutTime_ADCAM" SG_ 728 Obj04_HorPosRight 0;
BA_ "GenSigStartValue" SG_ 728 Obj04_HorPosRight 4092;
BA_ "GenSigTimeoutTime_SGW" SG_ 728 Obj04_HorPosLeft 0;
BA_ "GenSigTimeoutTime_RFHM" SG_ 728 Obj04_HorPosLeft 0;
BA_ "GenSigTimeoutTime_SGW" SG_ 2651930724 Digit_01_DTV 0;
BA_ "GenSigTimeoutTime_RFHM" SG_ 2651930724 Digit_01_DTV 0;
BA_ "GenSigTimeoutTime_MPAD" SG_ 2651930724 Digit_01_DTV 0;
BA_ "GenSigTimeoutTime_IPC" SG_ 2651930724 Digit_01_DTV 0;
BA_ "GenSigTimeoutTime_GNMM" SG_ 2651930724 Digit_01_DTV 0;
BA_ "GenSigTimeoutTime_EVCU2" SG_ 2651930724 Digit_01_DTV 0;
BA_ "GenSigTimeoutTime_ESL" SG_ 2651930724 Digit_01_DTV 0;
BA_ "GenSigTimeoutTime_ECM" SG_ 2651930724 Digit_01_DTV 0;
BA_ "GenSigTimeoutTime_DTCM" SG_ 2651930724 Digit_01_DTV 0;
BA_ "GenSigTimeoutTime_DMSM" SG_ 2651930724 Digit_01_DTV 0;
BA_ "GenSigTimeoutTime_BSM" SG_ 2651930724 Digit_01_DTV 0;
BA_ "GenSigTimeoutTime_AGSM" SG_ 2651930724 Digit_01_DTV 0;
BA_ "GenSigTimeoutTime_ADCAM" SG_ 2651930724 Digit_01_DTV 0;
BA_ "GenSigSendType" SG_ 2651930724 Digit_01_DTV 1;
BA_ "GenSigTimeoutTime_SGW" SG_ 2651930724 Digit_02_DTV 0;
BA_ "GenSigTimeoutTime_RFHM" SG_ 2651930724 Digit_02_DTV 0;
BA_ "GenSigTimeoutTime_MPAD" SG_ 2651930724 Digit_02_DTV 0;
BA_ "GenSigTimeoutTime_IPC" SG_ 2651930724 Digit_02_DTV 0;
BA_ "GenSigTimeoutTime_GNMM" SG_ 2651930724 Digit_02_DTV 0;
BA_ "GenSigTimeoutTime_EVCU2" SG_ 2651930724 Digit_02_DTV 0;
BA_ "GenSigTimeoutTime_ESL" SG_ 2651930724 Digit_02_DTV 0;
BA_ "GenSigTimeoutTime_ECM" SG_ 2651930724 Digit_02_DTV 0;
BA_ "GenSigTimeoutTime_DTCM" SG_ 2651930724 Digit_02_DTV 0;
BA_ "GenSigTimeoutTime_DMSM" SG_ 2651930724 Digit_02_DTV 0;
BA_ "GenSigTimeoutTime_BSM" SG_ 2651930724 Digit_02_DTV 0;
BA_ "GenSigTimeoutTime_AGSM" SG_ 2651930724 Digit_02_DTV 0;
BA_ "GenSigTimeoutTime_ADCAM" SG_ 2651930724 Digit_02_DTV 0;
BA_ "GenSigTimeoutTime_SGW" SG_ 2651930724 Digit_11_DTV 0;
BA_ "GenSigTimeoutTime_RFHM" SG_ 2651930724 Digit_11_DTV 0;
BA_ "GenSigTimeoutTime_MPAD" SG_ 2651930724 Digit_11_DTV 0;
BA_ "GenSigTimeoutTime_IPC" SG_ 2651930724 Digit_11_DTV 0;
BA_ "GenSigTimeoutTime_GNMM" SG_ 2651930724 Digit_11_DTV 0;
BA_ "GenSigTimeoutTime_EVCU2" SG_ 2651930724 Digit_11_DTV 0;
BA_ "GenSigTimeoutTime_ESL" SG_ 2651930724 Digit_11_DTV 0;
BA_ "GenSigTimeoutTime_ECM" SG_ 2651930724 Digit_11_DTV 0;
BA_ "GenSigTimeoutTime_DTCM" SG_ 2651930724 Digit_11_DTV 0;
BA_ "GenSigTimeoutTime_DMSM" SG_ 2651930724 Digit_11_DTV 0;
BA_ "GenSigTimeoutTime_BSM" SG_ 2651930724 Digit_11_DTV 0;
BA_ "GenSigTimeoutTime_AGSM" SG_ 2651930724 Digit_11_DTV 0;
BA_ "GenSigTimeoutTime_ADCAM" SG_ 2651930724 Digit_11_DTV 0;
BA_ "GenSigTimeoutTime_SGW" SG_ 2651930724 Digit_03_DTV 0;
BA_ "GenSigTimeoutTime_RFHM" SG_ 2651930724 Digit_03_DTV 0;
BA_ "GenSigTimeoutTime_MPAD" SG_ 2651930724 Digit_03_DTV 0;
BA_ "GenSigTimeoutTime_IPC" SG_ 2651930724 Digit_03_DTV 0;
BA_ "GenSigTimeoutTime_GNMM" SG_ 2651930724 Digit_03_DTV 0;
BA_ "GenSigTimeoutTime_EVCU2" SG_ 2651930724 Digit_03_DTV 0;
BA_ "GenSigTimeoutTime_ESL" SG_ 2651930724 Digit_03_DTV 0;
BA_ "GenSigTimeoutTime_ECM" SG_ 2651930724 Digit_03_DTV 0;
BA_ "GenSigTimeoutTime_DTCM" SG_ 2651930724 Digit_03_DTV 0;
BA_ "GenSigTimeoutTime_DMSM" SG_ 2651930724 Digit_03_DTV 0;
BA_ "GenSigTimeoutTime_BSM" SG_ 2651930724 Digit_03_DTV 0;
BA_ "GenSigTimeoutTime_AGSM" SG_ 2651930724 Digit_03_DTV 0;
BA_ "GenSigTimeoutTime_ADCAM" SG_ 2651930724 Digit_03_DTV 0;
BA_ "GenSigTimeoutTime_SGW" SG_ 2651930724 Digit_04_DTV 0;
BA_ "GenSigTimeoutTime_RFHM" SG_ 2651930724 Digit_04_DTV 0;
BA_ "GenSigTimeoutTime_MPAD" SG_ 2651930724 Digit_04_DTV 0;
BA_ "GenSigTimeoutTime_IPC" SG_ 2651930724 Digit_04_DTV 0;
BA_ "GenSigTimeoutTime_GNMM" SG_ 2651930724 Digit_04_DTV 0;
BA_ "GenSigTimeoutTime_EVCU2" SG_ 2651930724 Digit_04_DTV 0;
BA_ "GenSigTimeoutTime_ESL" SG_ 2651930724 Digit_04_DTV 0;
BA_ "GenSigTimeoutTime_ECM" SG_ 2651930724 Digit_04_DTV 0;
BA_ "GenSigTimeoutTime_DTCM" SG_ 2651930724 Digit_04_DTV 0;
BA_ "GenSigTimeoutTime_DMSM" SG_ 2651930724 Digit_04_DTV 0;
BA_ "GenSigTimeoutTime_BSM" SG_ 2651930724 Digit_04_DTV 0;
BA_ "GenSigTimeoutTime_AGSM" SG_ 2651930724 Digit_04_DTV 0;
BA_ "GenSigTimeoutTime_ADCAM" SG_ 2651930724 Digit_04_DTV 0;
BA_ "GenSigTimeoutTime_SGW" SG_ 2651930724 Digit_05_DTV 0;
BA_ "GenSigTimeoutTime_RFHM" SG_ 2651930724 Digit_05_DTV 0;
BA_ "GenSigTimeoutTime_MPAD" SG_ 2651930724 Digit_05_DTV 0;
BA_ "GenSigTimeoutTime_IPC" SG_ 2651930724 Digit_05_DTV 0;
BA_ "GenSigTimeoutTime_GNMM" SG_ 2651930724 Digit_05_DTV 0;
BA_ "GenSigTimeoutTime_EVCU2" SG_ 2651930724 Digit_05_DTV 0;
BA_ "GenSigTimeoutTime_ESL" SG_ 2651930724 Digit_05_DTV 0;
BA_ "GenSigTimeoutTime_ECM" SG_ 2651930724 Digit_05_DTV 0;
BA_ "GenSigTimeoutTime_DTCM" SG_ 2651930724 Digit_05_DTV 0;
BA_ "GenSigTimeoutTime_DMSM" SG_ 2651930724 Digit_05_DTV 0;
BA_ "GenSigTimeoutTime_BSM" SG_ 2651930724 Digit_05_DTV 0;
BA_ "GenSigTimeoutTime_AGSM" SG_ 2651930724 Digit_05_DTV 0;
BA_ "GenSigTimeoutTime_ADCAM" SG_ 2651930724 Digit_05_DTV 0;
BA_ "GenSigTimeoutTime_SGW" SG_ 2651930724 Digit_06_DTV 0;
BA_ "GenSigTimeoutTime_RFHM" SG_ 2651930724 Digit_06_DTV 0;
BA_ "GenSigTimeoutTime_MPAD" SG_ 2651930724 Digit_06_DTV 0;
BA_ "GenSigTimeoutTime_IPC" SG_ 2651930724 Digit_06_DTV 0;
BA_ "GenSigTimeoutTime_GNMM" SG_ 2651930724 Digit_06_DTV 0;
BA_ "GenSigTimeoutTime_EVCU2" SG_ 2651930724 Digit_06_DTV 0;
BA_ "GenSigTimeoutTime_ESL" SG_ 2651930724 Digit_06_DTV 0;
BA_ "GenSigTimeoutTime_ECM" SG_ 2651930724 Digit_06_DTV 0;
BA_ "GenSigTimeoutTime_DTCM" SG_ 2651930724 Digit_06_DTV 0;
BA_ "GenSigTimeoutTime_DMSM" SG_ 2651930724 Digit_06_DTV 0;
BA_ "GenSigTimeoutTime_BSM" SG_ 2651930724 Digit_06_DTV 0;
BA_ "GenSigTimeoutTime_AGSM" SG_ 2651930724 Digit_06_DTV 0;
BA_ "GenSigTimeoutTime_ADCAM" SG_ 2651930724 Digit_06_DTV 0;
BA_ "GenSigTimeoutTime_SGW" SG_ 2651930724 Digit_07_DTV 0;
BA_ "GenSigTimeoutTime_RFHM" SG_ 2651930724 Digit_07_DTV 0;
BA_ "GenSigTimeoutTime_MPAD" SG_ 2651930724 Digit_07_DTV 0;
BA_ "GenSigTimeoutTime_IPC" SG_ 2651930724 Digit_07_DTV 0;
BA_ "GenSigTimeoutTime_GNMM" SG_ 2651930724 Digit_07_DTV 0;
BA_ "GenSigTimeoutTime_EVCU2" SG_ 2651930724 Digit_07_DTV 0;
BA_ "GenSigTimeoutTime_ESL" SG_ 2651930724 Digit_07_DTV 0;
BA_ "GenSigTimeoutTime_ECM" SG_ 2651930724 Digit_07_DTV 0;
BA_ "GenSigTimeoutTime_DTCM" SG_ 2651930724 Digit_07_DTV 0;
BA_ "GenSigTimeoutTime_DMSM" SG_ 2651930724 Digit_07_DTV 0;
BA_ "GenSigTimeoutTime_BSM" SG_ 2651930724 Digit_07_DTV 0;
BA_ "GenSigTimeoutTime_AGSM" SG_ 2651930724 Digit_07_DTV 0;
BA_ "GenSigTimeoutTime_ADCAM" SG_ 2651930724 Digit_07_DTV 0;
BA_ "GenSigTimeoutTime_SGW" SG_ 2651930724 Digit_08_DTV 0;
BA_ "GenSigTimeoutTime_RFHM" SG_ 2651930724 Digit_08_DTV 0;
BA_ "GenSigTimeoutTime_MPAD" SG_ 2651930724 Digit_08_DTV 0;
BA_ "GenSigTimeoutTime_IPC" SG_ 2651930724 Digit_08_DTV 0;
BA_ "GenSigTimeoutTime_GNMM" SG_ 2651930724 Digit_08_DTV 0;
BA_ "GenSigTimeoutTime_EVCU2" SG_ 2651930724 Digit_08_DTV 0;
BA_ "GenSigTimeoutTime_ESL" SG_ 2651930724 Digit_08_DTV 0;
BA_ "GenSigTimeoutTime_ECM" SG_ 2651930724 Digit_08_DTV 0;
BA_ "GenSigTimeoutTime_DTCM" SG_ 2651930724 Digit_08_DTV 0;
BA_ "GenSigTimeoutTime_DMSM" SG_ 2651930724 Digit_08_DTV 0;
BA_ "GenSigTimeoutTime_BSM" SG_ 2651930724 Digit_08_DTV 0;
BA_ "GenSigTimeoutTime_AGSM" SG_ 2651930724 Digit_08_DTV 0;
BA_ "GenSigTimeoutTime_ADCAM" SG_ 2651930724 Digit_08_DTV 0;
BA_ "GenSigTimeoutTime_SGW" SG_ 2651930724 Digit_09_DTV 0;
BA_ "GenSigTimeoutTime_RFHM" SG_ 2651930724 Digit_09_DTV 0;
BA_ "GenSigTimeoutTime_MPAD" SG_ 2651930724 Digit_09_DTV 0;
BA_ "GenSigTimeoutTime_IPC" SG_ 2651930724 Digit_09_DTV 0;
BA_ "GenSigTimeoutTime_GNMM" SG_ 2651930724 Digit_09_DTV 0;
BA_ "GenSigTimeoutTime_EVCU2" SG_ 2651930724 Digit_09_DTV 0;
BA_ "GenSigTimeoutTime_ESL" SG_ 2651930724 Digit_09_DTV 0;
BA_ "GenSigTimeoutTime_ECM" SG_ 2651930724 Digit_09_DTV 0;
BA_ "GenSigTimeoutTime_DTCM" SG_ 2651930724 Digit_09_DTV 0;
BA_ "GenSigTimeoutTime_DMSM" SG_ 2651930724 Digit_09_DTV 0;
BA_ "GenSigTimeoutTime_BSM" SG_ 2651930724 Digit_09_DTV 0;
BA_ "GenSigTimeoutTime_AGSM" SG_ 2651930724 Digit_09_DTV 0;
BA_ "GenSigTimeoutTime_ADCAM" SG_ 2651930724 Digit_09_DTV 0;
BA_ "GenSigTimeoutTime_SGW" SG_ 2651930724 Digit_10_DTV 0;
BA_ "GenSigTimeoutTime_RFHM" SG_ 2651930724 Digit_10_DTV 0;
BA_ "GenSigTimeoutTime_MPAD" SG_ 2651930724 Digit_10_DTV 0;
BA_ "GenSigTimeoutTime_IPC" SG_ 2651930724 Digit_10_DTV 0;
BA_ "GenSigTimeoutTime_GNMM" SG_ 2651930724 Digit_10_DTV 0;
BA_ "GenSigTimeoutTime_EVCU2" SG_ 2651930724 Digit_10_DTV 0;
BA_ "GenSigTimeoutTime_ESL" SG_ 2651930724 Digit_10_DTV 0;
BA_ "GenSigTimeoutTime_ECM" SG_ 2651930724 Digit_10_DTV 0;
BA_ "GenSigTimeoutTime_DTCM" SG_ 2651930724 Digit_10_DTV 0;
BA_ "GenSigTimeoutTime_DMSM" SG_ 2651930724 Digit_10_DTV 0;
BA_ "GenSigTimeoutTime_BSM" SG_ 2651930724 Digit_10_DTV 0;
BA_ "GenSigTimeoutTime_AGSM" SG_ 2651930724 Digit_10_DTV 0;
BA_ "GenSigTimeoutTime_ADCAM" SG_ 2651930724 Digit_10_DTV 0;
BA_ "GenSigTimeoutTime_SGW" SG_ 525 TimeStamp 0;
BA_ "GenSigTimeoutTime_RFHM" SG_ 525 TimeStamp 0;
BA_ "GenSigTimeoutTime_IPC" SG_ 525 TimeStamp 0;
BA_ "GenSigTimeoutTime_GNMM" SG_ 525 TimeStamp 0;
BA_ "GenSigTimeoutTime_EVCU2" SG_ 525 TimeStamp 0;
BA_ "GenSigTimeoutTime_ESL" SG_ 525 TimeStamp 0;
BA_ "GenSigTimeoutTime_ECM" SG_ 525 TimeStamp 0;
BA_ "GenSigTimeoutTime_DTCM" SG_ 525 TimeStamp 0;
BA_ "GenSigTimeoutTime_DMSM" SG_ 525 TimeStamp 0;
BA_ "GenSigTimeoutTime_BSM" SG_ 525 TimeStamp 0;
BA_ "GenSigTimeoutTime_BCM" SG_ 525 TimeStamp 0;
BA_ "GenSigTimeoutTime_AGSM" SG_ 525 TimeStamp 0;
BA_ "GenSigTimeoutTime_ADCAM" SG_ 525 TimeStamp 0;
BA_ "GenSigTimeoutTime_SGW" SG_ 525 StbmTimestampSec_GNMM 0;
BA_ "GenSigTimeoutTime_RFHM" SG_ 525 StbmTimestampSec_GNMM 0;
BA_ "GenSigTimeoutTime_IPC" SG_ 525 StbmTimestampSec_GNMM 0;
BA_ "GenSigTimeoutTime_GNMM" SG_ 525 StbmTimestampSec_GNMM 0;
BA_ "GenSigTimeoutTime_EVCU2" SG_ 525 StbmTimestampSec_GNMM 0;
BA_ "GenSigTimeoutTime_ESL" SG_ 525 StbmTimestampSec_GNMM 0;
BA_ "GenSigTimeoutTime_ECM" SG_ 525 StbmTimestampSec_GNMM 0;
BA_ "GenSigTimeoutTime_DTCM" SG_ 525 StbmTimestampSec_GNMM 0;
BA_ "GenSigTimeoutTime_DMSM" SG_ 525 StbmTimestampSec_GNMM 0;
BA_ "GenSigTimeoutTime_BSM" SG_ 525 StbmTimestampSec_GNMM 0;
BA_ "GenSigTimeoutTime_BCM" SG_ 525 StbmTimestampSec_GNMM 0;
BA_ "GenSigTimeoutTime_AGSM" SG_ 525 StbmTimestampSec_GNMM 0;
BA_ "GenSigTimeoutTime_ADCAM" SG_ 525 StbmTimestampSec_GNMM 0;
BA_ "GenSigTimeoutTime_SGW" SG_ 525 StbmTimestampNSec_GNMM 0;
BA_ "GenSigTimeoutTime_RFHM" SG_ 525 StbmTimestampNSec_GNMM 0;
BA_ "GenSigTimeoutTime_IPC" SG_ 525 StbmTimestampNSec_GNMM 0;
BA_ "GenSigTimeoutTime_GNMM" SG_ 525 StbmTimestampNSec_GNMM 0;
BA_ "GenSigTimeoutTime_EVCU2" SG_ 525 StbmTimestampNSec_GNMM 0;
BA_ "GenSigTimeoutTime_ESL" SG_ 525 StbmTimestampNSec_GNMM 0;
BA_ "GenSigTimeoutTime_ECM" SG_ 525 StbmTimestampNSec_GNMM 0;
BA_ "GenSigTimeoutTime_DTCM" SG_ 525 StbmTimestampNSec_GNMM 0;
BA_ "GenSigTimeoutTime_DMSM" SG_ 525 StbmTimestampNSec_GNMM 0;
BA_ "GenSigTimeoutTime_BSM" SG_ 525 StbmTimestampNSec_GNMM 0;
BA_ "GenSigTimeoutTime_BCM" SG_ 525 StbmTimestampNSec_GNMM 0;
BA_ "GenSigTimeoutTime_AGSM" SG_ 525 StbmTimestampNSec_GNMM 0;
BA_ "GenSigTimeoutTime_ADCAM" SG_ 525 StbmTimestampNSec_GNMM 0;
BA_ "GenSigTimeoutTime_SGW" SG_ 525 StbmSyncState_GNMM 0;
BA_ "GenSigTimeoutTime_RFHM" SG_ 525 StbmSyncState_GNMM 0;
BA_ "GenSigTimeoutTime_IPC" SG_ 525 StbmSyncState_GNMM 0;
BA_ "GenSigTimeoutTime_GNMM" SG_ 525 StbmSyncState_GNMM 0;
BA_ "GenSigTimeoutTime_EVCU2" SG_ 525 StbmSyncState_GNMM 0;
BA_ "GenSigTimeoutTime_ESL" SG_ 525 StbmSyncState_GNMM 0;
BA_ "GenSigTimeoutTime_ECM" SG_ 525 StbmSyncState_GNMM 0;
BA_ "GenSigTimeoutTime_DTCM" SG_ 525 StbmSyncState_GNMM 0;
BA_ "GenSigTimeoutTime_DMSM" SG_ 525 StbmSyncState_GNMM 0;
BA_ "GenSigTimeoutTime_BSM" SG_ 525 StbmSyncState_GNMM 0;
BA_ "GenSigTimeoutTime_BCM" SG_ 525 StbmSyncState_GNMM 0;
BA_ "GenSigTimeoutTime_AGSM" SG_ 525 StbmSyncState_GNMM 0;
BA_ "GenSigTimeoutTime_ADCAM" SG_ 525 StbmSyncState_GNMM 0;
BA_ "GenSigStartValue" SG_ 525 StbmSyncState_GNMM 255;
BA_ "GenSigTimeoutTime_SGW" SG_ 525 StatusReceiver 0;
BA_ "GenSigTimeoutTime_RFHM" SG_ 525 StatusReceiver 0;
BA_ "GenSigTimeoutTime_IPC" SG_ 525 StatusReceiver 0;
BA_ "GenSigTimeoutTime_GNMM" SG_ 525 StatusReceiver 0;
BA_ "GenSigTimeoutTime_EVCU2" SG_ 525 StatusReceiver 0;
BA_ "GenSigTimeoutTime_ESL" SG_ 525 StatusReceiver 0;
BA_ "GenSigTimeoutTime_ECM" SG_ 525 StatusReceiver 0;
BA_ "GenSigTimeoutTime_DTCM" SG_ 525 StatusReceiver 0;
BA_ "GenSigTimeoutTime_DMSM" SG_ 525 StatusReceiver 0;
BA_ "GenSigTimeoutTime_BSM" SG_ 525 StatusReceiver 0;
BA_ "GenSigTimeoutTime_BCM" SG_ 525 StatusReceiver 0;
BA_ "GenSigTimeoutTime_AGSM" SG_ 525 StatusReceiver 0;
BA_ "GenSigTimeoutTime_ADCAM" SG_ 525 StatusReceiver 0;
BA_ "GenSigTimeoutTime_SGW" SG_ 525 Reserved_Func_Safety_GLOBNAV_2 0;
BA_ "GenSigTimeoutTime_RFHM" SG_ 525 Reserved_Func_Safety_GLOBNAV_2 0;
BA_ "GenSigTimeoutTime_IPC" SG_ 525 Reserved_Func_Safety_GLOBNAV_2 0;
BA_ "GenSigTimeoutTime_GNMM" SG_ 525 Reserved_Func_Safety_GLOBNAV_2 0;
BA_ "GenSigTimeoutTime_EVCU2" SG_ 525 Reserved_Func_Safety_GLOBNAV_2 0;
BA_ "GenSigTimeoutTime_ESL" SG_ 525 Reserved_Func_Safety_GLOBNAV_2 0;
BA_ "GenSigTimeoutTime_ECM" SG_ 525 Reserved_Func_Safety_GLOBNAV_2 0;
BA_ "GenSigTimeoutTime_DTCM" SG_ 525 Reserved_Func_Safety_GLOBNAV_2 0;
BA_ "GenSigTimeoutTime_DMSM" SG_ 525 Reserved_Func_Safety_GLOBNAV_2 0;
BA_ "GenSigTimeoutTime_BSM" SG_ 525 Reserved_Func_Safety_GLOBNAV_2 0;
BA_ "GenSigTimeoutTime_AGSM" SG_ 525 Reserved_Func_Safety_GLOBNAV_2 0;
BA_ "GenSigTimeoutTime_ADCAM" SG_ 525 Reserved_Func_Safety_GLOBNAV_2 0;
BA_ "GenSigTimeoutTime_ADCAM" SG_ 525 Reserved_for_Func_Safety_GLOBNAV 0;
BA_ "GenSigTimeoutTime_SGW" SG_ 525 Reserved_for_Func_Safety_GLOBNAV 0;
BA_ "GenSigTimeoutTime_RFHM" SG_ 525 Reserved_for_Func_Safety_GLOBNAV 0;
BA_ "GenSigTimeoutTime_IPC" SG_ 525 Reserved_for_Func_Safety_GLOBNAV 0;
BA_ "GenSigTimeoutTime_GNMM" SG_ 525 Reserved_for_Func_Safety_GLOBNAV 0;
BA_ "GenSigTimeoutTime_EVCU2" SG_ 525 Reserved_for_Func_Safety_GLOBNAV 0;
BA_ "GenSigTimeoutTime_ESL" SG_ 525 Reserved_for_Func_Safety_GLOBNAV 0;
BA_ "GenSigTimeoutTime_ECM" SG_ 525 Reserved_for_Func_Safety_GLOBNAV 0;
BA_ "GenSigTimeoutTime_DTCM" SG_ 525 Reserved_for_Func_Safety_GLOBNAV 0;
BA_ "GenSigTimeoutTime_DMSM" SG_ 525 Reserved_for_Func_Safety_GLOBNAV 0;
BA_ "GenSigTimeoutTime_BSM" SG_ 525 Reserved_for_Func_Safety_GLOBNAV 0;
BA_ "GenSigTimeoutTime_AGSM" SG_ 525 Reserved_for_Func_Safety_GLOBNAV 0;
BA_ "GenSigTimeoutTime_SGW" SG_ 525 NumOfSatellites 0;
BA_ "GenSigTimeoutTime_RFHM" SG_ 525 NumOfSatellites 0;
BA_ "GenSigTimeoutTime_IPC" SG_ 525 NumOfSatellites 0;
BA_ "GenSigTimeoutTime_GNMM" SG_ 525 NumOfSatellites 0;
BA_ "GenSigTimeoutTime_EVCU2" SG_ 525 NumOfSatellites 0;
BA_ "GenSigTimeoutTime_SGW" SG_ 525 VerticalAcceleration_GNMM 0;
BA_ "GenSigTimeoutTime_RFHM" SG_ 525 VerticalAcceleration_GNMM 0;
BA_ "GenSigTimeoutTime_IPC" SG_ 525 VerticalAcceleration_GNMM 0;
BA_ "GenSigTimeoutTime_GNMM" SG_ 525 VerticalAcceleration_GNMM 0;
BA_ "GenSigTimeoutTime_EVCU2" SG_ 525 VerticalAcceleration_GNMM 0;
BA_ "GenSigTimeoutTime_ESL" SG_ 525 VerticalAcceleration_GNMM 0;
BA_ "GenSigTimeoutTime_ECM" SG_ 525 VerticalAcceleration_GNMM 0;
BA_ "GenSigTimeoutTime_DTCM" SG_ 525 VerticalAcceleration_GNMM 0;
BA_ "GenSigTimeoutTime_DMSM" SG_ 525 VerticalAcceleration_GNMM 0;
BA_ "GenSigTimeoutTime_BSM" SG_ 525 VerticalAcceleration_GNMM 0;
BA_ "GenSigTimeoutTime_AGSM" SG_ 525 VerticalAcceleration_GNMM 0;
BA_ "GenSigTimeoutTime_ADCAM" SG_ 525 VerticalAcceleration_GNMM 0;
BA_ "GenSigStartValue" SG_ 525 VerticalAcceleration_GNMM 4095;
BA_ "GenSigTimeoutTime_SGW" SG_ 525 RollRate_GNMM 0;
BA_ "GenSigTimeoutTime_RFHM" SG_ 525 RollRate_GNMM 0;
BA_ "GenSigTimeoutTime_IPC" SG_ 525 RollRate_GNMM 0;
BA_ "GenSigTimeoutTime_GNMM" SG_ 525 RollRate_GNMM 0;
BA_ "GenSigTimeoutTime_EVCU2" SG_ 525 RollRate_GNMM 0;
BA_ "GenSigTimeoutTime_ESL" SG_ 525 RollRate_GNMM 0;
BA_ "GenSigTimeoutTime_ECM" SG_ 525 RollRate_GNMM 0;
BA_ "GenSigTimeoutTime_DTCM" SG_ 525 RollRate_GNMM 0;
BA_ "GenSigTimeoutTime_DMSM" SG_ 525 RollRate_GNMM 0;
BA_ "GenSigTimeoutTime_BSM" SG_ 525 RollRate_GNMM 0;
BA_ "GenSigTimeoutTime_AGSM" SG_ 525 RollRate_GNMM 0;
BA_ "GenSigTimeoutTime_ADCAM" SG_ 525 RollRate_GNMM 0;
BA_ "GenSigStartValue" SG_ 525 RollRate_GNMM 4095;
BA_ "GenSigTimeoutTime_SGW" SG_ 525 PitchRate_GNMM 0;
BA_ "GenSigTimeoutTime_RFHM" SG_ 525 PitchRate_GNMM 0;
BA_ "GenSigTimeoutTime_IPC" SG_ 525 PitchRate_GNMM 0;
BA_ "GenSigTimeoutTime_GNMM" SG_ 525 PitchRate_GNMM 0;
BA_ "GenSigTimeoutTime_EVCU2" SG_ 525 PitchRate_GNMM 0;
BA_ "GenSigTimeoutTime_ESL" SG_ 525 PitchRate_GNMM 0;
BA_ "GenSigTimeoutTime_ECM" SG_ 525 PitchRate_GNMM 0;
BA_ "GenSigTimeoutTime_DTCM" SG_ 525 PitchRate_GNMM 0;
BA_ "GenSigTimeoutTime_DMSM" SG_ 525 PitchRate_GNMM 0;
BA_ "GenSigTimeoutTime_BSM" SG_ 525 PitchRate_GNMM 0;
BA_ "GenSigTimeoutTime_AGSM" SG_ 525 PitchRate_GNMM 0;
BA_ "GenSigTimeoutTime_ADCAM" SG_ 525 PitchRate_GNMM 0;
BA_ "GenSigStartValue" SG_ 525 PitchRate_GNMM 4095;
BA_ "GenSigTimeoutTime_SGW" SG_ 525 YawRate_RMSE 0;
BA_ "GenSigTimeoutTime_RFHM" SG_ 525 YawRate_RMSE 0;
BA_ "GenSigTimeoutTime_IPC" SG_ 525 YawRate_RMSE 0;
BA_ "GenSigTimeoutTime_GNMM" SG_ 525 YawRate_RMSE 0;
BA_ "GenSigTimeoutTime_EVCU2" SG_ 525 YawRate_RMSE 0;
BA_ "GenSigTimeoutTime_ESL" SG_ 525 YawRate_RMSE 0;
BA_ "GenSigTimeoutTime_ECM" SG_ 525 YawRate_RMSE 0;
BA_ "GenSigTimeoutTime_DTCM" SG_ 525 YawRate_RMSE 0;
BA_ "GenSigTimeoutTime_DMSM" SG_ 525 YawRate_RMSE 0;
BA_ "GenSigTimeoutTime_BSM" SG_ 525 YawRate_RMSE 0;
BA_ "GenSigTimeoutTime_AGSM" SG_ 525 YawRate_RMSE 0;
BA_ "GenSigTimeoutTime_ADCAM" SG_ 525 YawRate_RMSE 0;
BA_ "GenSigStartValue" SG_ 525 YawRate_RMSE 255;
BA_ "GenSigTimeoutTime_SGW" SG_ 525 Roll_RMSE 0;
BA_ "GenSigTimeoutTime_RFHM" SG_ 525 Roll_RMSE 0;
BA_ "GenSigTimeoutTime_IPC" SG_ 525 Roll_RMSE 0;
BA_ "GenSigTimeoutTime_GNMM" SG_ 525 Roll_RMSE 0;
BA_ "GenSigTimeoutTime_EVCU2" SG_ 525 Roll_RMSE 0;
BA_ "GenSigTimeoutTime_ESL" SG_ 525 Roll_RMSE 0;
BA_ "GenSigTimeoutTime_ECM" SG_ 525 Roll_RMSE 0;
BA_ "GenSigTimeoutTime_DTCM" SG_ 525 Roll_RMSE 0;
BA_ "GenSigTimeoutTime_DMSM" SG_ 525 Roll_RMSE 0;
BA_ "GenSigTimeoutTime_BSM" SG_ 525 Roll_RMSE 0;
BA_ "GenSigTimeoutTime_AGSM" SG_ 525 Roll_RMSE 0;
BA_ "GenSigTimeoutTime_ADCAM" SG_ 525 Roll_RMSE 0;
BA_ "GenSigStartValue" SG_ 525 Roll_RMSE 255;
BA_ "GenSigTimeoutTime_SGW" SG_ 525 Pitch_RMSE 0;
BA_ "GenSigTimeoutTime_RFHM" SG_ 525 Pitch_RMSE 0;
BA_ "GenSigTimeoutTime_IPC" SG_ 525 Pitch_RMSE 0;
BA_ "GenSigTimeoutTime_GNMM" SG_ 525 Pitch_RMSE 0;
BA_ "GenSigTimeoutTime_EVCU2" SG_ 525 Pitch_RMSE 0;
BA_ "GenSigTimeoutTime_ESL" SG_ 525 Pitch_RMSE 0;
BA_ "GenSigTimeoutTime_ECM" SG_ 525 Pitch_RMSE 0;
BA_ "GenSigTimeoutTime_DTCM" SG_ 525 Pitch_RMSE 0;
BA_ "GenSigTimeoutTime_DMSM" SG_ 525 Pitch_RMSE 0;
BA_ "GenSigTimeoutTime_BSM" SG_ 525 Pitch_RMSE 0;
BA_ "GenSigTimeoutTime_AGSM" SG_ 525 Pitch_RMSE 0;
BA_ "GenSigTimeoutTime_ADCAM" SG_ 525 Pitch_RMSE 0;
BA_ "GenSigStartValue" SG_ 525 Pitch_RMSE 255;
BA_ "GenSigTimeoutTime_SGW" SG_ 525 YawRate_GNMM 0;
BA_ "GenSigTimeoutTime_RFHM" SG_ 525 YawRate_GNMM 0;
BA_ "GenSigTimeoutTime_IPC" SG_ 525 YawRate_GNMM 0;
BA_ "GenSigTimeoutTime_GNMM" SG_ 525 YawRate_GNMM 0;
BA_ "GenSigTimeoutTime_EVCU2" SG_ 525 YawRate_GNMM 0;
BA_ "GenSigTimeoutTime_ESL" SG_ 525 YawRate_GNMM 0;
BA_ "GenSigTimeoutTime_ECM" SG_ 525 YawRate_GNMM 0;
BA_ "GenSigTimeoutTime_DTCM" SG_ 525 YawRate_GNMM 0;
BA_ "GenSigTimeoutTime_DMSM" SG_ 525 YawRate_GNMM 0;
BA_ "GenSigTimeoutTime_BSM" SG_ 525 YawRate_GNMM 0;
BA_ "GenSigTimeoutTime_AGSM" SG_ 525 YawRate_GNMM 0;
BA_ "GenSigTimeoutTime_ADCAM" SG_ 525 YawRate_GNMM 0;
BA_ "GenSigStartValue" SG_ 525 YawRate_GNMM 32767;
BA_ "GenSigTimeoutTime_SGW" SG_ 525 VerticalVelocity_GNMM 0;
BA_ "GenSigTimeoutTime_RFHM" SG_ 525 VerticalVelocity_GNMM 0;
BA_ "GenSigTimeoutTime_IPC" SG_ 525 VerticalVelocity_GNMM 0;
BA_ "GenSigTimeoutTime_GNMM" SG_ 525 VerticalVelocity_GNMM 0;
BA_ "GenSigTimeoutTime_EVCU2" SG_ 525 VerticalVelocity_GNMM 0;
BA_ "GenSigTimeoutTime_ESL" SG_ 525 VerticalVelocity_GNMM 0;
BA_ "GenSigTimeoutTime_ECM" SG_ 525 VerticalVelocity_GNMM 0;
BA_ "GenSigTimeoutTime_DTCM" SG_ 525 VerticalVelocity_GNMM 0;
BA_ "GenSigTimeoutTime_DMSM" SG_ 525 VerticalVelocity_GNMM 0;
BA_ "GenSigTimeoutTime_BSM" SG_ 525 VerticalVelocity_GNMM 0;
BA_ "GenSigTimeoutTime_AGSM" SG_ 525 VerticalVelocity_GNMM 0;
BA_ "GenSigTimeoutTime_ADCAM" SG_ 525 VerticalVelocity_GNMM 0;
BA_ "GenSigStartValue" SG_ 525 VerticalVelocity_GNMM 16383;
BA_ "GenSigTimeoutTime_SGW" SG_ 525 MessageCounter_GLOB_NAV 0;
BA_ "GenSigTimeoutTime_RFHM" SG_ 525 MessageCounter_GLOB_NAV 0;
BA_ "GenSigTimeoutTime_IPC" SG_ 525 MessageCounter_GLOB_NAV 0;
BA_ "GenSigTimeoutTime_GNMM" SG_ 525 MessageCounter_GLOB_NAV 0;
BA_ "GenSigTimeoutTime_EVCU2" SG_ 525 MessageCounter_GLOB_NAV 0;
BA_ "GenSigTimeoutTime_ESL" SG_ 525 MessageCounter_GLOB_NAV 0;
BA_ "GenSigTimeoutTime_ECM" SG_ 525 MessageCounter_GLOB_NAV 0;
BA_ "GenSigTimeoutTime_DTCM" SG_ 525 MessageCounter_GLOB_NAV 0;
BA_ "GenSigTimeoutTime_DMSM" SG_ 525 MessageCounter_GLOB_NAV 0;
BA_ "GenSigTimeoutTime_BSM" SG_ 525 MessageCounter_GLOB_NAV 0;
BA_ "GenSigTimeoutTime_AGSM" SG_ 525 MessageCounter_GLOB_NAV 0;
BA_ "GenSigTimeoutTime_ADCAM" SG_ 525 MessageCounter_GLOB_NAV 0;
BA_ "GenSigTimeoutTime_SGW" SG_ 525 LongitudinalVelocity_GNMM 0;
BA_ "GenSigTimeoutTime_RFHM" SG_ 525 LongitudinalVelocity_GNMM 0;
BA_ "GenSigTimeoutTime_IPC" SG_ 525 LongitudinalVelocity_GNMM 0;
BA_ "GenSigTimeoutTime_GNMM" SG_ 525 LongitudinalVelocity_GNMM 0;
BA_ "GenSigTimeoutTime_EVCU2" SG_ 525 LongitudinalVelocity_GNMM 0;
BA_ "GenSigTimeoutTime_ESL" SG_ 525 LongitudinalVelocity_GNMM 0;
BA_ "GenSigTimeoutTime_ECM" SG_ 525 LongitudinalVelocity_GNMM 0;
BA_ "GenSigTimeoutTime_DTCM" SG_ 525 LongitudinalVelocity_GNMM 0;
BA_ "GenSigTimeoutTime_DMSM" SG_ 525 LongitudinalVelocity_GNMM 0;
BA_ "GenSigTimeoutTime_BSM" SG_ 525 LongitudinalVelocity_GNMM 0;
BA_ "GenSigTimeoutTime_AGSM" SG_ 525 LongitudinalVelocity_GNMM 0;
BA_ "GenSigTimeoutTime_ADCAM" SG_ 525 LongitudinalVelocity_GNMM 0;
BA_ "GenSigStartValue" SG_ 525 LongitudinalVelocity_GNMM 16383;
BA_ "GenSigTimeoutTime_SGW" SG_ 525 LateralVelocity_GNMM 0;
BA_ "GenSigTimeoutTime_RFHM" SG_ 525 LateralVelocity_GNMM 0;
BA_ "GenSigTimeoutTime_IPC" SG_ 525 LateralVelocity_GNMM 0;
BA_ "GenSigTimeoutTime_GNMM" SG_ 525 LateralVelocity_GNMM 0;
BA_ "GenSigTimeoutTime_EVCU2" SG_ 525 LateralVelocity_GNMM 0;
BA_ "GenSigTimeoutTime_ESL" SG_ 525 LateralVelocity_GNMM 0;
BA_ "GenSigTimeoutTime_ECM" SG_ 525 LateralVelocity_GNMM 0;
BA_ "GenSigTimeoutTime_DTCM" SG_ 525 LateralVelocity_GNMM 0;
BA_ "GenSigTimeoutTime_DMSM" SG_ 525 LateralVelocity_GNMM 0;
BA_ "GenSigTimeoutTime_BSM" SG_ 525 LateralVelocity_GNMM 0;
BA_ "GenSigTimeoutTime_AGSM" SG_ 525 LateralVelocity_GNMM 0;
BA_ "GenSigTimeoutTime_ADCAM" SG_ 525 LateralVelocity_GNMM 0;
BA_ "GenSigStartValue" SG_ 525 LateralVelocity_GNMM 16383;
BA_ "GenSigTimeoutTime_SGW" SG_ 525 CRC_GLOB_NAV 0;
BA_ "GenSigTimeoutTime_RFHM" SG_ 525 CRC_GLOB_NAV 0;
BA_ "GenSigTimeoutTime_IPC" SG_ 525 CRC_GLOB_NAV 0;
BA_ "GenSigTimeoutTime_GNMM" SG_ 525 CRC_GLOB_NAV 0;
BA_ "GenSigTimeoutTime_EVCU2" SG_ 525 CRC_GLOB_NAV 0;
BA_ "GenSigTimeoutTime_ESL" SG_ 525 CRC_GLOB_NAV 0;
BA_ "GenSigTimeoutTime_ECM" SG_ 525 CRC_GLOB_NAV 0;
BA_ "GenSigTimeoutTime_DTCM" SG_ 525 CRC_GLOB_NAV 0;
BA_ "GenSigTimeoutTime_DMSM" SG_ 525 CRC_GLOB_NAV 0;
BA_ "GenSigTimeoutTime_BSM" SG_ 525 CRC_GLOB_NAV 0;
BA_ "GenSigTimeoutTime_AGSM" SG_ 525 CRC_GLOB_NAV 0;
BA_ "GenSigTimeoutTime_ADCAM" SG_ 525 CRC_GLOB_NAV 0;
BA_ "GenSigTimeoutTime_SGW" SG_ 525 Long_GNMM 0;
BA_ "GenSigTimeoutTime_RFHM" SG_ 525 Long_GNMM 0;
BA_ "GenSigTimeoutTime_IPC" SG_ 525 Long_GNMM 0;
BA_ "GenSigTimeoutTime_GNMM" SG_ 525 Long_GNMM 0;
BA_ "GenSigTimeoutTime_EVCU2" SG_ 525 Long_GNMM 0;
BA_ "GenSigTimeoutTime_ESL" SG_ 525 Long_GNMM 0;
BA_ "GenSigTimeoutTime_ECM" SG_ 525 Long_GNMM 0;
BA_ "GenSigTimeoutTime_DTCM" SG_ 525 Long_GNMM 0;
BA_ "GenSigTimeoutTime_DMSM" SG_ 525 Long_GNMM 0;
BA_ "GenSigTimeoutTime_BSM" SG_ 525 Long_GNMM 0;
BA_ "GenSigTimeoutTime_AGSM" SG_ 525 Long_GNMM 0;
BA_ "GenSigTimeoutTime_ADCAM" SG_ 525 Long_GNMM 0;
BA_ "GenSigTimeoutTime_SGW" SG_ 525 Lat_GNMM 0;
BA_ "GenSigTimeoutTime_RFHM" SG_ 525 Lat_GNMM 0;
BA_ "GenSigTimeoutTime_IPC" SG_ 525 Lat_GNMM 0;
BA_ "GenSigTimeoutTime_GNMM" SG_ 525 Lat_GNMM 0;
BA_ "GenSigTimeoutTime_EVCU2" SG_ 525 Lat_GNMM 0;
BA_ "GenSigTimeoutTime_ESL" SG_ 525 Lat_GNMM 0;
BA_ "GenSigTimeoutTime_ECM" SG_ 525 Lat_GNMM 0;
BA_ "GenSigTimeoutTime_DTCM" SG_ 525 Lat_GNMM 0;
BA_ "GenSigTimeoutTime_DMSM" SG_ 525 Lat_GNMM 0;
BA_ "GenSigTimeoutTime_BSM" SG_ 525 Lat_GNMM 0;
BA_ "GenSigTimeoutTime_AGSM" SG_ 525 Lat_GNMM 0;
BA_ "GenSigTimeoutTime_ADCAM" SG_ 525 Lat_GNMM 0;
BA_ "GenSigTimeoutTime_SGW" SG_ 525 Longitude_RMSE 0;
BA_ "GenSigTimeoutTime_RFHM" SG_ 525 Longitude_RMSE 0;
BA_ "GenSigTimeoutTime_IPC" SG_ 525 Longitude_RMSE 0;
BA_ "GenSigTimeoutTime_GNMM" SG_ 525 Longitude_RMSE 0;
BA_ "GenSigTimeoutTime_EVCU2" SG_ 525 Longitude_RMSE 0;
BA_ "GenSigTimeoutTime_ESL" SG_ 525 Longitude_RMSE 0;
BA_ "GenSigTimeoutTime_ECM" SG_ 525 Longitude_RMSE 0;
BA_ "GenSigTimeoutTime_DTCM" SG_ 525 Longitude_RMSE 0;
BA_ "GenSigTimeoutTime_DMSM" SG_ 525 Longitude_RMSE 0;
BA_ "GenSigTimeoutTime_BSM" SG_ 525 Longitude_RMSE 0;
BA_ "GenSigTimeoutTime_AGSM" SG_ 525 Longitude_RMSE 0;
BA_ "GenSigTimeoutTime_ADCAM" SG_ 525 Longitude_RMSE 0;
BA_ "GenSigStartValue" SG_ 525 Longitude_RMSE 255;
BA_ "GenSigTimeoutTime_SGW" SG_ 525 Latitude_RMSE 0;
BA_ "GenSigTimeoutTime_RFHM" SG_ 525 Latitude_RMSE 0;
BA_ "GenSigTimeoutTime_IPC" SG_ 525 Latitude_RMSE 0;
BA_ "GenSigTimeoutTime_GNMM" SG_ 525 Latitude_RMSE 0;
BA_ "GenSigTimeoutTime_EVCU2" SG_ 525 Latitude_RMSE 0;
BA_ "GenSigTimeoutTime_ESL" SG_ 525 Latitude_RMSE 0;
BA_ "GenSigTimeoutTime_ECM" SG_ 525 Latitude_RMSE 0;
BA_ "GenSigTimeoutTime_DTCM" SG_ 525 Latitude_RMSE 0;
BA_ "GenSigTimeoutTime_DMSM" SG_ 525 Latitude_RMSE 0;
BA_ "GenSigTimeoutTime_BSM" SG_ 525 Latitude_RMSE 0;
BA_ "GenSigTimeoutTime_AGSM" SG_ 525 Latitude_RMSE 0;
BA_ "GenSigTimeoutTime_ADCAM" SG_ 525 Latitude_RMSE 0;
BA_ "GenSigStartValue" SG_ 525 Latitude_RMSE 255;
BA_ "GenSigTimeoutTime_SGW" SG_ 525 Heading_Angle 0;
BA_ "GenSigTimeoutTime_RFHM" SG_ 525 Heading_Angle 0;
BA_ "GenSigTimeoutTime_IPC" SG_ 525 Heading_Angle 0;
BA_ "GenSigTimeoutTime_GNMM" SG_ 525 Heading_Angle 0;
BA_ "GenSigTimeoutTime_EVCU2" SG_ 525 Heading_Angle 0;
BA_ "GenSigTimeoutTime_ESL" SG_ 525 Heading_Angle 0;
BA_ "GenSigTimeoutTime_ECM" SG_ 525 Heading_Angle 0;
BA_ "GenSigTimeoutTime_DTCM" SG_ 525 Heading_Angle 0;
BA_ "GenSigTimeoutTime_DMSM" SG_ 525 Heading_Angle 0;
BA_ "GenSigTimeoutTime_BSM" SG_ 525 Heading_Angle 0;
BA_ "GenSigTimeoutTime_AGSM" SG_ 525 Heading_Angle 0;
BA_ "GenSigTimeoutTime_ADCAM" SG_ 525 Heading_Angle 0;
BA_ "GenSigStartValue" SG_ 525 Heading_Angle 65535;
BA_ "GenSigTimeoutTime_SGW" SG_ 525 Altitude_RMSE 0;
BA_ "GenSigTimeoutTime_RFHM" SG_ 525 Altitude_RMSE 0;
BA_ "GenSigTimeoutTime_IPC" SG_ 525 Altitude_RMSE 0;
BA_ "GenSigTimeoutTime_GNMM" SG_ 525 Altitude_RMSE 0;
BA_ "GenSigTimeoutTime_EVCU2" SG_ 525 Altitude_RMSE 0;
BA_ "GenSigTimeoutTime_ESL" SG_ 525 Altitude_RMSE 0;
BA_ "GenSigTimeoutTime_ECM" SG_ 525 Altitude_RMSE 0;
BA_ "GenSigTimeoutTime_DTCM" SG_ 525 Altitude_RMSE 0;
BA_ "GenSigTimeoutTime_DMSM" SG_ 525 Altitude_RMSE 0;
BA_ "GenSigTimeoutTime_BSM" SG_ 525 Altitude_RMSE 0;
BA_ "GenSigTimeoutTime_SGW" SG_ 525 LongAcceleration_GNMM 0;
BA_ "GenSigTimeoutTime_RFHM" SG_ 525 LongAcceleration_GNMM 0;
BA_ "GenSigTimeoutTime_IPC" SG_ 525 LongAcceleration_GNMM 0;
BA_ "GenSigTimeoutTime_GNMM" SG_ 525 LongAcceleration_GNMM 0;
BA_ "GenSigTimeoutTime_EVCU2" SG_ 525 LongAcceleration_GNMM 0;
BA_ "GenSigTimeoutTime_ESL" SG_ 525 LongAcceleration_GNMM 0;
BA_ "GenSigTimeoutTime_ECM" SG_ 525 LongAcceleration_GNMM 0;
BA_ "GenSigTimeoutTime_DTCM" SG_ 525 LongAcceleration_GNMM 0;
BA_ "GenSigTimeoutTime_DMSM" SG_ 525 LongAcceleration_GNMM 0;
BA_ "GenSigTimeoutTime_BSM" SG_ 525 LongAcceleration_GNMM 0;
BA_ "GenSigTimeoutTime_AGSM" SG_ 525 LongAcceleration_GNMM 0;
BA_ "GenSigTimeoutTime_ADCAM" SG_ 525 LongAcceleration_GNMM 0;
BA_ "GenSigStartValue" SG_ 525 LongAcceleration_GNMM 4095;
BA_ "GenSigTimeoutTime_SGW" SG_ 525 LatAcceleration_GNMM 0;
BA_ "GenSigTimeoutTime_RFHM" SG_ 525 LatAcceleration_GNMM 0;
BA_ "GenSigTimeoutTime_IPC" SG_ 525 LatAcceleration_GNMM 0;
BA_ "GenSigTimeoutTime_GNMM" SG_ 525 LatAcceleration_GNMM 0;
BA_ "GenSigTimeoutTime_EVCU2" SG_ 525 LatAcceleration_GNMM 0;
BA_ "GenSigTimeoutTime_ESL" SG_ 525 LatAcceleration_GNMM 0;
BA_ "GenSigTimeoutTime_ECM" SG_ 525 LatAcceleration_GNMM 0;
BA_ "GenSigTimeoutTime_DTCM" SG_ 525 LatAcceleration_GNMM 0;
BA_ "GenSigTimeoutTime_DMSM" SG_ 525 LatAcceleration_GNMM 0;
BA_ "GenSigTimeoutTime_BSM" SG_ 525 LatAcceleration_GNMM 0;
BA_ "GenSigTimeoutTime_AGSM" SG_ 525 LatAcceleration_GNMM 0;
BA_ "GenSigTimeoutTime_ADCAM" SG_ 525 LatAcceleration_GNMM 0;
BA_ "GenSigStartValue" SG_ 525 LatAcceleration_GNMM 4095;
BA_ "GenSigTimeoutTime_SGW" SG_ 525 GNMM_Health 0;
BA_ "GenSigTimeoutTime_RFHM" SG_ 525 GNMM_Health 0;
BA_ "GenSigTimeoutTime_IPC" SG_ 525 GNMM_Health 0;
BA_ "GenSigTimeoutTime_GNMM" SG_ 525 GNMM_Health 0;
BA_ "GenSigTimeoutTime_EVCU2" SG_ 525 GNMM_Health 0;
BA_ "GenSigTimeoutTime_ESL" SG_ 525 GNMM_Health 0;
BA_ "GenSigTimeoutTime_ECM" SG_ 525 GNMM_Health 0;
BA_ "GenSigTimeoutTime_DTCM" SG_ 525 GNMM_Health 0;
BA_ "GenSigTimeoutTime_DMSM" SG_ 525 GNMM_Health 0;
BA_ "GenSigTimeoutTime_BSM" SG_ 525 GNMM_Health 0;
BA_ "GenSigTimeoutTime_AGSM" SG_ 525 GNMM_Health 0;
BA_ "GenSigTimeoutTime_ADCAM" SG_ 525 GNMM_Health 0;
BA_ "GenSigTimeoutTime_ESL" SG_ 525 NumOfSatellites 0;
BA_ "GenSigTimeoutTime_ECM" SG_ 525 NumOfSatellites 0;
BA_ "GenSigTimeoutTime_DTCM" SG_ 525 NumOfSatellites 0;
BA_ "GenSigTimeoutTime_DMSM" SG_ 525 NumOfSatellites 0;
BA_ "GenSigTimeoutTime_BSM" SG_ 525 NumOfSatellites 0;
BA_ "GenSigTimeoutTime_BCM" SG_ 525 NumOfSatellites 0;
BA_ "GenSigTimeoutTime_AGSM" SG_ 525 NumOfSatellites 0;
BA_ "GenSigTimeoutTime_ADCAM" SG_ 525 NumOfSatellites 0;
BA_ "GenSigTimeoutTime_SGW" SG_ 525 MAC_GLOB_NAV 0;
BA_ "GenSigTimeoutTime_RFHM" SG_ 525 MAC_GLOB_NAV 0;
BA_ "GenSigTimeoutTime_IPC" SG_ 525 MAC_GLOB_NAV 0;
BA_ "GenSigTimeoutTime_GNMM" SG_ 525 MAC_GLOB_NAV 0;
BA_ "GenSigTimeoutTime_EVCU2" SG_ 525 MAC_GLOB_NAV 0;
BA_ "GenSigTimeoutTime_ESL" SG_ 525 MAC_GLOB_NAV 0;
BA_ "GenSigTimeoutTime_ECM" SG_ 525 MAC_GLOB_NAV 0;
BA_ "GenSigTimeoutTime_DTCM" SG_ 525 MAC_GLOB_NAV 0;
BA_ "GenSigTimeoutTime_DMSM" SG_ 525 MAC_GLOB_NAV 0;
BA_ "GenSigTimeoutTime_BSM" SG_ 525 MAC_GLOB_NAV 0;
BA_ "GenSigTimeoutTime_AGSM" SG_ 525 MAC_GLOB_NAV 0;
BA_ "GenSigTimeoutTime_ADCAM" SG_ 525 MAC_GLOB_NAV 0;
BA_ "GenSigTimeoutTime_SGW" SG_ 525 IMUTemperature 0;
BA_ "GenSigTimeoutTime_RFHM" SG_ 525 IMUTemperature 0;
BA_ "GenSigTimeoutTime_IPC" SG_ 525 IMUTemperature 0;
BA_ "GenSigTimeoutTime_GNMM" SG_ 525 IMUTemperature 0;
BA_ "GenSigTimeoutTime_EVCU2" SG_ 525 IMUTemperature 0;
BA_ "GenSigTimeoutTime_ESL" SG_ 525 IMUTemperature 0;
BA_ "GenSigTimeoutTime_ECM" SG_ 525 IMUTemperature 0;
BA_ "GenSigTimeoutTime_DTCM" SG_ 525 IMUTemperature 0;
BA_ "GenSigTimeoutTime_DMSM" SG_ 525 IMUTemperature 0;
BA_ "GenSigTimeoutTime_BSM" SG_ 525 IMUTemperature 0;
BA_ "GenSigTimeoutTime_BCM" SG_ 525 IMUTemperature 0;
BA_ "GenSigTimeoutTime_AGSM" SG_ 525 IMUTemperature 0;
BA_ "GenSigTimeoutTime_ADCAM" SG_ 525 IMUTemperature 0;
BA_ "GenSigStartValue" SG_ 525 IMUTemperature 40;
BA_ "GenSigTimeoutTime_SGW" SG_ 525 HDOP 0;
BA_ "GenSigTimeoutTime_RFHM" SG_ 525 HDOP 0;
BA_ "GenSigTimeoutTime_IPC" SG_ 525 HDOP 0;
BA_ "GenSigTimeoutTime_GNMM" SG_ 525 HDOP 0;
BA_ "GenSigTimeoutTime_EVCU2" SG_ 525 HDOP 0;
BA_ "GenSigTimeoutTime_ESL" SG_ 525 HDOP 0;
BA_ "GenSigTimeoutTime_ECM" SG_ 525 HDOP 0;
BA_ "GenSigTimeoutTime_DTCM" SG_ 525 HDOP 0;
BA_ "GenSigTimeoutTime_DMSM" SG_ 525 HDOP 0;
BA_ "GenSigTimeoutTime_BSM" SG_ 525 HDOP 0;
BA_ "GenSigTimeoutTime_BCM" SG_ 525 HDOP 0;
BA_ "GenSigTimeoutTime_AGSM" SG_ 525 HDOP 0;
BA_ "GenSigTimeoutTime_ADCAM" SG_ 525 HDOP 0;
BA_ "GenSigTimeoutTime_SGW" SG_ 525 FixedStatusReceiver 0;
BA_ "GenSigTimeoutTime_RFHM" SG_ 525 FixedStatusReceiver 0;
BA_ "GenSigTimeoutTime_IPC" SG_ 525 FixedStatusReceiver 0;
BA_ "GenSigTimeoutTime_GNMM" SG_ 525 FixedStatusReceiver 0;
BA_ "GenSigTimeoutTime_EVCU2" SG_ 525 FixedStatusReceiver 0;
BA_ "GenSigTimeoutTime_ESL" SG_ 525 FixedStatusReceiver 0;
BA_ "GenSigTimeoutTime_ECM" SG_ 525 FixedStatusReceiver 0;
BA_ "GenSigTimeoutTime_DTCM" SG_ 525 FixedStatusReceiver 0;
BA_ "GenSigTimeoutTime_DMSM" SG_ 525 FixedStatusReceiver 0;
BA_ "GenSigTimeoutTime_BSM" SG_ 525 FixedStatusReceiver 0;
BA_ "GenSigTimeoutTime_BCM" SG_ 525 FixedStatusReceiver 0;
BA_ "GenSigTimeoutTime_AGSM" SG_ 525 FixedStatusReceiver 0;
BA_ "GenSigTimeoutTime_ADCAM" SG_ 525 FixedStatusReceiver 0;
BA_ "GenSigTimeoutTime_IPC" SG_ 525 CourseAngle 0;
BA_ "GenSigTimeoutTime_GNMM" SG_ 525 CourseAngle 0;
BA_ "GenSigTimeoutTime_EVCU2" SG_ 525 CourseAngle 0;
BA_ "GenSigTimeoutTime_ESL" SG_ 525 CourseAngle 0;
BA_ "GenSigTimeoutTime_ECM" SG_ 525 CourseAngle 0;
BA_ "GenSigTimeoutTime_DTCM" SG_ 525 CourseAngle 0;
BA_ "GenSigTimeoutTime_DMSM" SG_ 525 CourseAngle 0;
BA_ "GenSigTimeoutTime_BSM" SG_ 525 CourseAngle 0;
BA_ "GenSigTimeoutTime_BCM" SG_ 525 CourseAngle 0;
BA_ "GenSigTimeoutTime_AGSM" SG_ 525 CourseAngle 0;
BA_ "GenSigTimeoutTime_ADCAM" SG_ 525 CourseAngle 0;
BA_ "GenSigTimeoutTime_SGW" SG_ 525 CourseAngle 0;
BA_ "GenSigTimeoutTime_RFHM" SG_ 525 CourseAngle 0;
BA_ "GenSigTimeoutTime_SGW" SG_ 525 Cntr_GLOB_NAV 0;
BA_ "GenSigTimeoutTime_RFHM" SG_ 525 Cntr_GLOB_NAV 0;
BA_ "GenSigTimeoutTime_IPC" SG_ 525 Cntr_GLOB_NAV 0;
BA_ "GenSigTimeoutTime_GNMM" SG_ 525 Cntr_GLOB_NAV 0;
BA_ "GenSigTimeoutTime_EVCU2" SG_ 525 Cntr_GLOB_NAV 0;
BA_ "GenSigTimeoutTime_ESL" SG_ 525 Cntr_GLOB_NAV 0;
BA_ "GenSigTimeoutTime_ECM" SG_ 525 Cntr_GLOB_NAV 0;
BA_ "GenSigTimeoutTime_DTCM" SG_ 525 Cntr_GLOB_NAV 0;
BA_ "GenSigTimeoutTime_DMSM" SG_ 525 Cntr_GLOB_NAV 0;
BA_ "GenSigTimeoutTime_BSM" SG_ 525 Cntr_GLOB_NAV 0;
BA_ "GenSigTimeoutTime_AGSM" SG_ 525 Cntr_GLOB_NAV 0;
BA_ "GenSigTimeoutTime_ADCAM" SG_ 525 Cntr_GLOB_NAV 0;
BA_ "GenSigTimeoutTime_AGSM" SG_ 525 Altitude_RMSE 0;
BA_ "GenSigTimeoutTime_ADCAM" SG_ 525 Altitude_RMSE 0;
BA_ "GenSigStartValue" SG_ 525 Altitude_RMSE 255;
BA_ "GenSigTimeoutTime_SGW" SG_ 1470 CRC_BCM29 0;
BA_ "GenSigTimeoutTime_RFHM" SG_ 1470 CRC_BCM29 0;
BA_ "GenSigTimeoutTime_IPC" SG_ 1470 CRC_BCM29 0;
BA_ "GenSigTimeoutTime_GNMM" SG_ 1470 CRC_BCM29 0;
BA_ "GenSigTimeoutTime_EVCU2" SG_ 1470 CRC_BCM29 0;
BA_ "GenSigTimeoutTime_ESL" SG_ 1470 CRC_BCM29 0;
BA_ "GenSigTimeoutTime_ECM" SG_ 1470 CRC_BCM29 0;
BA_ "GenSigTimeoutTime_DTCM" SG_ 1470 CRC_BCM29 0;
BA_ "GenSigTimeoutTime_DMSM" SG_ 1470 CRC_BCM29 0;
BA_ "GenSigTimeoutTime_BSM" SG_ 1470 CRC_BCM29 0;
BA_ "GenSigTimeoutTime_BCM" SG_ 1470 CRC_BCM29 0;
BA_ "GenSigTimeoutTime_AGSM" SG_ 1470 CRC_BCM29 0;
BA_ "GenSigTimeoutTime_ADCAM" SG_ 1470 CRC_BCM29 0;
BA_ "GenSigTimeoutTime_SGW" SG_ 1470 DriverReclineRelativePosition 0;
BA_ "GenSigTimeoutTime_RFHM" SG_ 1470 DriverReclineRelativePosition 0;
BA_ "GenSigTimeoutTime_IPC" SG_ 1470 DriverReclineRelativePosition 0;
BA_ "GenSigTimeoutTime_GNMM" SG_ 1470 DriverReclineRelativePosition 0;
BA_ "GenSigTimeoutTime_EVCU2" SG_ 1470 DriverReclineRelativePosition 0;
BA_ "GenSigTimeoutTime_ESL" SG_ 1470 DriverReclineRelativePosition 0;
BA_ "GenSigTimeoutTime_ECM" SG_ 1470 DriverReclineRelativePosition 0;
BA_ "GenSigTimeoutTime_DTCM" SG_ 1470 DriverReclineRelativePosition 0;
BA_ "GenSigTimeoutTime_DMSM" SG_ 1470 DriverReclineRelativePosition 0;
BA_ "GenSigTimeoutTime_BSM" SG_ 1470 DriverReclineRelativePosition 0;
BA_ "GenSigTimeoutTime_BCM" SG_ 1470 DriverReclineRelativePosition 0;
BA_ "GenSigTimeoutTime_AGSM" SG_ 1470 DriverReclineRelativePosition 0;
BA_ "GenSigTimeoutTime_ADCAM" SG_ 1470 DriverReclineRelativePosition 0;
BA_ "GenSigSendType" SG_ 1470 DriverReclineRelativePosition 3;
BA_ "GenSigTimeoutTime_AGSM" SG_ 1470 DriverSeatHorizontalButton 0;
BA_ "GenSigTimeoutTime_ADCAM" SG_ 1470 DriverSeatHorizontalButton 0;
BA_ "GenSigSendType" SG_ 1470 DriverSeatHorizontalButton 3;
BA_ "GenSigTimeoutTime_SGW" SG_ 281 MRM_STATUS_C2 0;
BA_ "GenSigTimeoutTime_RFHM" SG_ 281 MRM_STATUS_C2 0;
BA_ "GenSigTimeoutTime_MPAD" SG_ 281 MRM_STATUS_C2 0;
BA_ "GenSigTimeoutTime_GNMM" SG_ 281 MRM_STATUS_C2 0;
BA_ "GenSigTimeoutTime_ESL" SG_ 281 MRM_STATUS_C2 0;
BA_ "GenSigTimeoutTime_ECM" SG_ 281 MRM_STATUS_C2 0;
BA_ "GenSigTimeoutTime_DTCM" SG_ 281 MRM_STATUS_C2 0;
BA_ "GenSigTimeoutTime_DMSM" SG_ 281 MRM_STATUS_C2 0;
BA_ "GenSigTimeoutTime_BSM" SG_ 281 MRM_STATUS_C2 0;
BA_ "GenSigTimeoutTime_BCM" SG_ 281 MRM_STATUS_C2 0;
BA_ "GenSigTimeoutTime_AGSM" SG_ 281 MRM_STATUS_C2 0;
BA_ "GenSigTimeoutTime_ADCAM" SG_ 281 MRM_STATUS_C2 0;
BA_ "GenSigTimeoutTime_SGW" SG_ 281 MessageCounter_ADAS_INFO_C2 0;
BA_ "GenSigTimeoutTime_RFHM" SG_ 281 MessageCounter_ADAS_INFO_C2 0;
BA_ "GenSigTimeoutTime_MPAD" SG_ 281 MessageCounter_ADAS_INFO_C2 0;
BA_ "GenSigTimeoutTime_GNMM" SG_ 281 MessageCounter_ADAS_INFO_C2 0;
BA_ "GenSigTimeoutTime_EVCU2" SG_ 281 MessageCounter_ADAS_INFO_C2 0;
BA_ "GenSigTimeoutTime_ESL" SG_ 281 MessageCounter_ADAS_INFO_C2 0;
BA_ "GenSigTimeoutTime_ECM" SG_ 281 MessageCounter_ADAS_INFO_C2 0;
BA_ "GenSigTimeoutTime_DTCM" SG_ 281 MessageCounter_ADAS_INFO_C2 0;
BA_ "GenSigTimeoutTime_DMSM" SG_ 281 MessageCounter_ADAS_INFO_C2 0;
BA_ "GenSigTimeoutTime_BCM" SG_ 281 MessageCounter_ADAS_INFO_C2 0;
BA_ "GenSigTimeoutTime_AGSM" SG_ 281 MessageCounter_ADAS_INFO_C2 0;
BA_ "GenSigTimeoutTime_ADCAM" SG_ 281 MessageCounter_ADAS_INFO_C2 0;
BA_ "GenSigTimeoutTime_SGW" SG_ 281 CRC_ADAS_INFO_C2 0;
BA_ "GenSigTimeoutTime_RFHM" SG_ 281 CRC_ADAS_INFO_C2 0;
BA_ "GenSigTimeoutTime_MPAD" SG_ 281 CRC_ADAS_INFO_C2 0;
BA_ "GenSigTimeoutTime_GNMM" SG_ 281 CRC_ADAS_INFO_C2 0;
BA_ "GenSigTimeoutTime_EVCU2" SG_ 281 CRC_ADAS_INFO_C2 0;
BA_ "GenSigTimeoutTime_ESL" SG_ 281 CRC_ADAS_INFO_C2 0;
BA_ "GenSigTimeoutTime_SGW" SG_ 728 Obj04_HorDist 0;
BA_ "GenSigTimeoutTime_RFHM" SG_ 728 Obj04_HorDist 0;
BA_ "GenSigTimeoutTime_MPAD" SG_ 728 Obj04_HorDist 0;
BA_ "GenSigTimeoutTime_IPC" SG_ 728 Obj04_HorDist 0;
BA_ "GenSigTimeoutTime_GNMM" SG_ 728 Obj04_HorDist 0;
BA_ "GenSigTimeoutTime_EVCU2" SG_ 728 Obj04_HorDist 0;
BA_ "GenSigTimeoutTime_ESL" SG_ 728 Obj04_HorDist 0;
BA_ "GenSigTimeoutTime_ECM" SG_ 728 Obj04_HorDist 0;
BA_ "GenSigTimeoutTime_DTCM" SG_ 728 Obj04_HorDist 0;
BA_ "GenSigTimeoutTime_DMSM" SG_ 728 Obj04_HorDist 0;
BA_ "GenSigTimeoutTime_BSM" SG_ 728 Obj04_HorDist 0;
BA_ "GenSigTimeoutTime_AGSM" SG_ 728 Obj04_HorDist 0;
BA_ "GenSigTimeoutTime_ADCAM" SG_ 728 Obj04_HorDist 0;
BA_ "GenSigStartValue" SG_ 728 Obj04_HorDist 254;
BA_ "GenSigTimeoutTime_SGW" SG_ 728 Obj03_Type 0;
BA_ "GenSigTimeoutTime_RFHM" SG_ 728 Obj03_Type 0;
BA_ "GenSigTimeoutTime_MPAD" SG_ 728 Obj03_Type 0;
BA_ "GenSigTimeoutTime_IPC" SG_ 728 Obj03_Type 0;
BA_ "GenSigTimeoutTime_GNMM" SG_ 728 Obj03_Type 0;
BA_ "GenSigTimeoutTime_EVCU2" SG_ 728 Obj03_Type 0;
BA_ "GenSigTimeoutTime_ESL" SG_ 728 Obj03_Type 0;
BA_ "GenSigTimeoutTime_ECM" SG_ 728 Obj03_Type 0;
BA_ "GenSigTimeoutTime_DTCM" SG_ 728 Obj03_Type 0;
BA_ "GenSigTimeoutTime_DMSM" SG_ 728 Obj03_Type 0;
BA_ "GenSigTimeoutTime_BSM" SG_ 728 Obj03_Type 0;
BA_ "GenSigTimeoutTime_AGSM" SG_ 728 Obj03_Type 0;
BA_ "GenSigTimeoutTime_ADCAM" SG_ 728 Obj03_Type 0;
BA_ "GenSigStartValue" SG_ 728 Obj03_Type 14;
BA_ "GenSigTimeoutTime_SGW" SG_ 728 Obj03_HorDist 0;
BA_ "GenSigTimeoutTime_RFHM" SG_ 728 Obj03_HorDist 0;
BA_ "GenSigTimeoutTime_MPAD" SG_ 728 Obj03_HorDist 0;
BA_ "GenSigTimeoutTime_IPC" SG_ 728 Obj03_HorDist 0;
BA_ "GenSigTimeoutTime_GNMM" SG_ 728 Obj03_HorDist 0;
BA_ "GenSigTimeoutTime_EVCU2" SG_ 728 Obj03_HorDist 0;
BA_ "GenSigTimeoutTime_ESL" SG_ 728 Obj03_HorDist 0;
BA_ "GenSigTimeoutTime_ECM" SG_ 728 Obj03_HorDist 0;
BA_ "GenSigTimeoutTime_DTCM" SG_ 728 Obj03_HorDist 0;
BA_ "GenSigTimeoutTime_DMSM" SG_ 728 Obj03_HorDist 0;
BA_ "GenSigTimeoutTime_BSM" SG_ 728 Obj03_HorDist 0;
BA_ "GenSigTimeoutTime_AGSM" SG_ 728 Obj03_HorDist 0;
BA_ "GenSigTimeoutTime_ADCAM" SG_ 728 Obj03_HorDist 0;
BA_ "GenSigStartValue" SG_ 728 Obj03_HorDist 254;
BA_ "GenSigTimeoutTime_SGW" SG_ 728 Obj02_Type 0;
BA_ "GenSigTimeoutTime_RFHM" SG_ 728 Obj02_Type 0;
BA_ "GenSigTimeoutTime_MPAD" SG_ 728 Obj02_Type 0;
BA_ "GenSigTimeoutTime_IPC" SG_ 728 Obj02_Type 0;
BA_ "GenSigTimeoutTime_GNMM" SG_ 728 Obj02_Type 0;
BA_ "GenSigTimeoutTime_EVCU2" SG_ 728 Obj02_Type 0;
BA_ "GenSigTimeoutTime_ESL" SG_ 728 Obj02_Type 0;
BA_ "GenSigTimeoutTime_ECM" SG_ 728 Obj02_Type 0;
BA_ "GenSigTimeoutTime_DTCM" SG_ 728 Obj02_Type 0;
BA_ "GenSigTimeoutTime_DMSM" SG_ 728 Obj02_Type 0;
BA_ "GenSigTimeoutTime_BSM" SG_ 728 Obj02_Type 0;
BA_ "GenSigTimeoutTime_AGSM" SG_ 728 Obj02_Type 0;
BA_ "GenSigTimeoutTime_ADCAM" SG_ 728 Obj02_Type 0;
BA_ "GenSigStartValue" SG_ 728 Obj02_Type 14;
BA_ "GenSigTimeoutTime_SGW" SG_ 728 Obj02_HorDist 0;
BA_ "GenSigTimeoutTime_RFHM" SG_ 728 Obj02_HorDist 0;
BA_ "GenSigTimeoutTime_MPAD" SG_ 728 Obj02_HorDist 0;
BA_ "GenSigTimeoutTime_IPC" SG_ 728 Obj02_HorDist 0;
BA_ "GenSigTimeoutTime_GNMM" SG_ 728 Obj02_HorDist 0;
BA_ "GenSigTimeoutTime_EVCU2" SG_ 728 Obj02_HorDist 0;
BA_ "GenSigTimeoutTime_ESL" SG_ 728 Obj02_HorDist 0;
BA_ "GenSigTimeoutTime_ECM" SG_ 728 Obj02_HorDist 0;
BA_ "GenSigTimeoutTime_DTCM" SG_ 728 Obj02_HorDist 0;
BA_ "GenSigTimeoutTime_DMSM" SG_ 728 Obj02_HorDist 0;
BA_ "GenSigTimeoutTime_BSM" SG_ 728 Obj02_HorDist 0;
BA_ "GenSigTimeoutTime_AGSM" SG_ 728 Obj02_HorDist 0;
BA_ "GenSigTimeoutTime_ADCAM" SG_ 728 Obj02_HorDist 0;
BA_ "GenSigStartValue" SG_ 728 Obj02_HorDist 254;
BA_ "GenSigTimeoutTime_SGW" SG_ 728 Obj01_Type 0;
BA_ "GenSigTimeoutTime_RFHM" SG_ 728 Obj01_Type 0;
BA_ "GenSigTimeoutTime_MPAD" SG_ 728 Obj01_Type 0;
BA_ "GenSigTimeoutTime_IPC" SG_ 728 Obj01_Type 0;
BA_ "GenSigTimeoutTime_GNMM" SG_ 728 Obj01_Type 0;
BA_ "GenSigTimeoutTime_EVCU2" SG_ 728 Obj01_Type 0;
BA_ "GenSigTimeoutTime_ESL" SG_ 728 Obj01_Type 0;
BA_ "GenSigTimeoutTime_ECM" SG_ 728 Obj01_Type 0;
BA_ "GenSigTimeoutTime_DTCM" SG_ 728 Obj01_Type 0;
BA_ "GenSigTimeoutTime_DMSM" SG_ 728 Obj01_Type 0;
BA_ "GenSigTimeoutTime_BSM" SG_ 728 Obj01_Type 0;
BA_ "GenSigTimeoutTime_AGSM" SG_ 728 Obj01_Type 0;
BA_ "GenSigTimeoutTime_ADCAM" SG_ 728 Obj01_Type 0;
BA_ "GenSigStartValue" SG_ 728 Obj01_Type 14;
BA_ "GenSigTimeoutTime_SGW" SG_ 728 Obj03_VerPos 0;
BA_ "GenSigTimeoutTime_RFHM" SG_ 728 Obj03_VerPos 0;
BA_ "GenSigTimeoutTime_MPAD" SG_ 728 Obj03_VerPos 0;
BA_ "GenSigTimeoutTime_IPC" SG_ 728 Obj03_VerPos 0;
BA_ "GenSigTimeoutTime_GNMM" SG_ 728 Obj03_VerPos 0;
BA_ "GenSigTimeoutTime_EVCU2" SG_ 728 Obj03_VerPos 0;
BA_ "GenSigTimeoutTime_ESL" SG_ 728 Obj03_VerPos 0;
BA_ "GenSigTimeoutTime_ECM" SG_ 728 Obj03_VerPos 0;
BA_ "GenSigTimeoutTime_DTCM" SG_ 728 Obj03_VerPos 0;
BA_ "GenSigTimeoutTime_DMSM" SG_ 728 Obj03_VerPos 0;
BA_ "GenSigTimeoutTime_BSM" SG_ 728 Obj03_VerPos 0;
BA_ "GenSigTimeoutTime_AGSM" SG_ 728 Obj03_VerPos 0;
BA_ "GenSigTimeoutTime_ADCAM" SG_ 728 Obj03_VerPos 0;
BA_ "GenSigStartValue" SG_ 728 Obj03_VerPos 251;
BA_ "GenSigTimeoutTime_SGW" SG_ 728 Obj03_ID 0;
BA_ "GenSigTimeoutTime_RFHM" SG_ 728 Obj03_ID 0;
BA_ "GenSigTimeoutTime_MPAD" SG_ 728 Obj03_ID 0;
BA_ "GenSigTimeoutTime_IPC" SG_ 728 Obj03_ID 0;
BA_ "GenSigTimeoutTime_GNMM" SG_ 728 Obj03_ID 0;
BA_ "GenSigTimeoutTime_EVCU2" SG_ 728 Obj03_ID 0;
BA_ "GenSigTimeoutTime_ESL" SG_ 728 Obj03_ID 0;
BA_ "GenSigTimeoutTime_ECM" SG_ 728 Obj03_ID 0;
BA_ "GenSigTimeoutTime_DTCM" SG_ 728 Obj03_ID 0;
BA_ "GenSigTimeoutTime_DMSM" SG_ 728 Obj03_ID 0;
BA_ "GenSigTimeoutTime_BSM" SG_ 728 Obj03_ID 0;
BA_ "GenSigTimeoutTime_AGSM" SG_ 728 Obj03_ID 0;
BA_ "GenSigTimeoutTime_ADCAM" SG_ 728 Obj03_ID 0;
BA_ "GenSigStartValue" SG_ 728 Obj03_ID 254;
BA_ "GenSigTimeoutTime_SGW" SG_ 728 Obj03_HorSpeed 0;
BA_ "GenSigTimeoutTime_RFHM" SG_ 728 Obj03_HorSpeed 0;
BA_ "GenSigTimeoutTime_MPAD" SG_ 728 Obj03_HorSpeed 0;
BA_ "GenSigTimeoutTime_IPC" SG_ 728 Obj03_HorSpeed 0;
BA_ "GenSigTimeoutTime_GNMM" SG_ 728 Obj03_HorSpeed 0;
BA_ "GenSigTimeoutTime_EVCU2" SG_ 728 Obj03_HorSpeed 0;
BA_ "GenSigTimeoutTime_ESL" SG_ 728 Obj03_HorSpeed 0;
BA_ "GenSigTimeoutTime_ECM" SG_ 728 Obj03_HorSpeed 0;
BA_ "GenSigTimeoutTime_DTCM" SG_ 728 Obj03_HorSpeed 0;
BA_ "GenSigTimeoutTime_DMSM" SG_ 728 Obj03_HorSpeed 0;
BA_ "GenSigTimeoutTime_BSM" SG_ 728 Obj03_HorSpeed 0;
BA_ "GenSigTimeoutTime_AGSM" SG_ 728 Obj03_HorSpeed 0;
BA_ "GenSigTimeoutTime_ADCAM" SG_ 728 Obj03_HorSpeed 0;
BA_ "GenSigStartValue" SG_ 728 Obj03_HorSpeed 4092;
BA_ "GenSigTimeoutTime_SGW" SG_ 728 Obj03_HorPosRight 0;
BA_ "GenSigTimeoutTime_RFHM" SG_ 728 Obj03_HorPosRight 0;
BA_ "GenSigTimeoutTime_MPAD" SG_ 728 Obj03_HorPosRight 0;
BA_ "GenSigTimeoutTime_IPC" SG_ 728 Obj03_HorPosRight 0;
BA_ "GenSigTimeoutTime_GNMM" SG_ 728 Obj03_HorPosRight 0;
BA_ "GenSigTimeoutTime_EVCU2" SG_ 728 Obj03_HorPosRight 0;
BA_ "GenSigTimeoutTime_ESL" SG_ 728 Obj03_HorPosRight 0;
BA_ "GenSigTimeoutTime_ECM" SG_ 728 Obj03_HorPosRight 0;
BA_ "GenSigTimeoutTime_DTCM" SG_ 728 Obj03_HorPosRight 0;
BA_ "GenSigTimeoutTime_DMSM" SG_ 728 Obj03_HorPosRight 0;
BA_ "GenSigTimeoutTime_BSM" SG_ 728 Obj03_HorPosRight 0;
BA_ "GenSigTimeoutTime_AGSM" SG_ 728 Obj03_HorPosRight 0;
BA_ "GenSigTimeoutTime_ADCAM" SG_ 728 Obj03_HorPosRight 0;
BA_ "GenSigStartValue" SG_ 728 Obj03_HorPosRight 4092;
BA_ "GenSigTimeoutTime_SGW" SG_ 728 Obj03_HorPosLeft 0;
BA_ "GenSigTimeoutTime_RFHM" SG_ 728 Obj03_HorPosLeft 0;
BA_ "GenSigTimeoutTime_MPAD" SG_ 728 Obj03_HorPosLeft 0;
BA_ "GenSigTimeoutTime_IPC" SG_ 728 Obj03_HorPosLeft 0;
BA_ "GenSigTimeoutTime_GNMM" SG_ 728 Obj03_HorPosLeft 0;
BA_ "GenSigTimeoutTime_EVCU2" SG_ 728 Obj03_HorPosLeft 0;
BA_ "GenSigTimeoutTime_ESL" SG_ 728 Obj03_HorPosLeft 0;
BA_ "GenSigTimeoutTime_ECM" SG_ 728 Obj03_HorPosLeft 0;
BA_ "GenSigTimeoutTime_DTCM" SG_ 728 Obj03_HorPosLeft 0;
BA_ "GenSigTimeoutTime_DMSM" SG_ 728 Obj03_HorPosLeft 0;
BA_ "GenSigTimeoutTime_BSM" SG_ 728 Obj03_HorPosLeft 0;
BA_ "GenSigTimeoutTime_AGSM" SG_ 728 Obj03_HorPosLeft 0;
BA_ "GenSigTimeoutTime_ADCAM" SG_ 728 Obj03_HorPosLeft 0;
BA_ "GenSigStartValue" SG_ 728 Obj03_HorPosLeft 4092;
BA_ "GenSigTimeoutTime_SGW" SG_ 728 Obj02_VerPos 0;
BA_ "GenSigTimeoutTime_RFHM" SG_ 728 Obj02_VerPos 0;
BA_ "GenSigTimeoutTime_MPAD" SG_ 728 Obj02_VerPos 0;
BA_ "GenSigTimeoutTime_IPC" SG_ 728 Obj02_VerPos 0;
BA_ "GenSigTimeoutTime_GNMM" SG_ 728 Obj02_VerPos 0;
BA_ "GenSigTimeoutTime_EVCU2" SG_ 728 Obj02_VerPos 0;
BA_ "GenSigTimeoutTime_ESL" SG_ 728 Obj02_VerPos 0;
BA_ "GenSigTimeoutTime_ECM" SG_ 728 Obj02_VerPos 0;
BA_ "GenSigTimeoutTime_DTCM" SG_ 728 Obj02_VerPos 0;
BA_ "GenSigTimeoutTime_DMSM" SG_ 728 Obj02_VerPos 0;
BA_ "GenSigTimeoutTime_BSM" SG_ 728 Obj02_VerPos 0;
BA_ "GenSigTimeoutTime_AGSM" SG_ 728 Obj02_VerPos 0;
BA_ "GenSigTimeoutTime_ADCAM" SG_ 728 Obj02_VerPos 0;
BA_ "GenSigStartValue" SG_ 728 Obj02_VerPos 251;
BA_ "GenSigTimeoutTime_SGW" SG_ 728 Obj02_ID 0;
BA_ "GenSigTimeoutTime_RFHM" SG_ 728 Obj02_ID 0;
BA_ "GenSigTimeoutTime_MPAD" SG_ 728 Obj02_ID 0;
BA_ "GenSigTimeoutTime_IPC" SG_ 728 Obj02_ID 0;
BA_ "GenSigTimeoutTime_GNMM" SG_ 728 Obj02_ID 0;
BA_ "GenSigTimeoutTime_EVCU2" SG_ 728 Obj02_ID 0;
BA_ "GenSigTimeoutTime_ESL" SG_ 728 Obj02_ID 0;
BA_ "GenSigTimeoutTime_ECM" SG_ 728 Obj02_ID 0;
BA_ "GenSigTimeoutTime_DTCM" SG_ 728 Obj02_ID 0;
BA_ "GenSigTimeoutTime_DMSM" SG_ 728 Obj02_ID 0;
BA_ "GenSigTimeoutTime_BSM" SG_ 728 Obj02_ID 0;
BA_ "GenSigTimeoutTime_AGSM" SG_ 728 Obj02_ID 0;
BA_ "GenSigTimeoutTime_ADCAM" SG_ 728 Obj02_ID 0;
BA_ "GenSigStartValue" SG_ 728 Obj02_ID 254;
BA_ "GenSigTimeoutTime_SGW" SG_ 728 Obj02_HorSpeed 0;
BA_ "GenSigTimeoutTime_RFHM" SG_ 728 Obj02_HorSpeed 0;
BA_ "GenSigTimeoutTime_MPAD" SG_ 728 Obj02_HorSpeed 0;
BA_ "GenSigTimeoutTime_IPC" SG_ 728 Obj02_HorSpeed 0;
BA_ "GenSigTimeoutTime_GNMM" SG_ 728 Obj02_HorSpeed 0;
BA_ "GenSigTimeoutTime_EVCU2" SG_ 728 Obj02_HorSpeed 0;
BA_ "GenSigTimeoutTime_ESL" SG_ 728 Obj02_HorSpeed 0;
BA_ "GenSigTimeoutTime_ECM" SG_ 728 Obj02_HorSpeed 0;
BA_ "GenSigTimeoutTime_DTCM" SG_ 728 Obj02_HorSpeed 0;
BA_ "GenSigTimeoutTime_DMSM" SG_ 728 Obj02_HorSpeed 0;
BA_ "GenSigTimeoutTime_BSM" SG_ 728 Obj02_HorSpeed 0;
BA_ "GenSigTimeoutTime_AGSM" SG_ 728 Obj02_HorSpeed 0;
BA_ "GenSigTimeoutTime_ADCAM" SG_ 728 Obj02_HorSpeed 0;
BA_ "GenSigStartValue" SG_ 728 Obj02_HorSpeed 4092;
BA_ "GenSigTimeoutTime_SGW" SG_ 728 Obj02_HorPosRight 0;
BA_ "GenSigTimeoutTime_RFHM" SG_ 728 Obj02_HorPosRight 0;
BA_ "GenSigTimeoutTime_MPAD" SG_ 728 Obj02_HorPosRight 0;
BA_ "GenSigTimeoutTime_IPC" SG_ 728 Obj02_HorPosRight 0;
BA_ "GenSigTimeoutTime_GNMM" SG_ 728 Obj02_HorPosRight 0;
BA_ "GenSigTimeoutTime_EVCU2" SG_ 728 Obj02_HorPosRight 0;
BA_ "GenSigTimeoutTime_ESL" SG_ 728 Obj02_HorPosRight 0;
BA_ "GenSigTimeoutTime_ECM" SG_ 728 Obj02_HorPosRight 0;
BA_ "GenSigTimeoutTime_DTCM" SG_ 728 Obj02_HorPosRight 0;
BA_ "GenSigTimeoutTime_DMSM" SG_ 728 Obj02_HorPosRight 0;
BA_ "GenSigTimeoutTime_BSM" SG_ 728 Obj02_HorPosRight 0;
BA_ "GenSigTimeoutTime_AGSM" SG_ 728 Obj02_HorPosRight 0;
BA_ "GenSigTimeoutTime_ADCAM" SG_ 728 Obj02_HorPosRight 0;
BA_ "GenSigStartValue" SG_ 728 Obj02_HorPosRight 4092;
BA_ "GenSigTimeoutTime_SGW" SG_ 728 Obj02_HorPosLeft 0;
BA_ "GenSigTimeoutTime_RFHM" SG_ 728 Obj02_HorPosLeft 0;
BA_ "GenSigTimeoutTime_MPAD" SG_ 728 Obj02_HorPosLeft 0;
BA_ "GenSigTimeoutTime_IPC" SG_ 728 Obj02_HorPosLeft 0;
BA_ "GenSigTimeoutTime_GNMM" SG_ 728 Obj02_HorPosLeft 0;
BA_ "GenSigTimeoutTime_EVCU2" SG_ 728 Obj02_HorPosLeft 0;
BA_ "GenSigTimeoutTime_ESL" SG_ 728 Obj02_HorPosLeft 0;
BA_ "GenSigTimeoutTime_ECM" SG_ 728 Obj02_HorPosLeft 0;
BA_ "GenSigTimeoutTime_DTCM" SG_ 728 Obj02_HorPosLeft 0;
BA_ "GenSigTimeoutTime_DMSM" SG_ 728 Obj02_HorPosLeft 0;
BA_ "GenSigTimeoutTime_BSM" SG_ 728 Obj02_HorPosLeft 0;
BA_ "GenSigTimeoutTime_AGSM" SG_ 728 Obj02_HorPosLeft 0;
BA_ "GenSigTimeoutTime_ADCAM" SG_ 728 Obj02_HorPosLeft 0;
BA_ "GenSigStartValue" SG_ 728 Obj02_HorPosLeft 4092;
BA_ "GenSigTimeoutTime_IPC" SG_ 728 Obj01_VerPos 0;
BA_ "GenSigTimeoutTime_GNMM" SG_ 728 Obj01_VerPos 0;
BA_ "GenSigTimeoutTime_EVCU2" SG_ 728 Obj01_VerPos 0;
BA_ "GenSigTimeoutTime_ESL" SG_ 728 Obj01_VerPos 0;
BA_ "GenSigTimeoutTime_ECM" SG_ 728 Obj01_VerPos 0;
BA_ "GenSigTimeoutTime_DTCM" SG_ 728 Obj01_VerPos 0;
BA_ "GenSigTimeoutTime_DMSM" SG_ 728 Obj01_VerPos 0;
BA_ "GenSigTimeoutTime_BSM" SG_ 728 Obj01_VerPos 0;
BA_ "GenSigTimeoutTime_AGSM" SG_ 728 Obj01_VerPos 0;
BA_ "GenSigTimeoutTime_ADCAM" SG_ 728 Obj01_VerPos 0;
BA_ "GenSigStartValue" SG_ 728 Obj01_VerPos 251;
BA_ "GenSigTimeoutTime_SGW" SG_ 728 Obj01_VerPos 0;
BA_ "GenSigTimeoutTime_RFHM" SG_ 728 Obj01_VerPos 0;
BA_ "GenSigTimeoutTime_MPAD" SG_ 728 Obj01_VerPos 0;
BA_ "GenSigTimeoutTime_SGW" SG_ 728 Obj01_ID 0;
BA_ "GenSigTimeoutTime_RFHM" SG_ 728 Obj01_ID 0;
BA_ "GenSigTimeoutTime_MPAD" SG_ 728 Obj01_ID 0;
BA_ "GenSigTimeoutTime_IPC" SG_ 728 Obj01_ID 0;
BA_ "GenSigTimeoutTime_GNMM" SG_ 728 Obj01_ID 0;
BA_ "GenSigTimeoutTime_EVCU2" SG_ 728 Obj01_ID 0;
BA_ "GenSigTimeoutTime_ESL" SG_ 728 Obj01_ID 0;
BA_ "GenSigTimeoutTime_ECM" SG_ 728 Obj01_ID 0;
BA_ "GenSigTimeoutTime_DTCM" SG_ 728 Obj01_ID 0;
BA_ "GenSigTimeoutTime_DMSM" SG_ 728 Obj01_ID 0;
BA_ "GenSigTimeoutTime_IPC" SG_ 728 Obj04_HorPosLeft 0;
BA_ "GenSigTimeoutTime_GNMM" SG_ 728 Obj04_HorPosLeft 0;
BA_ "GenSigTimeoutTime_EVCU2" SG_ 728 Obj04_HorPosLeft 0;
BA_ "GenSigTimeoutTime_ESL" SG_ 728 Obj04_HorPosLeft 0;
BA_ "GenSigTimeoutTime_ECM" SG_ 728 Obj04_HorPosLeft 0;
BA_ "GenSigTimeoutTime_DTCM" SG_ 728 Obj04_HorPosLeft 0;
BA_ "GenSigTimeoutTime_DMSM" SG_ 728 Obj04_HorPosLeft 0;
BA_ "GenSigTimeoutTime_BSM" SG_ 728 Obj04_HorPosLeft 0;
BA_ "GenSigTimeoutTime_AGSM" SG_ 728 Obj04_HorPosLeft 0;
BA_ "GenSigTimeoutTime_ADCAM" SG_ 728 Obj04_HorPosLeft 0;
BA_ "GenSigStartValue" SG_ 728 Obj04_HorPosLeft 4092;
BA_ "GenSigTimeoutTime_SGW" SG_ 280 MessageCounter_ADAS_FD_INFO 0;
BA_ "GenSigTimeoutTime_RFHM" SG_ 280 MessageCounter_ADAS_FD_INFO 0;
BA_ "GenSigTimeoutTime_MPAD" SG_ 280 MessageCounter_ADAS_FD_INFO 0;
BA_ "GenSigTimeoutTime_GNMM" SG_ 280 MessageCounter_ADAS_FD_INFO 0;
BA_ "GenSigTimeoutTime_ESL" SG_ 280 MessageCounter_ADAS_FD_INFO 0;
BA_ "GenSigTimeoutTime_SGW" SG_ 280 Object_Dist 0;
BA_ "GenSigTimeoutTime_RFHM" SG_ 280 Object_Dist 0;
BA_ "GenSigTimeoutTime_MPAD" SG_ 280 Object_Dist 0;
BA_ "GenSigTimeoutTime_IPC" SG_ 280 Object_Dist 0;
BA_ "GenSigTimeoutTime_GNMM" SG_ 280 Object_Dist 0;
BA_ "GenSigTimeoutTime_EVCU2" SG_ 280 Object_Dist 0;
BA_ "GenSigTimeoutTime_ESL" SG_ 280 Object_Dist 0;
BA_ "GenSigTimeoutTime_ECM" SG_ 280 Object_Dist 0;
BA_ "GenSigTimeoutTime_DTCM" SG_ 280 Object_Dist 0;
BA_ "GenSigTimeoutTime_DMSM" SG_ 280 Object_Dist 0;
BA_ "GenSigTimeoutTime_AGSM" SG_ 280 Object_Dist 0;
BA_ "GenSigTimeoutTime_ADCAM" SG_ 280 Object_Dist 0;
BA_ "GenSigStartValue" SG_ 280 Object_Dist 255;
BA_ "GenSigTimeoutTime_ECM" SG_ 280 MessageCounter_ADAS_FD_INFO 0;
BA_ "GenSigTimeoutTime_DTCM" SG_ 280 MessageCounter_ADAS_FD_INFO 0;
BA_ "GenSigTimeoutTime_DMSM" SG_ 280 MessageCounter_ADAS_FD_INFO 0;
BA_ "GenSigTimeoutTime_AGSM" SG_ 280 MessageCounter_ADAS_FD_INFO 0;
BA_ "GenSigTimeoutTime_SGW" SG_ 280 CRC_ADAS_FD_INFO 0;
BA_ "GenSigTimeoutTime_RFHM" SG_ 280 CRC_ADAS_FD_INFO 0;
BA_ "GenSigTimeoutTime_MPAD" SG_ 280 CRC_ADAS_FD_INFO 0;
BA_ "GenSigTimeoutTime_GNMM" SG_ 280 CRC_ADAS_FD_INFO 0;
BA_ "GenSigTimeoutTime_ESL" SG_ 280 CRC_ADAS_FD_INFO 0;
BA_ "GenSigTimeoutTime_ECM" SG_ 280 CRC_ADAS_FD_INFO 0;
BA_ "GenSigTimeoutTime_DTCM" SG_ 280 CRC_ADAS_FD_INFO 0;
BA_ "GenSigTimeoutTime_DMSM" SG_ 280 CRC_ADAS_FD_INFO 0;
BA_ "GenSigTimeoutTime_AGSM" SG_ 280 CRC_ADAS_FD_INFO 0;
BA_ "GenSigStartValue" SG_ 728 Obj01_ID 254;
BA_ "GenSigTimeoutTime_SGW" SG_ 728 Obj01_HorSpeed 0;
BA_ "GenSigTimeoutTime_RFHM" SG_ 728 Obj01_HorSpeed 0;
BA_ "GenSigTimeoutTime_MPAD" SG_ 728 Obj01_HorSpeed 0;
BA_ "GenSigTimeoutTime_IPC" SG_ 728 Obj01_HorSpeed 0;
BA_ "GenSigTimeoutTime_GNMM" SG_ 728 Obj01_HorSpeed 0;
BA_ "GenSigTimeoutTime_EVCU2" SG_ 728 Obj01_HorSpeed 0;
BA_ "GenSigTimeoutTime_ESL" SG_ 728 Obj01_HorSpeed 0;
BA_ "GenSigTimeoutTime_ECM" SG_ 728 Obj01_HorSpeed 0;
BA_ "GenSigTimeoutTime_DTCM" SG_ 728 Obj01_HorSpeed 0;
BA_ "GenSigTimeoutTime_DMSM" SG_ 728 Obj01_HorSpeed 0;
BA_ "GenSigTimeoutTime_BSM" SG_ 728 Obj01_HorSpeed 0;
BA_ "GenSigTimeoutTime_AGSM" SG_ 728 Obj01_HorSpeed 0;
BA_ "GenSigTimeoutTime_ADCAM" SG_ 728 Obj01_HorSpeed 0;
BA_ "GenSigStartValue" SG_ 728 Obj01_HorSpeed 4092;
BA_ "GenSigTimeoutTime_SGW" SG_ 728 Obj01_HorPosRight 0;
BA_ "GenSigTimeoutTime_RFHM" SG_ 728 Obj01_HorPosRight 0;
BA_ "GenSigTimeoutTime_MPAD" SG_ 728 Obj01_HorPosRight 0;
BA_ "GenSigTimeoutTime_IPC" SG_ 728 Obj01_HorPosRight 0;
BA_ "GenSigTimeoutTime_GNMM" SG_ 728 Obj01_HorPosRight 0;
BA_ "GenSigTimeoutTime_EVCU2" SG_ 728 Obj01_HorPosRight 0;
BA_ "GenSigTimeoutTime_ESL" SG_ 728 Obj01_HorPosRight 0;
BA_ "GenSigTimeoutTime_ECM" SG_ 728 Obj01_HorPosRight 0;
BA_ "GenSigTimeoutTime_DTCM" SG_ 728 Obj01_HorPosRight 0;
BA_ "GenSigTimeoutTime_DMSM" SG_ 728 Obj01_HorPosRight 0;
BA_ "GenSigTimeoutTime_BSM" SG_ 728 Obj01_HorPosRight 0;
BA_ "GenSigTimeoutTime_AGSM" SG_ 728 Obj01_HorPosRight 0;
BA_ "GenSigTimeoutTime_ADCAM" SG_ 728 Obj01_HorPosRight 0;
BA_ "GenSigStartValue" SG_ 728 Obj01_HorPosRight 4092;
BA_ "GenSigTimeoutTime_SGW" SG_ 728 Obj01_HorPosLeft 0;
BA_ "GenSigTimeoutTime_RFHM" SG_ 728 Obj01_HorPosLeft 0;
BA_ "GenSigTimeoutTime_MPAD" SG_ 728 Obj01_HorPosLeft 0;
BA_ "GenSigTimeoutTime_IPC" SG_ 728 Obj01_HorPosLeft 0;
BA_ "GenSigTimeoutTime_GNMM" SG_ 728 Obj01_HorPosLeft 0;
BA_ "GenSigTimeoutTime_EVCU2" SG_ 728 Obj01_HorPosLeft 0;
BA_ "GenSigTimeoutTime_ESL" SG_ 728 Obj01_HorPosLeft 0;
BA_ "GenSigTimeoutTime_ECM" SG_ 728 Obj01_HorPosLeft 0;
BA_ "GenSigTimeoutTime_DTCM" SG_ 728 Obj01_HorPosLeft 0;
BA_ "GenSigTimeoutTime_DMSM" SG_ 728 Obj01_HorPosLeft 0;
BA_ "GenSigTimeoutTime_BSM" SG_ 728 Obj01_HorPosLeft 0;
BA_ "GenSigTimeoutTime_AGSM" SG_ 728 Obj01_HorPosLeft 0;
BA_ "GenSigTimeoutTime_ADCAM" SG_ 728 Obj01_HorPosLeft 0;
BA_ "GenSigStartValue" SG_ 728 Obj01_HorPosLeft 4092;
VAL_ 280 Object_Dist 255 "SNA";
VAL_ 280 Intervention 4095 "SNA";
VAL_ 280 HIS_Req 0 "Not_Active" 1 "Active";
VAL_ 280 GrMax_Rq_ACC 0 "Passive" 1 "G1" 2 "G2" 3 "G3" 4 "G4" 5 "G5" 6 "G6" 7 "G7" 8 "G8" 9 "G9" 10 "G10" 11 "G11" 12 "G12" 13 "G13" 14 "G14" 15 "G15";
VAL_ 280 CIPV_Fused 0 "Not_Active" 1 "Active";
VAL_ 280 Brake_Jerk_Req 0 "Not_Active" 1 "Active";
VAL_ 280 ACC_Engine_Torque_Enabled 0 "Not_Enabled" 1 "Enabled";
VAL_ 280 ACC_Drive_Cmd 0 "Not_Enabled" 1 "Enabled";
VAL_ 525 VerticalAcceleration_GNMM 4095 "SNA";
VAL_ 525 RollRate_GNMM 4095 "SNA";
VAL_ 525 PitchRate_GNMM 4095 "SNA";
VAL_ 525 LongAcceleration_GNMM 4095 "SNA";
VAL_ 525 LatAcceleration_GNMM 4095 "SNA";
VAL_ 525 GNMM_Health 0 "Not_Avail" 1 "Avail_full_capacity" 2 "Primary_IMU_NA" 3 "GPS_GNSS_NA" 4 "Correction_Data_NA" 7 "SNA";
VAL_ 1470 DriverSeatRelativePosition 255 "SNA";
VAL_ 1470 DriverSeatReclinerButton 0 "Not_Pressed" 1 "Recline_forward" 2 "Recline_back" 3 "SNA";
VAL_ 1470 DriverSeatHorizontalButton 0 "Not_Pressed" 1 "Slide_Fore" 2 "Slide_Aft" 3 "SNA";
VAL_ 1470 DriverReclineRelativePosition 255 "SNA";
VAL_ 281 MRM_STATUS_C2 0 "Not_Active" 1 "MRM_in_Process" 2 "Vehicle_Secure_Request" 3 "Vehicle_Securement_Complete" 4 "Canceled" 7 "SNA";
VAL_ 281 HAS_Status_C2 0 "Disabled" 1 "Enabled" 2 "Engaged" 3 "Faulted";
VAL_ 281 AEB_Type_C2 0 "NONE" 1 "ACC" 2 "CMS" 3 "CMS_XTD" 4 "ABA" 5 "LSCM" 6 "PEB" 7 "ICA_L" 8 "ICA_R" 9 "HAS_MRM" 11 "L3" 15 "SNA";
VAL_ 280 Prefill_Req 0 "No_Prefill_Requested" 1 "Prefill_Requested";
VAL_ 280 PEB_SystemSts 0 "OFF" 1 "ON";
VAL_ 280 MRM_STATUS 0 "Not_Active" 1 "MRM_in_Process" 2 "Vehicle_Secure_Request" 3 "Vehicle_Securement_Complete" 4 "Canceled" 7 "SNA";
VAL_ 280 LANE_CHANGE_SIDE 0 "NO_CHNG" 1 "RIGHT" 2 "LEFT";
VAL_ 280 HAS_Status 0 "Disabled" 1 "Enabled" 2 "Engaged" 3 "Faulted";
VAL_ 280 HAS_OpStat_Prim 0 "Inactive" 1 "FullService" 2 "FailOperational" 3 "FailDegraded" 4 "Emergency" 5 "No_Function";
VAL_ 280 HAS_LAT_CTRL_RequestSts 0 "Idle" 1 "Faulted" 2 "HAS_Request";
VAL_ 280 ESCALATION_TYPE 0 "None" 1 "Driver_Inattention" 2 "Low_Urgency" 3 "Med_Urgency" 4 "High_Urgency";
VAL_ 280 DDD_SystemSts 0 "OFF" 1 "ON";
VAL_ 280 DDD_Setting_Avail 0 "Available" 1 "Not_Available";
VAL_ 280 CADM_OpStat 0 "Inactive" 1 "FullService" 2 "FailOperational" 3 "FailDegraded" 4 "Emergency" 5 "No_Function";
VAL_ 280 AEB_Type 0 "NONE" 1 "ACC" 2 "CMS" 3 "CMS_XTD" 4 "ABA" 5 "LSCM" 6 "PEB" 7 "ICA_L" 8 "ICA_R" 9 "HAS_MRM" 10 "RRCC" 11 "L3" 15 "SNA";
VAL_ 280 AEB_Systemsts 0 "FCW_Off" 1 "FCW_On_Only_Warning" 2 "FCW_On_Full";
VAL_ 280 AEB_Sensitivity_Setting 0 "NEAR" 1 "MEDIUM" 2 "FAR";
VAL_ 280 ACC_Systemsts 0 "OFF" 1 "ACC_Enabled" 2 "ACC_Engaged" 3 "ACC_Engaged_BrakeOnly" 4 "ACC_Cancel" 5 "NCC_Enabled" 6 "NCC_Engaged" 7 "NCC_Cancel" 8 "HAS_BSoC" 9 "RRCC_Enabled_No_Set_Speed" 10 "RRCC_Enabled_With_Set_Speed" 11 "RRCC_Engaged" 12 "L3_Engaged" 13 "L3_Disengaged" 15 "SNA";
VAL_ 280 ACC_StopStart 0 "DEFAULT" 1 "AutoStop_Allowed" 2 "AutoStart_Allowed" 3 "SNA";
VAL_ 280 SteeringVibration_Type 0 "TYPE_0" 1 "TYPE_1" 2 "TYPE_2" 3 "TYPE_3" 4 "TYPE_4" 5 "TYPE_5" 6 "TYPE_6" 7 "TYPE_7" 8 "TYPE_8" 9 "TYPE_9" 10 "TYPE_10" 11 "TYPE_11" 15 "SNA";
VAL_ 280 SteeringVibration_Rq 0 "NOT_REQUESTED" 1 "REQUESTED";
VAL_ 280 LKA_LAT_CTRL_RequestSts 0 "Idle" 1 "Faulted" 2 "LKA_Request";
VAL_ 280 LANE_CHANGE_STATUS 0 "NO_CHNG" 1 "PEND" 2 "EARLY1" 3 "EARLY2" 4 "LATE" 5 "ABORTING" 6 "ABORTED" 7 "COMPL" 8 "LOCKOUT" 9 "CANCELLING" 10 "CANCELLED" 11 "Lane_Change_Avail_Indication" 12 "Msg_12" 13 "Msg_13" 14 "Msg_14" 15 "SNA";
VAL_ 525 YawRate_RMSE 254 "OutOfRange" 255 "SNA";
VAL_ 525 Roll_RMSE 254 "OutOfRange" 255 "SNA";
VAL_ 525 Pitch_RMSE 254 "OutOfRange" 255 "SNA";
VAL_ 525 Longitude_RMSE 254 "OutOfRange" 255 "SNA";
VAL_ 525 Latitude_RMSE 254 "OutOfRange" 255 "SNA";
VAL_ 525 Heading_Angle 65535 "SNA";
VAL_ 525 Altitude_RMSE 254 "OutOfRange" 255 "SNA";
VAL_ 161 undervoltage_detected 0 "No_Fault" 1 "Under_Voltage";
VAL_ 161 switch_status_OpenClose 0 "Open" 1 "Close";
VAL_ 161 RsErr_DBSM2 0 "No_Error" 1 "Error";
VAL_ 161 overtemp_detected 0 "No_Fault" 1 "Over_Temp";
VAL_ 161 overcurrent_detected 0 "No_Fault" 1 "Over_Current";
VAL_ 161 L2plus_ack 0 "Inactive" 1 "L2plus_mode_active";
VAL_ 161 ESS_input_active 0 "ESS_NotActivated" 1 "ESS_Activated";
VAL_ 161 DBSM2_internal_error 0 "No_Error" 1 "Internal_Error";
VAL_ 161 BATTERY2_voltage 255 "SNA";
VAL_ 161 BATTERY_voltage 255 "SNA";
VAL_ 1470 SeatPosHAS 0 "INIT" 1 "Healthy" 2 "Healthy_Counting" 3 "Faulted";
VAL_ 281 Intervention_C2 4095 "SNA";
VAL_ 281 HIS_Req_C2 0 "Not_Active" 1 "Active";
VAL_ 281 ACC_Systemsts_C2 0 "OFF" 1 "ACC_Enabled" 2 "ACC_Engaged" 3 "ACC_Engaged_BrakeOnly" 4 "ACC_Cancel" 5 "NCC_Enabled" 6 "NCC_Engaged" 7 "NCC_Cancel" 8 "HAS_BSoC" 12 "L3_Engaged" 13 "L3_Disengaged" 15 "SNA";
VAL_ 280 SeatVib_Req 0 "No_Request" 1 "Type_1" 2 "Type_2" 3 "Type_3" 4 "Type_4";
VAL_ 280 LC_Jerk 0 "Not_Active" 1 "Active";
VAL_ 1458 ACC_FailSts_C2 0 "Fail_Not_Present" 1 "Fail_Present";
VAL_ 525 YawRate_GNMM 32767 "SNA";
VAL_ 525 VerticalVelocity_GNMM 16383 "SNA";
VAL_ 525 LongitudinalVelocity_GNMM 16383 "SNA";
VAL_ 525 LateralVelocity_GNMM 16383 "SNA";
VAL_ 525 Long_GNMM 4294967295 "SNA";
VAL_ 525 Lat_GNMM 4294967295 "SNA";
VAL_ 281 CADM2_Mode 0 "Gate" 1 "Control";
VAL_ 280 CADM2_EPSSEC_FAIL 0 "False" 1 "True";
VAL_ 728 Road_Illumination 0 "Not_Detected" 1 "Detected" 14 "Init";
VAL_ 728 Obj04_Type 0 "No_Object" 1 "Oncoming_Object" 2 "Preceding_Object" 3 "Oncoming_Object_Predicted" 4 "Preceding_Object_Predicted" 5 "Oncoming_Clustered" 6 "Preceding_Clustered" 14 "Init";
VAL_ 728 Obj04_HorDist 251 "Object_Pos_Exceeded" 254 "Init";
VAL_ 728 Obj03_Type 0 "No_Object" 1 "Oncoming_Object" 2 "Preceding_Object" 3 "Oncoming_Object_Predicted" 4 "Preceding_Object_Predicted" 5 "Oncoming_Clustered" 6 "Preceding_Clustered" 14 "Init";
VAL_ 728 Obj03_HorDist 251 "Object_Pos_Exceeded" 254 "Init";
VAL_ 728 Obj02_Type 0 "No_Object" 1 "Oncoming_Object" 2 "Preceding_Object" 3 "Oncoming_Object_Predicted" 4 "Preceding_Object_Predicted" 5 "Oncoming_Clustered" 6 "Preceding_Clustered" 14 "Init";
VAL_ 728 Obj02_HorDist 251 "Object_Pos_Exceeded" 254 "Init";
VAL_ 728 Obj01_Type 0 "No_Object" 1 "Oncoming_Object" 2 "Preceding_Object" 3 "Oncoming_Object_Predicted" 4 "Preceding_Object_Predicted" 5 "Oncoming_Clustered" 6 "Preceding_Clustered" 14 "Init";
VAL_ 728 Obj01_HorDist 251 "Object_Pos_Exceeded" 254 "Init";
VAL_ 728 Cam_TrafficStyle 0 "Unknown" 1 "RHT" 2 "LHT" 14 "Init";
VAL_ 728 Cam_Status 0 "ON_Passive" 1 "ON_Active" 2 "ON_Reduced_Sight" 3 "ON_Failure" 4 "OFF" 14 "Init";
VAL_ 728 Cam_SelfGlaring 0 "Not_Detected" 1 "10_19" 2 "20_29" 3 "30_39" 4 "40_49" 5 "50_59" 6 "60_69" 7 "70_79" 8 "80_89" 9 "90_99" 10 "100" 14 "Init";
VAL_ 728 Cam_ObjNum 0 "No_Objects_Detected" 1 "ObjectNum_1" 2 "ObjectNum_2" 3 "ObjectNum_3" 4 "ObjectNum_4" 11 "More_than_4_detected" 14 "Init";
VAL_ 1458 SVI_Request_C2_ext 0 "OFF" 1 "Green" 2 "YELLOW" 3 "Red" 4 "Blue";
VAL_ 728 Cam_Env 0 "Unknown" 1 "City" 2 "Country_Road" 3 "Motorway_Dual_Carriageway" 15 "SNA";
VAL_ 728 Cam_AmbientLight 0 "Unknown" 1 "Day" 2 "Night" 14 "Init";
VAL_ 728 Obj04_VerPos 251 "Init";
VAL_ 728 Obj04_ID 0 "No_Object_Detected" 255 "Init";
VAL_ 728 Obj04_HorSpeed 4092 "Init";
VAL_ 728 Obj04_HorPosRight 4092 "Init";
VAL_ 728 Obj04_HorPosLeft 4092 "Init";
VAL_ 728 Obj03_VerPos 251 "Init";
VAL_ 728 Obj03_ID 0 "No_Object_Detected" 255 "Init";
VAL_ 728 Obj03_HorSpeed 4092 "Init";
VAL_ 728 Obj03_HorPosRight 4092 "Init";
VAL_ 728 Obj03_HorPosLeft 4092 "Init";
VAL_ 728 Obj02_VerPos 251 "Init";
VAL_ 728 Obj02_ID 0 "No_Object_Detected" 255 "Init";
VAL_ 728 Obj02_HorSpeed 4092 "Init";
VAL_ 728 Obj02_HorPosRight 4092 "Init";
VAL_ 728 Obj02_HorPosLeft 4092 "Init";
VAL_ 728 Obj01_VerPos 251 "Init";
VAL_ 728 Obj01_ID 0 "No_Object_Detected" 255 "Init";
VAL_ 728 Obj01_HorSpeed 4092 "Init";
VAL_ 728 Obj01_HorPosRight 4092 "Init";
VAL_ 728 Obj01_HorPosLeft 4092 "Init";
VAL_ 280 BlindSpot_TrailerSts 0 "NONE" 1 "TRAILER_0_3" 2 "TRAILER_3_6" 3 "TRAILER_6_9" 4 "TRAILER_MAX" 5 "TRAILER_AUTO" 7 "SNA";
VAL_ 525 StbmSyncState_GNMM 0 "IN_SYNC" 1 "NOT_IN_SYNC" 255 "INVALID";
VAL_ 525 StatusReceiver 0 "Insufficient_reception" 1 "Optimal_reception" 3 "SNA";
VAL_ 525 NumOfSatellites 15 "SNA";
VAL_ 525 IMUTemperature 255 "SNA";
VAL_ 525 HDOP 4095 "SNA";
VAL_ 525 FixedStatusReceiver 0 "NO_FIX" 1 "POS_2D_FIX" 2 "POS_3D_FIX" 3 "SNA";
VAL_ 525 CourseAngle 65535 "SNA";
SIG_GROUP_ 281 ADAS_FD_INFO_C2_Pkt 1 : MRM_STATUS_C2 MessageCounter_ADAS_INFO_C2 HAS_Status_C2 CRC_ADAS_INFO_C2 AEB_Type_C2 Intervention_C2 HIS_Req_C2 ACC_Systemsts_C2 CADM2_Mode;
SIG_GROUP_ 280 ADAS_FD_INFO_Pkt 1 : Object_Dist MessageCounter_ADAS_FD_INFO CRC_ADAS_FD_INFO Intervention HIS_Req GrMax_Rq_ACC CIPV_Fused Brake_Jerk_Req ACC_Engine_Torque_Enabled ACC_Drive_Cmd Prefill_Req PEB_SystemSts MRM_STATUS LANE_CHANGE_SIDE HAS_Status HAS_OpStat_Prim HAS_LAT_CTRL_RequestSts ESCALATION_TYPE DDD_SystemSts DDD_Setting_Avail CADM_OpStat AEB_Type AEB_Systemsts AEB_Sensitivity_Setting ACC_Systemsts ACC_StopStart SteeringVibration_Type SteeringVibration_Rq LKA_LAT_CTRL_RequestSts LANE_CHANGE_STATUS SeatVib_Req LC_Jerk CADM2_EPSSEC_FAIL BlindSpot_TrailerSts TorqueOverlaySteeringReq MAC_ADAS_FD_INFO Cntr_ADAS_FD_INFO;
